VERSION "HINBNNNYYNNNYYNNNNNNNNNNNNYNNNYYYNNYNNNNNN/4//%%/4/'%**4NNN///"

NS_ :

BS_:

BU_: VirtualNMTMaster VCU

BO_ 1800 HBGuard_008: 1 VCU
 SG_ Toggle : 7|1@1+ (1,0) [0|0] "" Vector__XXX
 SG_ State : 0|7@1+ (1,0) [0|0] "" Vector__XXX

BO_ 1416 SSDO_008: 8 VCU
 SG_ Joe_6003_04 m4 : 32|16@1- (1,0) [-32768|32767] "" Vector__XXX
 SG_ Currly_6003_03 m3 : 32|16@1- (1,0) [-32768|32767] "" Vector__XXX
 SG_ Moe_6003_02 m2 : 32|16@1- (1,0) [-32768|32767] "" Vector__XXX
 SG_ Bob_6003_01 m1 : 32|16@1- (1,0) [-32768|32767] "" Vector__XXX
 SG_ UC_STATE_6003_00 m0 : 32|16@1- (1,0) [-32768|32767] "" Vector__XXX
 SG_ SubIndex_6003 m24579M : 24|8@1+ (1,0) [0|4] "" Vector__XXX
 SG_ Harp_Bit_3_6002_03 m3 : 32|1@1+ (1,0) [0|1] "" Vector__XXX
 SG_ Harp_Bit_2_6002_02 m2 : 32|1@1+ (1,0) [0|1] "" Vector__XXX
 SG_ Harp_Bit_1_6002_01 m1 : 32|1@1+ (1,0) [0|1] "" Vector__XXX
 SG_ Harp_Bit_0_6002_00 m0 : 32|1@1+ (1,0) [0|1] "" Vector__XXX
 SG_ SubIndex_6002 m24578M : 24|8@1+ (1,0) [0|3] "" Vector__XXX
 SG_ Throttle_6001_03 m3 : 32|16@1- (1,0) [-32768|32767] "" Vector__XXX
 SG_ Start_6001_02 m2 : 32|1@1+ (1,0) [0|1] "" Vector__XXX
 SG_ Brake_6001_01 m1 : 32|16@1- (1,0) [0|494967295] "" Vector__XXX
 SG_ Forward_Enable_6001_00 m0 : 32|1@1+ (1,0) [0|494967295] "" Vector__XXX
 SG_ SubIndex_6001 m24577M : 24|8@1+ (1,0) [0|3] "" Vector__XXX
 SG_ PDOMapEntry_1A03_01 m1 : 32|32@1+ (1,0) [0|4294967295] "" Vector__XXX
 SG_ NrOfEntries_1_1A03_00 m0 : 32|8@1+ (1,0) [0|2] "" Vector__XXX
 SG_ SubIndex_1A03 m6659M : 24|8@1+ (1,0) [0|1] "" Vector__XXX
 SG_ Transmit_PDO_Mapping_Parameter_0 m4 : 32|32@1+ (1,0) [0|4294967295] "" Vector__XXX
 SG_ PDOMapEntry_1A02_03 m3 : 32|32@1+ (1,0) [0|4294967295] "" Vector__XXX
 SG_ PDOMapEntry_1A02_02 m2 : 32|32@1+ (1,0) [0|4294967295] "" Vector__XXX
 SG_ PDOMapEntry_1A02_01 m1 : 32|32@1+ (1,0) [0|4294967295] "" Vector__XXX
 SG_ NrOfEntries_1_1A02_00 m0 : 32|8@1+ (1,0) [0|2] "" Vector__XXX
 SG_ SubIndex_1A02 m6658M : 24|8@1+ (1,0) [0|4] "" Vector__XXX
 SG_ Transmit_PDO_Mapping_Parame_0000 m4 : 32|32@1+ (1,0) [0|4294967295] "" Vector__XXX
 SG_ PDOMapEntry_1A01_03 m3 : 32|32@1+ (1,0) [0|4294967295] "" Vector__XXX
 SG_ PDOMapEntry_1A01_02 m2 : 32|32@1+ (1,0) [0|4294967295] "" Vector__XXX
 SG_ PDOMapEntry_1A01_01 m1 : 32|32@1+ (1,0) [0|4294967295] "" Vector__XXX
 SG_ NrOfEntries_1_1A01_00 m0 : 32|8@1+ (1,0) [0|2] "" Vector__XXX
 SG_ SubIndex_1A01 m6657M : 24|8@1+ (1,0) [0|4] "" Vector__XXX
 SG_ Transmit_PDO_Mapping_Parame_0001 m4 : 32|32@1+ (1,0) [0|4294967295] "" Vector__XXX
 SG_ Transmit_PDO_Mapping_Parame_0002 m3 : 32|32@1+ (1,0) [0|4294967295] "" Vector__XXX
 SG_ PDOMapEntry_2_1A00_02 m2 : 32|32@1+ (1,0) [0|4294967295] "" Vector__XXX
 SG_ PDOMapEntry_1_1A00_01 m1 : 32|32@1+ (1,0) [0|4294967295] "" Vector__XXX
 SG_ NrOfEntries_1_1A00_00 m0 : 32|8@1+ (1,0) [0|2] "" Vector__XXX
 SG_ SubIndex_1A00 m6656M : 24|8@1+ (1,0) [0|4] "" Vector__XXX
 SG_ SYNC_start_value_1803_06 m6 : 32|8@1+ (1,0) [0|255] "" Vector__XXX
 SG_ Event_Timer_1803_05 m5 : 32|16@1+ (1,0) [0|65535] "" Vector__XXX
 SG_ Compatibility_Entry_1803_04 m4 : 32|8@1+ (1,0) [0|255] "" Vector__XXX
 SG_ Inhibit_Time_1803_03 m3 : 32|16@1+ (1,0) [0|65535] "" Vector__XXX
 SG_ TransmissionType_1803_02 m2 : 32|8@1+ (1,0) [0|255] "" Vector__XXX
 SG_ COB_ID_1803_01 m1 : 32|32@1+ (1,0) [0|4294967295] "" Vector__XXX
 SG_ Highest_sub_index_supported_1803 m0 : 32|8@1+ (1,0) [2|6] "" Vector__XXX
 SG_ SubIndex_1803 m6147M : 24|8@1+ (1,0) [0|6] "" Vector__XXX
 SG_ SYNC_start_value_1802_06 m6 : 32|8@1+ (1,0) [0|255] "" Vector__XXX
 SG_ Event_Timer_1802_05 m5 : 32|16@1+ (1,0) [0|65535] "" Vector__XXX
 SG_ Compatibility_Entry_1802_04 m4 : 32|8@1+ (1,0) [0|255] "" Vector__XXX
 SG_ Inhibit_Time_1802_03 m3 : 32|16@1+ (1,0) [0|65535] "" Vector__XXX
 SG_ TransmissionType_1802_02 m2 : 32|8@1+ (1,0) [0|255] "" Vector__XXX
 SG_ COB_ID_1802_01 m1 : 32|32@1+ (1,0) [0|4294967295] "" Vector__XXX
 SG_ Highest_sub_index_supported_1802 m0 : 32|8@1+ (1,0) [2|6] "" Vector__XXX
 SG_ SubIndex_1802 m6146M : 24|8@1+ (1,0) [0|6] "" Vector__XXX
 SG_ SYNC_start_value_1801_06 m6 : 32|8@1+ (1,0) [0|255] "" Vector__XXX
 SG_ Event_Timer_1801_05 m5 : 32|16@1+ (1,0) [0|65535] "" Vector__XXX
 SG_ Compatibility_Entry_1801_04 m4 : 32|8@1+ (1,0) [0|255] "" Vector__XXX
 SG_ Inhibit_Time_1801_03 m3 : 32|16@1+ (1,0) [0|65535] "" Vector__XXX
 SG_ TransmissionType_1801_02 m2 : 32|8@1+ (1,0) [0|255] "" Vector__XXX
 SG_ COB_ID_1801_01 m1 : 32|32@1+ (1,0) [0|4294967295] "" Vector__XXX
 SG_ Highest_sub_index_supported_1801 m0 : 32|8@1+ (1,0) [2|6] "" Vector__XXX
 SG_ SubIndex_1801 m6145M : 24|8@1+ (1,0) [0|6] "" Vector__XXX
 SG_ SYNC_start_value_1800_06 m6 : 32|8@1+ (1,0) [0|255] "" Vector__XXX
 SG_ Event_Timer_1800_05 m5 : 32|16@1+ (1,0) [0|65535] "" Vector__XXX
 SG_ Compatibility_Entry_1800_04 m4 : 32|8@1+ (1,0) [0|255] "" Vector__XXX
 SG_ Inhibit_Time_1800_03 m3 : 32|16@1+ (1,0) [0|65535] "" Vector__XXX
 SG_ TransmissionType_1800_02 m2 : 32|8@1+ (1,0) [0|255] "" Vector__XXX
 SG_ COB_ID_1800_01 m1 : 32|32@1+ (1,0) [0|4294967295] "" Vector__XXX
 SG_ Highest_sub_index_supported_1800 m0 : 32|8@1+ (1,0) [2|6] "" Vector__XXX
 SG_ SubIndex_1800 m6144M : 24|8@1+ (1,0) [0|6] "" Vector__XXX
 SG_ Serial_number_1018_04 m4 : 32|32@1+ (1,0) [0|4294967295] "" Vector__XXX
 SG_ Revision_number_1018_03 m3 : 32|32@1+ (1,0) [0|4294967295] "" Vector__XXX
 SG_ Product_Code_1018_02 m2 : 32|32@1+ (1,0) [0|4294967295] "" Vector__XXX
 SG_ Vendor_Id_1018_01 m1 : 32|32@1+ (1,0) [0|4294967295] "" Vector__XXX
 SG_ Highest_sub_index_supported_1018 m0 : 32|8@1+ (1,0) [1|4] "" Vector__XXX
 SG_ SubIndex_1018 m4120M : 24|8@1+ (1,0) [0|4] "" Vector__XXX
 SG_ Error_Register_1001 m0 : 32|8@1+ (1,0) [0|255] "" Vector__XXX
 SG_ SubIndex_1001 m4097M : 24|8@1+ (1,0) [0|0] "" Vector__XXX
 SG_ Device_Type_1000 m0 : 32|32@1+ (1,0) [0|4294967295] "" Vector__XXX
 SG_ SubIndex_1000 m4096M : 24|8@1+ (1,0) [0|0] "" Vector__XXX
 SG_ Index m1M : 8|16@1+ (1,0) [4096|24579] "" Vector__XXX
 SG_ TransferType m1M : 1|1@1+ (1,0) [0|1] "" Vector__XXX
 SG_ NotUsedBytes m1 : 2|2@1+ (1,0) [0|3] "" Vector__XXX
 SG_ SizeIndicator m1 : 0|1@1+ (1,0) [0|1] "" Vector__XXX
 SG_ SCS M : 5|3@1+ (1,0) [0|6] "" Vector__XXX

BO_ 1544 CSDO_008: 8 Vector__XXX
 SG_ Joe_6003_04 m4 : 32|16@1- (1,0) [-32768|32767] ""  VCU
 SG_ Currly_6003_03 m3 : 32|16@1- (1,0) [-32768|32767] ""  VCU
 SG_ Moe_6003_02 m2 : 32|16@1- (1,0) [-32768|32767] ""  VCU
 SG_ Bob_6003_01 m1 : 32|16@1- (1,0) [-32768|32767] ""  VCU
 SG_ UC_STATE_6003_00 m0 : 32|16@1- (1,0) [-32768|32767] ""  VCU
 SG_ SubIndex_6003 m24579M : 24|8@1+ (1,0) [0|4] ""  VCU
 SG_ Harp_Bit_3_6002_03 m3 : 32|1@1+ (1,0) [0|1] ""  VCU
 SG_ Harp_Bit_2_6002_02 m2 : 32|1@1+ (1,0) [0|1] ""  VCU
 SG_ Harp_Bit_1_6002_01 m1 : 32|1@1+ (1,0) [0|1] ""  VCU
 SG_ Harp_Bit_0_6002_00 m0 : 32|1@1+ (1,0) [0|1] ""  VCU
 SG_ SubIndex_6002 m24578M : 24|8@1+ (1,0) [0|3] ""  VCU
 SG_ Throttle_6001_03 m3 : 32|16@1- (1,0) [-32768|32767] ""  VCU
 SG_ Start_6001_02 m2 : 32|1@1+ (1,0) [0|1] ""  VCU
 SG_ Brake_6001_01 m1 : 32|16@1- (1,0) [0|494967295] ""  VCU
 SG_ Forward_Enable_6001_00 m0 : 32|1@1+ (1,0) [0|494967295] ""  VCU
 SG_ SubIndex_6001 m24577M : 24|8@1+ (1,0) [0|3] ""  VCU
 SG_ PDOMapEntry_1A03_01 m1 : 32|32@1+ (1,0) [0|4294967295] ""  VCU
 SG_ NrOfEntries_1_1A03_00 m0 : 32|8@1+ (1,0) [0|2] ""  VCU
 SG_ SubIndex_1A03 m6659M : 24|8@1+ (1,0) [0|1] ""  VCU
 SG_ Transmit_PDO_Mapping_Parame_0003 m4 : 32|32@1+ (1,0) [0|4294967295] ""  VCU
 SG_ PDOMapEntry_1A02_03 m3 : 32|32@1+ (1,0) [0|4294967295] ""  VCU
 SG_ PDOMapEntry_1A02_02 m2 : 32|32@1+ (1,0) [0|4294967295] ""  VCU
 SG_ PDOMapEntry_1A02_01 m1 : 32|32@1+ (1,0) [0|4294967295] ""  VCU
 SG_ NrOfEntries_1_1A02_00 m0 : 32|8@1+ (1,0) [0|2] ""  VCU
 SG_ SubIndex_1A02 m6658M : 24|8@1+ (1,0) [0|4] ""  VCU
 SG_ Transmit_PDO_Mapping_Parame_0004 m4 : 32|32@1+ (1,0) [0|4294967295] ""  VCU
 SG_ PDOMapEntry_1A01_03 m3 : 32|32@1+ (1,0) [0|4294967295] ""  VCU
 SG_ PDOMapEntry_1A01_02 m2 : 32|32@1+ (1,0) [0|4294967295] ""  VCU
 SG_ PDOMapEntry_1A01_01 m1 : 32|32@1+ (1,0) [0|4294967295] ""  VCU
 SG_ NrOfEntries_1_1A01_00 m0 : 32|8@1+ (1,0) [0|2] ""  VCU
 SG_ SubIndex_1A01 m6657M : 24|8@1+ (1,0) [0|4] ""  VCU
 SG_ Transmit_PDO_Mapping_Parame_0005 m4 : 32|32@1+ (1,0) [0|4294967295] ""  VCU
 SG_ Transmit_PDO_Mapping_Parame_0006 m3 : 32|32@1+ (1,0) [0|4294967295] ""  VCU
 SG_ PDOMapEntry_2_1A00_02 m2 : 32|32@1+ (1,0) [0|4294967295] ""  VCU
 SG_ PDOMapEntry_1_1A00_01 m1 : 32|32@1+ (1,0) [0|4294967295] ""  VCU
 SG_ NrOfEntries_1_1A00_00 m0 : 32|8@1+ (1,0) [0|2] ""  VCU
 SG_ SubIndex_1A00 m6656M : 24|8@1+ (1,0) [0|4] ""  VCU
 SG_ SYNC_start_value_1803_06 m6 : 32|8@1+ (1,0) [0|255] ""  VCU
 SG_ Event_Timer_1803_05 m5 : 32|16@1+ (1,0) [0|65535] ""  VCU
 SG_ Compatibility_Entry_1803_04 m4 : 32|8@1+ (1,0) [0|255] ""  VCU
 SG_ Inhibit_Time_1803_03 m3 : 32|16@1+ (1,0) [0|65535] ""  VCU
 SG_ TransmissionType_1803_02 m2 : 32|8@1+ (1,0) [0|255] ""  VCU
 SG_ COB_ID_1803_01 m1 : 32|32@1+ (1,0) [0|4294967295] ""  VCU
 SG_ Highest_sub_index_supported_0000 m0 : 32|8@1+ (1,0) [2|6] ""  VCU
 SG_ SubIndex_1803 m6147M : 24|8@1+ (1,0) [0|6] ""  VCU
 SG_ SYNC_start_value_1802_06 m6 : 32|8@1+ (1,0) [0|255] ""  VCU
 SG_ Event_Timer_1802_05 m5 : 32|16@1+ (1,0) [0|65535] ""  VCU
 SG_ Compatibility_Entry_1802_04 m4 : 32|8@1+ (1,0) [0|255] ""  VCU
 SG_ Inhibit_Time_1802_03 m3 : 32|16@1+ (1,0) [0|65535] ""  VCU
 SG_ TransmissionType_1802_02 m2 : 32|8@1+ (1,0) [0|255] ""  VCU
 SG_ COB_ID_1802_01 m1 : 32|32@1+ (1,0) [0|4294967295] ""  VCU
 SG_ Highest_sub_index_supported_0001 m0 : 32|8@1+ (1,0) [2|6] ""  VCU
 SG_ SubIndex_1802 m6146M : 24|8@1+ (1,0) [0|6] ""  VCU
 SG_ SYNC_start_value_1801_06 m6 : 32|8@1+ (1,0) [0|255] ""  VCU
 SG_ Event_Timer_1801_05 m5 : 32|16@1+ (1,0) [0|65535] ""  VCU
 SG_ Compatibility_Entry_1801_04 m4 : 32|8@1+ (1,0) [0|255] ""  VCU
 SG_ Inhibit_Time_1801_03 m3 : 32|16@1+ (1,0) [0|65535] ""  VCU
 SG_ TransmissionType_1801_02 m2 : 32|8@1+ (1,0) [0|255] ""  VCU
 SG_ COB_ID_1801_01 m1 : 32|32@1+ (1,0) [0|4294967295] ""  VCU
 SG_ Highest_sub_index_supported_0002 m0 : 32|8@1+ (1,0) [2|6] ""  VCU
 SG_ SubIndex_1801 m6145M : 24|8@1+ (1,0) [0|6] ""  VCU
 SG_ SYNC_start_value_1800_06 m6 : 32|8@1+ (1,0) [0|255] ""  VCU
 SG_ Event_Timer_1800_05 m5 : 32|16@1+ (1,0) [0|65535] ""  VCU
 SG_ Compatibility_Entry_1800_04 m4 : 32|8@1+ (1,0) [0|255] ""  VCU
 SG_ Inhibit_Time_1800_03 m3 : 32|16@1+ (1,0) [0|65535] ""  VCU
 SG_ TransmissionType_1800_02 m2 : 32|8@1+ (1,0) [0|255] ""  VCU
 SG_ COB_ID_1800_01 m1 : 32|32@1+ (1,0) [0|4294967295] ""  VCU
 SG_ Highest_sub_index_supported_0003 m0 : 32|8@1+ (1,0) [2|6] ""  VCU
 SG_ SubIndex_1800 m6144M : 24|8@1+ (1,0) [0|6] ""  VCU
 SG_ Serial_number_1018_04 m4 : 32|32@1+ (1,0) [0|4294967295] ""  VCU
 SG_ Revision_number_1018_03 m3 : 32|32@1+ (1,0) [0|4294967295] ""  VCU
 SG_ Product_Code_1018_02 m2 : 32|32@1+ (1,0) [0|4294967295] ""  VCU
 SG_ Vendor_Id_1018_01 m1 : 32|32@1+ (1,0) [0|4294967295] ""  VCU
 SG_ Highest_sub_index_supported_0004 m0 : 32|8@1+ (1,0) [1|4] ""  VCU
 SG_ SubIndex_1018 m4120M : 24|8@1+ (1,0) [0|4] ""  VCU
 SG_ Error_Register_1001 m0 : 32|8@1+ (1,0) [0|255] ""  VCU
 SG_ SubIndex_1001 m4097M : 24|8@1+ (1,0) [0|0] ""  VCU
 SG_ Device_Type_1000 m0 : 32|32@1+ (1,0) [0|4294967295] ""  VCU
 SG_ SubIndex_1000 m4096M : 24|8@1+ (1,0) [0|0] ""  VCU
 SG_ Index m1M : 8|16@1+ (1,0) [4096|24579] ""  VCU
 SG_ TransferType m1M : 1|1@1+ (1,0) [0|1] ""  VCU
 SG_ NotUsedBytes m1 : 2|2@1+ (1,0) [0|3] ""  VCU
 SG_ SizeIndicator m1 : 0|1@1+ (1,0) [0|1] ""  VCU
 SG_ CCS M : 5|3@1+ (1,0) [0|6] ""  VCU

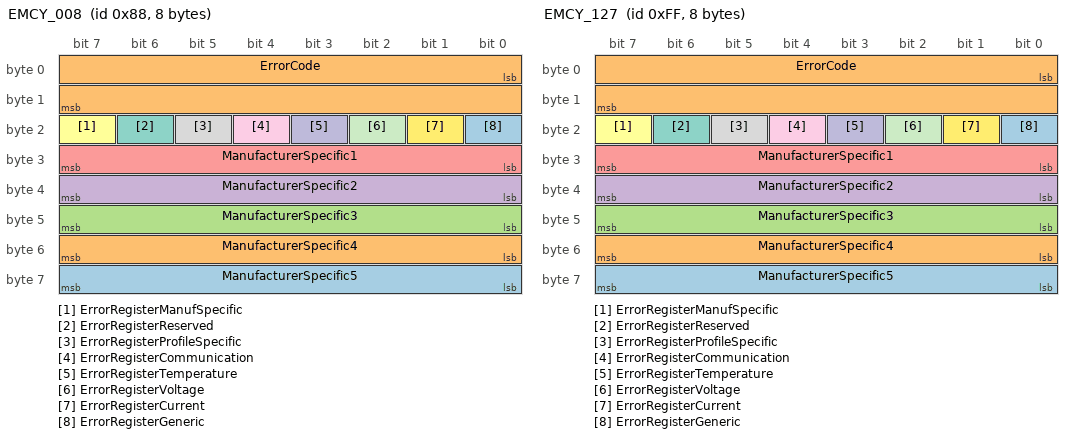
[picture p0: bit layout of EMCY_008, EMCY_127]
BO_ 136 EMCY_008: 8 VCU
 SG_ ManufacturerSpecific5 : 56|8@1+ (1,0) [0|0] "" Vector__XXX
 SG_ ManufacturerSpecific4 : 48|8@1+ (1,0) [0|0] "" Vector__XXX
 SG_ ManufacturerSpecific3 : 40|8@1+ (1,0) [0|0] "" Vector__XXX
 SG_ ManufacturerSpecific2 : 32|8@1+ (1,0) [0|0] "" Vector__XXX
 SG_ ManufacturerSpecific1 : 24|8@1+ (1,0) [0|0] "" Vector__XXX
 SG_ ErrorRegisterManufSpecific : 23|1@1+ (1,0) [0|0] "" Vector__XXX
 SG_ ErrorRegisterReserved : 22|1@1+ (1,0) [0|0] "" Vector__XXX
 SG_ ErrorRegisterProfileSpecific : 21|1@1+ (1,0) [0|0] "" Vector__XXX
 SG_ ErrorRegisterCommunication : 20|1@1+ (1,0) [0|0] "" Vector__XXX
 SG_ ErrorRegisterTemperature : 19|1@1+ (1,0) [0|0] "" Vector__XXX
 SG_ ErrorRegisterVoltage : 18|1@1+ (1,0) [0|0] "" Vector__XXX
 SG_ ErrorRegisterCurrent : 17|1@1+ (1,0) [0|0] "" Vector__XXX
 SG_ ErrorRegisterGeneric : 16|1@1+ (1,0) [0|0] "" Vector__XXX
 SG_ ErrorCode : 0|16@1+ (1,0) [0|0] "" Vector__XXX

BO_ 1919 HBGuard_127: 1 Vector__XXX
 SG_ Toggle : 7|1@1+ (1,0) [0|0] "" Vector__XXX
 SG_ State : 0|7@1+ (1,0) [0|0] "" Vector__XXX

BO_ 1535 SSDO_127: 8 Vector__XXX

BO_ 1663 CSDO_127: 8 Vector__XXX

BO_ 255 EMCY_127: 8 Vector__XXX
 SG_ ManufacturerSpecific5 : 56|8@1+ (1,0) [0|0] "" Vector__XXX
 SG_ ManufacturerSpecific4 : 48|8@1+ (1,0) [0|0] "" Vector__XXX
 SG_ ManufacturerSpecific3 : 40|8@1+ (1,0) [0|0] "" Vector__XXX
 SG_ ManufacturerSpecific2 : 32|8@1+ (1,0) [0|0] "" Vector__XXX
 SG_ ManufacturerSpecific1 : 24|8@1+ (1,0) [0|0] "" Vector__XXX
 SG_ ErrorRegisterManufSpecific : 23|1@1+ (1,0) [0|0] "" Vector__XXX
 SG_ ErrorRegisterReserved : 22|1@1+ (1,0) [0|0] "" Vector__XXX
 SG_ ErrorRegisterProfileSpecific : 21|1@1+ (1,0) [0|0] "" Vector__XXX
 SG_ ErrorRegisterCommunication : 20|1@1+ (1,0) [0|0] "" Vector__XXX
 SG_ ErrorRegisterTemperature : 19|1@1+ (1,0) [0|0] "" Vector__XXX
 SG_ ErrorRegisterVoltage : 18|1@1+ (1,0) [0|0] "" Vector__XXX
 SG_ ErrorRegisterCurrent : 17|1@1+ (1,0) [0|0] "" Vector__XXX
 SG_ ErrorRegisterGeneric : 16|1@1+ (1,0) [0|0] "" Vector__XXX
 SG_ ErrorCode : 0|16@1+ (1,0) [0|0] "" Vector__XXX

BO_ 1918 HBGuard_126: 1 Vector__XXX
 SG_ Toggle : 7|1@1+ (1,0) [0|0] "" Vector__XXX
 SG_ State : 0|7@1+ (1,0) [0|0] "" Vector__XXX

BO_ 1534 SSDO_126: 8 Vector__XXX

BO_ 1662 CSDO_126: 8 Vector__XXX

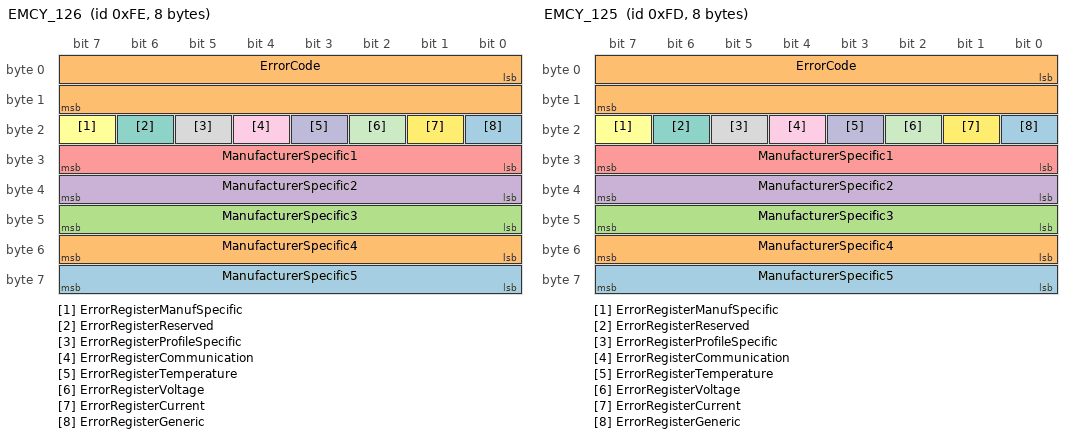
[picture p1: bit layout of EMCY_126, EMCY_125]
BO_ 254 EMCY_126: 8 Vector__XXX
 SG_ ManufacturerSpecific5 : 56|8@1+ (1,0) [0|0] "" Vector__XXX
 SG_ ManufacturerSpecific4 : 48|8@1+ (1,0) [0|0] "" Vector__XXX
 SG_ ManufacturerSpecific3 : 40|8@1+ (1,0) [0|0] "" Vector__XXX
 SG_ ManufacturerSpecific2 : 32|8@1+ (1,0) [0|0] "" Vector__XXX
 SG_ ManufacturerSpecific1 : 24|8@1+ (1,0) [0|0] "" Vector__XXX
 SG_ ErrorRegisterManufSpecific : 23|1@1+ (1,0) [0|0] "" Vector__XXX
 SG_ ErrorRegisterReserved : 22|1@1+ (1,0) [0|0] "" Vector__XXX
 SG_ ErrorRegisterProfileSpecific : 21|1@1+ (1,0) [0|0] "" Vector__XXX
 SG_ ErrorRegisterCommunication : 20|1@1+ (1,0) [0|0] "" Vector__XXX
 SG_ ErrorRegisterTemperature : 19|1@1+ (1,0) [0|0] "" Vector__XXX
 SG_ ErrorRegisterVoltage : 18|1@1+ (1,0) [0|0] "" Vector__XXX
 SG_ ErrorRegisterCurrent : 17|1@1+ (1,0) [0|0] "" Vector__XXX
 SG_ ErrorRegisterGeneric : 16|1@1+ (1,0) [0|0] "" Vector__XXX
 SG_ ErrorCode : 0|16@1+ (1,0) [0|0] "" Vector__XXX

BO_ 1917 HBGuard_125: 1 Vector__XXX
 SG_ Toggle : 7|1@1+ (1,0) [0|0] "" Vector__XXX
 SG_ State : 0|7@1+ (1,0) [0|0] "" Vector__XXX

BO_ 1533 SSDO_125: 8 Vector__XXX

BO_ 1661 CSDO_125: 8 Vector__XXX

BO_ 253 EMCY_125: 8 Vector__XXX
 SG_ ManufacturerSpecific5 : 56|8@1+ (1,0) [0|0] "" Vector__XXX
 SG_ ManufacturerSpecific4 : 48|8@1+ (1,0) [0|0] "" Vector__XXX
 SG_ ManufacturerSpecific3 : 40|8@1+ (1,0) [0|0] "" Vector__XXX
 SG_ ManufacturerSpecific2 : 32|8@1+ (1,0) [0|0] "" Vector__XXX
 SG_ ManufacturerSpecific1 : 24|8@1+ (1,0) [0|0] "" Vector__XXX
 SG_ ErrorRegisterManufSpecific : 23|1@1+ (1,0) [0|0] "" Vector__XXX
 SG_ ErrorRegisterReserved : 22|1@1+ (1,0) [0|0] "" Vector__XXX
 SG_ ErrorRegisterProfileSpecific : 21|1@1+ (1,0) [0|0] "" Vector__XXX
 SG_ ErrorRegisterCommunication : 20|1@1+ (1,0) [0|0] "" Vector__XXX
 SG_ ErrorRegisterTemperature : 19|1@1+ (1,0) [0|0] "" Vector__XXX
 SG_ ErrorRegisterVoltage : 18|1@1+ (1,0) [0|0] "" Vector__XXX
 SG_ ErrorRegisterCurrent : 17|1@1+ (1,0) [0|0] "" Vector__XXX
 SG_ ErrorRegisterGeneric : 16|1@1+ (1,0) [0|0] "" Vector__XXX
 SG_ ErrorCode : 0|16@1+ (1,0) [0|0] "" Vector__XXX

BO_ 1916 HBGuard_124: 1 Vector__XXX
 SG_ Toggle : 7|1@1+ (1,0) [0|0] "" Vector__XXX
 SG_ State : 0|7@1+ (1,0) [0|0] "" Vector__XXX

BO_ 1532 SSDO_124: 8 Vector__XXX

BO_ 1660 CSDO_124: 8 Vector__XXX

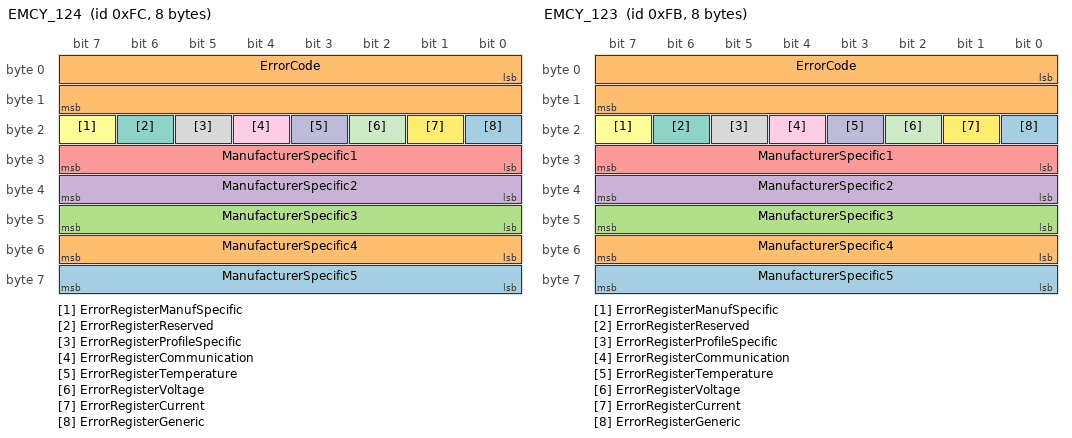
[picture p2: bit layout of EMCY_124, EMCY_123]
BO_ 252 EMCY_124: 8 Vector__XXX
 SG_ ManufacturerSpecific5 : 56|8@1+ (1,0) [0|0] "" Vector__XXX
 SG_ ManufacturerSpecific4 : 48|8@1+ (1,0) [0|0] "" Vector__XXX
 SG_ ManufacturerSpecific3 : 40|8@1+ (1,0) [0|0] "" Vector__XXX
 SG_ ManufacturerSpecific2 : 32|8@1+ (1,0) [0|0] "" Vector__XXX
 SG_ ManufacturerSpecific1 : 24|8@1+ (1,0) [0|0] "" Vector__XXX
 SG_ ErrorRegisterManufSpecific : 23|1@1+ (1,0) [0|0] "" Vector__XXX
 SG_ ErrorRegisterReserved : 22|1@1+ (1,0) [0|0] "" Vector__XXX
 SG_ ErrorRegisterProfileSpecific : 21|1@1+ (1,0) [0|0] "" Vector__XXX
 SG_ ErrorRegisterCommunication : 20|1@1+ (1,0) [0|0] "" Vector__XXX
 SG_ ErrorRegisterTemperature : 19|1@1+ (1,0) [0|0] "" Vector__XXX
 SG_ ErrorRegisterVoltage : 18|1@1+ (1,0) [0|0] "" Vector__XXX
 SG_ ErrorRegisterCurrent : 17|1@1+ (1,0) [0|0] "" Vector__XXX
 SG_ ErrorRegisterGeneric : 16|1@1+ (1,0) [0|0] "" Vector__XXX
 SG_ ErrorCode : 0|16@1+ (1,0) [0|0] "" Vector__XXX

BO_ 1915 HBGuard_123: 1 Vector__XXX
 SG_ Toggle : 7|1@1+ (1,0) [0|0] "" Vector__XXX
 SG_ State : 0|7@1+ (1,0) [0|0] "" Vector__XXX

BO_ 1531 SSDO_123: 8 Vector__XXX

BO_ 1659 CSDO_123: 8 Vector__XXX

BO_ 251 EMCY_123: 8 Vector__XXX
 SG_ ManufacturerSpecific5 : 56|8@1+ (1,0) [0|0] "" Vector__XXX
 SG_ ManufacturerSpecific4 : 48|8@1+ (1,0) [0|0] "" Vector__XXX
 SG_ ManufacturerSpecific3 : 40|8@1+ (1,0) [0|0] "" Vector__XXX
 SG_ ManufacturerSpecific2 : 32|8@1+ (1,0) [0|0] "" Vector__XXX
 SG_ ManufacturerSpecific1 : 24|8@1+ (1,0) [0|0] "" Vector__XXX
 SG_ ErrorRegisterManufSpecific : 23|1@1+ (1,0) [0|0] "" Vector__XXX
 SG_ ErrorRegisterReserved : 22|1@1+ (1,0) [0|0] "" Vector__XXX
 SG_ ErrorRegisterProfileSpecific : 21|1@1+ (1,0) [0|0] "" Vector__XXX
 SG_ ErrorRegisterCommunication : 20|1@1+ (1,0) [0|0] "" Vector__XXX
 SG_ ErrorRegisterTemperature : 19|1@1+ (1,0) [0|0] "" Vector__XXX
 SG_ ErrorRegisterVoltage : 18|1@1+ (1,0) [0|0] "" Vector__XXX
 SG_ ErrorRegisterCurrent : 17|1@1+ (1,0) [0|0] "" Vector__XXX
 SG_ ErrorRegisterGeneric : 16|1@1+ (1,0) [0|0] "" Vector__XXX
 SG_ ErrorCode : 0|16@1+ (1,0) [0|0] "" Vector__XXX

BO_ 1914 HBGuard_122: 1 Vector__XXX
 SG_ Toggle : 7|1@1+ (1,0) [0|0] "" Vector__XXX
 SG_ State : 0|7@1+ (1,0) [0|0] "" Vector__XXX

BO_ 1530 SSDO_122: 8 Vector__XXX

BO_ 1658 CSDO_122: 8 Vector__XXX

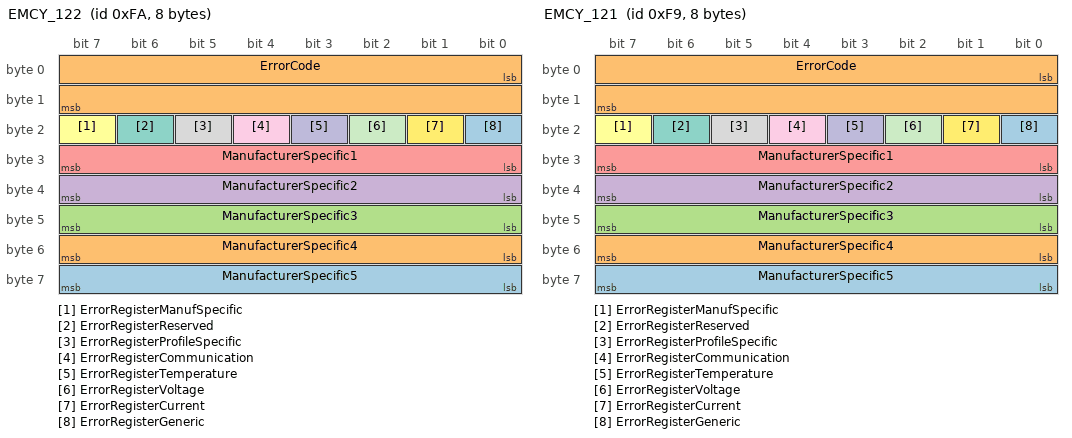
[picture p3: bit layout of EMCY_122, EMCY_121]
BO_ 250 EMCY_122: 8 Vector__XXX
 SG_ ManufacturerSpecific5 : 56|8@1+ (1,0) [0|0] "" Vector__XXX
 SG_ ManufacturerSpecific4 : 48|8@1+ (1,0) [0|0] "" Vector__XXX
 SG_ ManufacturerSpecific3 : 40|8@1+ (1,0) [0|0] "" Vector__XXX
 SG_ ManufacturerSpecific2 : 32|8@1+ (1,0) [0|0] "" Vector__XXX
 SG_ ManufacturerSpecific1 : 24|8@1+ (1,0) [0|0] "" Vector__XXX
 SG_ ErrorRegisterManufSpecific : 23|1@1+ (1,0) [0|0] "" Vector__XXX
 SG_ ErrorRegisterReserved : 22|1@1+ (1,0) [0|0] "" Vector__XXX
 SG_ ErrorRegisterProfileSpecific : 21|1@1+ (1,0) [0|0] "" Vector__XXX
 SG_ ErrorRegisterCommunication : 20|1@1+ (1,0) [0|0] "" Vector__XXX
 SG_ ErrorRegisterTemperature : 19|1@1+ (1,0) [0|0] "" Vector__XXX
 SG_ ErrorRegisterVoltage : 18|1@1+ (1,0) [0|0] "" Vector__XXX
 SG_ ErrorRegisterCurrent : 17|1@1+ (1,0) [0|0] "" Vector__XXX
 SG_ ErrorRegisterGeneric : 16|1@1+ (1,0) [0|0] "" Vector__XXX
 SG_ ErrorCode : 0|16@1+ (1,0) [0|0] "" Vector__XXX

BO_ 1913 HBGuard_121: 1 Vector__XXX
 SG_ Toggle : 7|1@1+ (1,0) [0|0] "" Vector__XXX
 SG_ State : 0|7@1+ (1,0) [0|0] "" Vector__XXX

BO_ 1529 SSDO_121: 8 Vector__XXX

BO_ 1657 CSDO_121: 8 Vector__XXX

BO_ 249 EMCY_121: 8 Vector__XXX
 SG_ ManufacturerSpecific5 : 56|8@1+ (1,0) [0|0] "" Vector__XXX
 SG_ ManufacturerSpecific4 : 48|8@1+ (1,0) [0|0] "" Vector__XXX
 SG_ ManufacturerSpecific3 : 40|8@1+ (1,0) [0|0] "" Vector__XXX
 SG_ ManufacturerSpecific2 : 32|8@1+ (1,0) [0|0] "" Vector__XXX
 SG_ ManufacturerSpecific1 : 24|8@1+ (1,0) [0|0] "" Vector__XXX
 SG_ ErrorRegisterManufSpecific : 23|1@1+ (1,0) [0|0] "" Vector__XXX
 SG_ ErrorRegisterReserved : 22|1@1+ (1,0) [0|0] "" Vector__XXX
 SG_ ErrorRegisterProfileSpecific : 21|1@1+ (1,0) [0|0] "" Vector__XXX
 SG_ ErrorRegisterCommunication : 20|1@1+ (1,0) [0|0] "" Vector__XXX
 SG_ ErrorRegisterTemperature : 19|1@1+ (1,0) [0|0] "" Vector__XXX
 SG_ ErrorRegisterVoltage : 18|1@1+ (1,0) [0|0] "" Vector__XXX
 SG_ ErrorRegisterCurrent : 17|1@1+ (1,0) [0|0] "" Vector__XXX
 SG_ ErrorRegisterGeneric : 16|1@1+ (1,0) [0|0] "" Vector__XXX
 SG_ ErrorCode : 0|16@1+ (1,0) [0|0] "" Vector__XXX

BO_ 1912 HBGuard_120: 1 Vector__XXX
 SG_ Toggle : 7|1@1+ (1,0) [0|0] "" Vector__XXX
 SG_ State : 0|7@1+ (1,0) [0|0] "" Vector__XXX

BO_ 1528 SSDO_120: 8 Vector__XXX

BO_ 1656 CSDO_120: 8 Vector__XXX

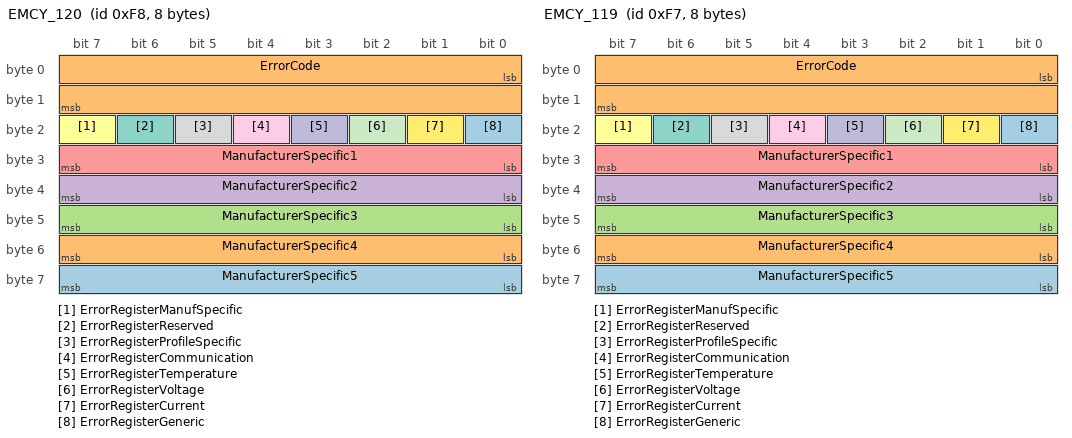
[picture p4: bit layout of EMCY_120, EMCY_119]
BO_ 248 EMCY_120: 8 Vector__XXX
 SG_ ManufacturerSpecific5 : 56|8@1+ (1,0) [0|0] "" Vector__XXX
 SG_ ManufacturerSpecific4 : 48|8@1+ (1,0) [0|0] "" Vector__XXX
 SG_ ManufacturerSpecific3 : 40|8@1+ (1,0) [0|0] "" Vector__XXX
 SG_ ManufacturerSpecific2 : 32|8@1+ (1,0) [0|0] "" Vector__XXX
 SG_ ManufacturerSpecific1 : 24|8@1+ (1,0) [0|0] "" Vector__XXX
 SG_ ErrorRegisterManufSpecific : 23|1@1+ (1,0) [0|0] "" Vector__XXX
 SG_ ErrorRegisterReserved : 22|1@1+ (1,0) [0|0] "" Vector__XXX
 SG_ ErrorRegisterProfileSpecific : 21|1@1+ (1,0) [0|0] "" Vector__XXX
 SG_ ErrorRegisterCommunication : 20|1@1+ (1,0) [0|0] "" Vector__XXX
 SG_ ErrorRegisterTemperature : 19|1@1+ (1,0) [0|0] "" Vector__XXX
 SG_ ErrorRegisterVoltage : 18|1@1+ (1,0) [0|0] "" Vector__XXX
 SG_ ErrorRegisterCurrent : 17|1@1+ (1,0) [0|0] "" Vector__XXX
 SG_ ErrorRegisterGeneric : 16|1@1+ (1,0) [0|0] "" Vector__XXX
 SG_ ErrorCode : 0|16@1+ (1,0) [0|0] "" Vector__XXX

BO_ 1911 HBGuard_119: 1 Vector__XXX
 SG_ Toggle : 7|1@1+ (1,0) [0|0] "" Vector__XXX
 SG_ State : 0|7@1+ (1,0) [0|0] "" Vector__XXX

BO_ 1527 SSDO_119: 8 Vector__XXX

BO_ 1655 CSDO_119: 8 Vector__XXX

BO_ 247 EMCY_119: 8 Vector__XXX
 SG_ ManufacturerSpecific5 : 56|8@1+ (1,0) [0|0] "" Vector__XXX
 SG_ ManufacturerSpecific4 : 48|8@1+ (1,0) [0|0] "" Vector__XXX
 SG_ ManufacturerSpecific3 : 40|8@1+ (1,0) [0|0] "" Vector__XXX
 SG_ ManufacturerSpecific2 : 32|8@1+ (1,0) [0|0] "" Vector__XXX
 SG_ ManufacturerSpecific1 : 24|8@1+ (1,0) [0|0] "" Vector__XXX
 SG_ ErrorRegisterManufSpecific : 23|1@1+ (1,0) [0|0] "" Vector__XXX
 SG_ ErrorRegisterReserved : 22|1@1+ (1,0) [0|0] "" Vector__XXX
 SG_ ErrorRegisterProfileSpecific : 21|1@1+ (1,0) [0|0] "" Vector__XXX
 SG_ ErrorRegisterCommunication : 20|1@1+ (1,0) [0|0] "" Vector__XXX
 SG_ ErrorRegisterTemperature : 19|1@1+ (1,0) [0|0] "" Vector__XXX
 SG_ ErrorRegisterVoltage : 18|1@1+ (1,0) [0|0] "" Vector__XXX
 SG_ ErrorRegisterCurrent : 17|1@1+ (1,0) [0|0] "" Vector__XXX
 SG_ ErrorRegisterGeneric : 16|1@1+ (1,0) [0|0] "" Vector__XXX
 SG_ ErrorCode : 0|16@1+ (1,0) [0|0] "" Vector__XXX

BO_ 1910 HBGuard_118: 1 Vector__XXX
 SG_ Toggle : 7|1@1+ (1,0) [0|0] "" Vector__XXX
 SG_ State : 0|7@1+ (1,0) [0|0] "" Vector__XXX

BO_ 1526 SSDO_118: 8 Vector__XXX

BO_ 1654 CSDO_118: 8 Vector__XXX

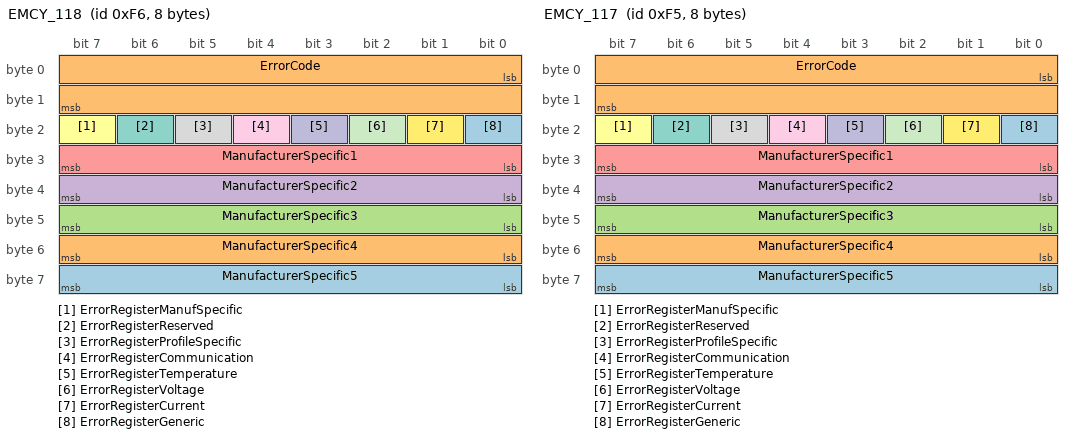
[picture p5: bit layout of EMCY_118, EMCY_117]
BO_ 246 EMCY_118: 8 Vector__XXX
 SG_ ManufacturerSpecific5 : 56|8@1+ (1,0) [0|0] "" Vector__XXX
 SG_ ManufacturerSpecific4 : 48|8@1+ (1,0) [0|0] "" Vector__XXX
 SG_ ManufacturerSpecific3 : 40|8@1+ (1,0) [0|0] "" Vector__XXX
 SG_ ManufacturerSpecific2 : 32|8@1+ (1,0) [0|0] "" Vector__XXX
 SG_ ManufacturerSpecific1 : 24|8@1+ (1,0) [0|0] "" Vector__XXX
 SG_ ErrorRegisterManufSpecific : 23|1@1+ (1,0) [0|0] "" Vector__XXX
 SG_ ErrorRegisterReserved : 22|1@1+ (1,0) [0|0] "" Vector__XXX
 SG_ ErrorRegisterProfileSpecific : 21|1@1+ (1,0) [0|0] "" Vector__XXX
 SG_ ErrorRegisterCommunication : 20|1@1+ (1,0) [0|0] "" Vector__XXX
 SG_ ErrorRegisterTemperature : 19|1@1+ (1,0) [0|0] "" Vector__XXX
 SG_ ErrorRegisterVoltage : 18|1@1+ (1,0) [0|0] "" Vector__XXX
 SG_ ErrorRegisterCurrent : 17|1@1+ (1,0) [0|0] "" Vector__XXX
 SG_ ErrorRegisterGeneric : 16|1@1+ (1,0) [0|0] "" Vector__XXX
 SG_ ErrorCode : 0|16@1+ (1,0) [0|0] "" Vector__XXX

BO_ 1909 HBGuard_117: 1 Vector__XXX
 SG_ Toggle : 7|1@1+ (1,0) [0|0] "" Vector__XXX
 SG_ State : 0|7@1+ (1,0) [0|0] "" Vector__XXX

BO_ 1525 SSDO_117: 8 Vector__XXX

BO_ 1653 CSDO_117: 8 Vector__XXX

BO_ 245 EMCY_117: 8 Vector__XXX
 SG_ ManufacturerSpecific5 : 56|8@1+ (1,0) [0|0] "" Vector__XXX
 SG_ ManufacturerSpecific4 : 48|8@1+ (1,0) [0|0] "" Vector__XXX
 SG_ ManufacturerSpecific3 : 40|8@1+ (1,0) [0|0] "" Vector__XXX
 SG_ ManufacturerSpecific2 : 32|8@1+ (1,0) [0|0] "" Vector__XXX
 SG_ ManufacturerSpecific1 : 24|8@1+ (1,0) [0|0] "" Vector__XXX
 SG_ ErrorRegisterManufSpecific : 23|1@1+ (1,0) [0|0] "" Vector__XXX
 SG_ ErrorRegisterReserved : 22|1@1+ (1,0) [0|0] "" Vector__XXX
 SG_ ErrorRegisterProfileSpecific : 21|1@1+ (1,0) [0|0] "" Vector__XXX
 SG_ ErrorRegisterCommunication : 20|1@1+ (1,0) [0|0] "" Vector__XXX
 SG_ ErrorRegisterTemperature : 19|1@1+ (1,0) [0|0] "" Vector__XXX
 SG_ ErrorRegisterVoltage : 18|1@1+ (1,0) [0|0] "" Vector__XXX
 SG_ ErrorRegisterCurrent : 17|1@1+ (1,0) [0|0] "" Vector__XXX
 SG_ ErrorRegisterGeneric : 16|1@1+ (1,0) [0|0] "" Vector__XXX
 SG_ ErrorCode : 0|16@1+ (1,0) [0|0] "" Vector__XXX

BO_ 1908 HBGuard_116: 1 Vector__XXX
 SG_ Toggle : 7|1@1+ (1,0) [0|0] "" Vector__XXX
 SG_ State : 0|7@1+ (1,0) [0|0] "" Vector__XXX

BO_ 1524 SSDO_116: 8 Vector__XXX

BO_ 1652 CSDO_116: 8 Vector__XXX

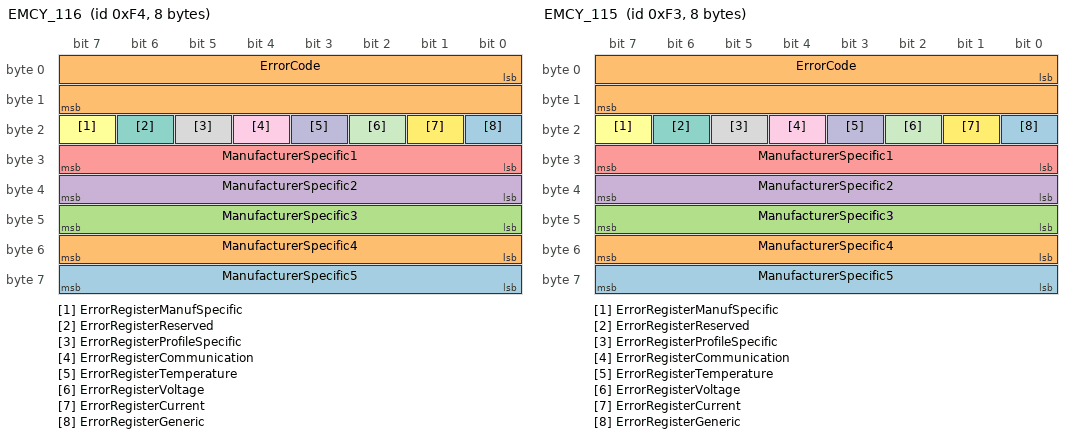
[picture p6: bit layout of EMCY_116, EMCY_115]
BO_ 244 EMCY_116: 8 Vector__XXX
 SG_ ManufacturerSpecific5 : 56|8@1+ (1,0) [0|0] "" Vector__XXX
 SG_ ManufacturerSpecific4 : 48|8@1+ (1,0) [0|0] "" Vector__XXX
 SG_ ManufacturerSpecific3 : 40|8@1+ (1,0) [0|0] "" Vector__XXX
 SG_ ManufacturerSpecific2 : 32|8@1+ (1,0) [0|0] "" Vector__XXX
 SG_ ManufacturerSpecific1 : 24|8@1+ (1,0) [0|0] "" Vector__XXX
 SG_ ErrorRegisterManufSpecific : 23|1@1+ (1,0) [0|0] "" Vector__XXX
 SG_ ErrorRegisterReserved : 22|1@1+ (1,0) [0|0] "" Vector__XXX
 SG_ ErrorRegisterProfileSpecific : 21|1@1+ (1,0) [0|0] "" Vector__XXX
 SG_ ErrorRegisterCommunication : 20|1@1+ (1,0) [0|0] "" Vector__XXX
 SG_ ErrorRegisterTemperature : 19|1@1+ (1,0) [0|0] "" Vector__XXX
 SG_ ErrorRegisterVoltage : 18|1@1+ (1,0) [0|0] "" Vector__XXX
 SG_ ErrorRegisterCurrent : 17|1@1+ (1,0) [0|0] "" Vector__XXX
 SG_ ErrorRegisterGeneric : 16|1@1+ (1,0) [0|0] "" Vector__XXX
 SG_ ErrorCode : 0|16@1+ (1,0) [0|0] "" Vector__XXX

BO_ 1907 HBGuard_115: 1 Vector__XXX
 SG_ Toggle : 7|1@1+ (1,0) [0|0] "" Vector__XXX
 SG_ State : 0|7@1+ (1,0) [0|0] "" Vector__XXX

BO_ 1523 SSDO_115: 8 Vector__XXX

BO_ 1651 CSDO_115: 8 Vector__XXX

BO_ 243 EMCY_115: 8 Vector__XXX
 SG_ ManufacturerSpecific5 : 56|8@1+ (1,0) [0|0] "" Vector__XXX
 SG_ ManufacturerSpecific4 : 48|8@1+ (1,0) [0|0] "" Vector__XXX
 SG_ ManufacturerSpecific3 : 40|8@1+ (1,0) [0|0] "" Vector__XXX
 SG_ ManufacturerSpecific2 : 32|8@1+ (1,0) [0|0] "" Vector__XXX
 SG_ ManufacturerSpecific1 : 24|8@1+ (1,0) [0|0] "" Vector__XXX
 SG_ ErrorRegisterManufSpecific : 23|1@1+ (1,0) [0|0] "" Vector__XXX
 SG_ ErrorRegisterReserved : 22|1@1+ (1,0) [0|0] "" Vector__XXX
 SG_ ErrorRegisterProfileSpecific : 21|1@1+ (1,0) [0|0] "" Vector__XXX
 SG_ ErrorRegisterCommunication : 20|1@1+ (1,0) [0|0] "" Vector__XXX
 SG_ ErrorRegisterTemperature : 19|1@1+ (1,0) [0|0] "" Vector__XXX
 SG_ ErrorRegisterVoltage : 18|1@1+ (1,0) [0|0] "" Vector__XXX
 SG_ ErrorRegisterCurrent : 17|1@1+ (1,0) [0|0] "" Vector__XXX
 SG_ ErrorRegisterGeneric : 16|1@1+ (1,0) [0|0] "" Vector__XXX
 SG_ ErrorCode : 0|16@1+ (1,0) [0|0] "" Vector__XXX

BO_ 1906 HBGuard_114: 1 Vector__XXX
 SG_ Toggle : 7|1@1+ (1,0) [0|0] "" Vector__XXX
 SG_ State : 0|7@1+ (1,0) [0|0] "" Vector__XXX

BO_ 1522 SSDO_114: 8 Vector__XXX

BO_ 1650 CSDO_114: 8 Vector__XXX

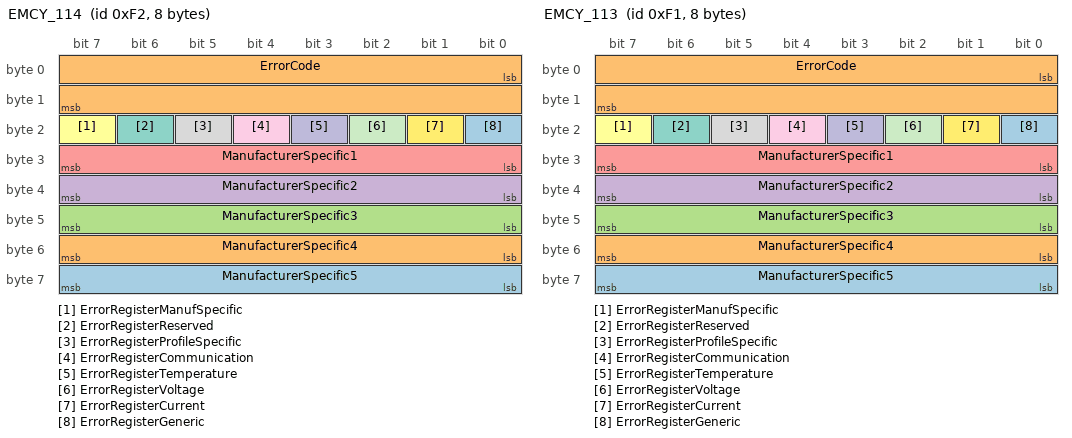
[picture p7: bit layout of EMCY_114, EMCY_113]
BO_ 242 EMCY_114: 8 Vector__XXX
 SG_ ManufacturerSpecific5 : 56|8@1+ (1,0) [0|0] "" Vector__XXX
 SG_ ManufacturerSpecific4 : 48|8@1+ (1,0) [0|0] "" Vector__XXX
 SG_ ManufacturerSpecific3 : 40|8@1+ (1,0) [0|0] "" Vector__XXX
 SG_ ManufacturerSpecific2 : 32|8@1+ (1,0) [0|0] "" Vector__XXX
 SG_ ManufacturerSpecific1 : 24|8@1+ (1,0) [0|0] "" Vector__XXX
 SG_ ErrorRegisterManufSpecific : 23|1@1+ (1,0) [0|0] "" Vector__XXX
 SG_ ErrorRegisterReserved : 22|1@1+ (1,0) [0|0] "" Vector__XXX
 SG_ ErrorRegisterProfileSpecific : 21|1@1+ (1,0) [0|0] "" Vector__XXX
 SG_ ErrorRegisterCommunication : 20|1@1+ (1,0) [0|0] "" Vector__XXX
 SG_ ErrorRegisterTemperature : 19|1@1+ (1,0) [0|0] "" Vector__XXX
 SG_ ErrorRegisterVoltage : 18|1@1+ (1,0) [0|0] "" Vector__XXX
 SG_ ErrorRegisterCurrent : 17|1@1+ (1,0) [0|0] "" Vector__XXX
 SG_ ErrorRegisterGeneric : 16|1@1+ (1,0) [0|0] "" Vector__XXX
 SG_ ErrorCode : 0|16@1+ (1,0) [0|0] "" Vector__XXX

BO_ 1905 HBGuard_113: 1 Vector__XXX
 SG_ Toggle : 7|1@1+ (1,0) [0|0] "" Vector__XXX
 SG_ State : 0|7@1+ (1,0) [0|0] "" Vector__XXX

BO_ 1521 SSDO_113: 8 Vector__XXX

BO_ 1649 CSDO_113: 8 Vector__XXX

BO_ 241 EMCY_113: 8 Vector__XXX
 SG_ ManufacturerSpecific5 : 56|8@1+ (1,0) [0|0] "" Vector__XXX
 SG_ ManufacturerSpecific4 : 48|8@1+ (1,0) [0|0] "" Vector__XXX
 SG_ ManufacturerSpecific3 : 40|8@1+ (1,0) [0|0] "" Vector__XXX
 SG_ ManufacturerSpecific2 : 32|8@1+ (1,0) [0|0] "" Vector__XXX
 SG_ ManufacturerSpecific1 : 24|8@1+ (1,0) [0|0] "" Vector__XXX
 SG_ ErrorRegisterManufSpecific : 23|1@1+ (1,0) [0|0] "" Vector__XXX
 SG_ ErrorRegisterReserved : 22|1@1+ (1,0) [0|0] "" Vector__XXX
 SG_ ErrorRegisterProfileSpecific : 21|1@1+ (1,0) [0|0] "" Vector__XXX
 SG_ ErrorRegisterCommunication : 20|1@1+ (1,0) [0|0] "" Vector__XXX
 SG_ ErrorRegisterTemperature : 19|1@1+ (1,0) [0|0] "" Vector__XXX
 SG_ ErrorRegisterVoltage : 18|1@1+ (1,0) [0|0] "" Vector__XXX
 SG_ ErrorRegisterCurrent : 17|1@1+ (1,0) [0|0] "" Vector__XXX
 SG_ ErrorRegisterGeneric : 16|1@1+ (1,0) [0|0] "" Vector__XXX
 SG_ ErrorCode : 0|16@1+ (1,0) [0|0] "" Vector__XXX

BO_ 1904 HBGuard_112: 1 Vector__XXX
 SG_ Toggle : 7|1@1+ (1,0) [0|0] "" Vector__XXX
 SG_ State : 0|7@1+ (1,0) [0|0] "" Vector__XXX

BO_ 1520 SSDO_112: 8 Vector__XXX

BO_ 1648 CSDO_112: 8 Vector__XXX

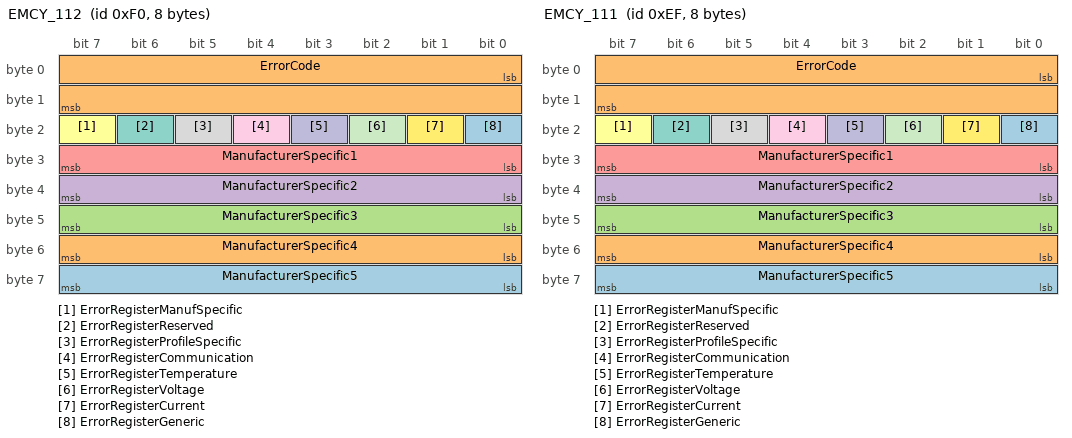
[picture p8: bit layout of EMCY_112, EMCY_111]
BO_ 240 EMCY_112: 8 Vector__XXX
 SG_ ManufacturerSpecific5 : 56|8@1+ (1,0) [0|0] "" Vector__XXX
 SG_ ManufacturerSpecific4 : 48|8@1+ (1,0) [0|0] "" Vector__XXX
 SG_ ManufacturerSpecific3 : 40|8@1+ (1,0) [0|0] "" Vector__XXX
 SG_ ManufacturerSpecific2 : 32|8@1+ (1,0) [0|0] "" Vector__XXX
 SG_ ManufacturerSpecific1 : 24|8@1+ (1,0) [0|0] "" Vector__XXX
 SG_ ErrorRegisterManufSpecific : 23|1@1+ (1,0) [0|0] "" Vector__XXX
 SG_ ErrorRegisterReserved : 22|1@1+ (1,0) [0|0] "" Vector__XXX
 SG_ ErrorRegisterProfileSpecific : 21|1@1+ (1,0) [0|0] "" Vector__XXX
 SG_ ErrorRegisterCommunication : 20|1@1+ (1,0) [0|0] "" Vector__XXX
 SG_ ErrorRegisterTemperature : 19|1@1+ (1,0) [0|0] "" Vector__XXX
 SG_ ErrorRegisterVoltage : 18|1@1+ (1,0) [0|0] "" Vector__XXX
 SG_ ErrorRegisterCurrent : 17|1@1+ (1,0) [0|0] "" Vector__XXX
 SG_ ErrorRegisterGeneric : 16|1@1+ (1,0) [0|0] "" Vector__XXX
 SG_ ErrorCode : 0|16@1+ (1,0) [0|0] "" Vector__XXX

BO_ 1903 HBGuard_111: 1 Vector__XXX
 SG_ Toggle : 7|1@1+ (1,0) [0|0] "" Vector__XXX
 SG_ State : 0|7@1+ (1,0) [0|0] "" Vector__XXX

BO_ 1519 SSDO_111: 8 Vector__XXX

BO_ 1647 CSDO_111: 8 Vector__XXX

BO_ 239 EMCY_111: 8 Vector__XXX
 SG_ ManufacturerSpecific5 : 56|8@1+ (1,0) [0|0] "" Vector__XXX
 SG_ ManufacturerSpecific4 : 48|8@1+ (1,0) [0|0] "" Vector__XXX
 SG_ ManufacturerSpecific3 : 40|8@1+ (1,0) [0|0] "" Vector__XXX
 SG_ ManufacturerSpecific2 : 32|8@1+ (1,0) [0|0] "" Vector__XXX
 SG_ ManufacturerSpecific1 : 24|8@1+ (1,0) [0|0] "" Vector__XXX
 SG_ ErrorRegisterManufSpecific : 23|1@1+ (1,0) [0|0] "" Vector__XXX
 SG_ ErrorRegisterReserved : 22|1@1+ (1,0) [0|0] "" Vector__XXX
 SG_ ErrorRegisterProfileSpecific : 21|1@1+ (1,0) [0|0] "" Vector__XXX
 SG_ ErrorRegisterCommunication : 20|1@1+ (1,0) [0|0] "" Vector__XXX
 SG_ ErrorRegisterTemperature : 19|1@1+ (1,0) [0|0] "" Vector__XXX
 SG_ ErrorRegisterVoltage : 18|1@1+ (1,0) [0|0] "" Vector__XXX
 SG_ ErrorRegisterCurrent : 17|1@1+ (1,0) [0|0] "" Vector__XXX
 SG_ ErrorRegisterGeneric : 16|1@1+ (1,0) [0|0] "" Vector__XXX
 SG_ ErrorCode : 0|16@1+ (1,0) [0|0] "" Vector__XXX

BO_ 1902 HBGuard_110: 1 Vector__XXX
 SG_ Toggle : 7|1@1+ (1,0) [0|0] "" Vector__XXX
 SG_ State : 0|7@1+ (1,0) [0|0] "" Vector__XXX

BO_ 1518 SSDO_110: 8 Vector__XXX

BO_ 1646 CSDO_110: 8 Vector__XXX

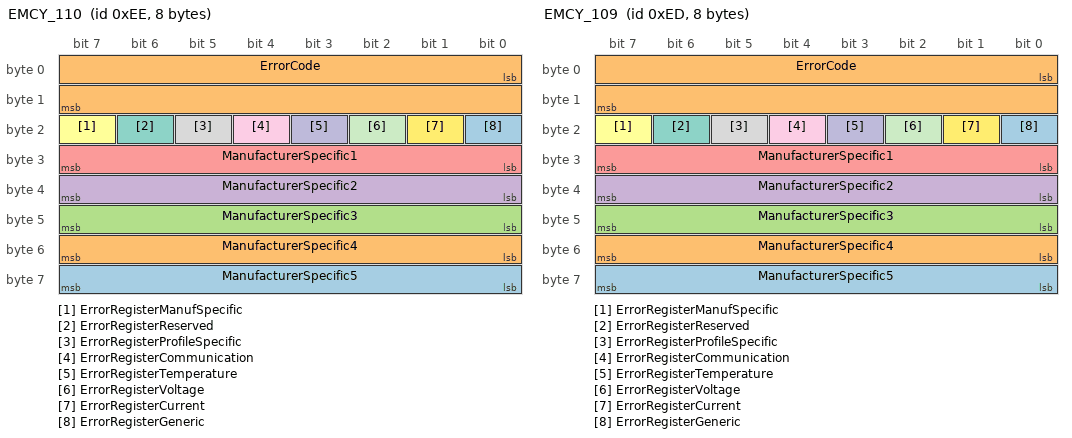
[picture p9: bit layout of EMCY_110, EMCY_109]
BO_ 238 EMCY_110: 8 Vector__XXX
 SG_ ManufacturerSpecific5 : 56|8@1+ (1,0) [0|0] "" Vector__XXX
 SG_ ManufacturerSpecific4 : 48|8@1+ (1,0) [0|0] "" Vector__XXX
 SG_ ManufacturerSpecific3 : 40|8@1+ (1,0) [0|0] "" Vector__XXX
 SG_ ManufacturerSpecific2 : 32|8@1+ (1,0) [0|0] "" Vector__XXX
 SG_ ManufacturerSpecific1 : 24|8@1+ (1,0) [0|0] "" Vector__XXX
 SG_ ErrorRegisterManufSpecific : 23|1@1+ (1,0) [0|0] "" Vector__XXX
 SG_ ErrorRegisterReserved : 22|1@1+ (1,0) [0|0] "" Vector__XXX
 SG_ ErrorRegisterProfileSpecific : 21|1@1+ (1,0) [0|0] "" Vector__XXX
 SG_ ErrorRegisterCommunication : 20|1@1+ (1,0) [0|0] "" Vector__XXX
 SG_ ErrorRegisterTemperature : 19|1@1+ (1,0) [0|0] "" Vector__XXX
 SG_ ErrorRegisterVoltage : 18|1@1+ (1,0) [0|0] "" Vector__XXX
 SG_ ErrorRegisterCurrent : 17|1@1+ (1,0) [0|0] "" Vector__XXX
 SG_ ErrorRegisterGeneric : 16|1@1+ (1,0) [0|0] "" Vector__XXX
 SG_ ErrorCode : 0|16@1+ (1,0) [0|0] "" Vector__XXX

BO_ 1901 HBGuard_109: 1 Vector__XXX
 SG_ Toggle : 7|1@1+ (1,0) [0|0] "" Vector__XXX
 SG_ State : 0|7@1+ (1,0) [0|0] "" Vector__XXX

BO_ 1517 SSDO_109: 8 Vector__XXX

BO_ 1645 CSDO_109: 8 Vector__XXX

BO_ 237 EMCY_109: 8 Vector__XXX
 SG_ ManufacturerSpecific5 : 56|8@1+ (1,0) [0|0] "" Vector__XXX
 SG_ ManufacturerSpecific4 : 48|8@1+ (1,0) [0|0] "" Vector__XXX
 SG_ ManufacturerSpecific3 : 40|8@1+ (1,0) [0|0] "" Vector__XXX
 SG_ ManufacturerSpecific2 : 32|8@1+ (1,0) [0|0] "" Vector__XXX
 SG_ ManufacturerSpecific1 : 24|8@1+ (1,0) [0|0] "" Vector__XXX
 SG_ ErrorRegisterManufSpecific : 23|1@1+ (1,0) [0|0] "" Vector__XXX
 SG_ ErrorRegisterReserved : 22|1@1+ (1,0) [0|0] "" Vector__XXX
 SG_ ErrorRegisterProfileSpecific : 21|1@1+ (1,0) [0|0] "" Vector__XXX
 SG_ ErrorRegisterCommunication : 20|1@1+ (1,0) [0|0] "" Vector__XXX
 SG_ ErrorRegisterTemperature : 19|1@1+ (1,0) [0|0] "" Vector__XXX
 SG_ ErrorRegisterVoltage : 18|1@1+ (1,0) [0|0] "" Vector__XXX
 SG_ ErrorRegisterCurrent : 17|1@1+ (1,0) [0|0] "" Vector__XXX
 SG_ ErrorRegisterGeneric : 16|1@1+ (1,0) [0|0] "" Vector__XXX
 SG_ ErrorCode : 0|16@1+ (1,0) [0|0] "" Vector__XXX

BO_ 1900 HBGuard_108: 1 Vector__XXX
 SG_ Toggle : 7|1@1+ (1,0) [0|0] "" Vector__XXX
 SG_ State : 0|7@1+ (1,0) [0|0] "" Vector__XXX

BO_ 1516 SSDO_108: 8 Vector__XXX

BO_ 1644 CSDO_108: 8 Vector__XXX

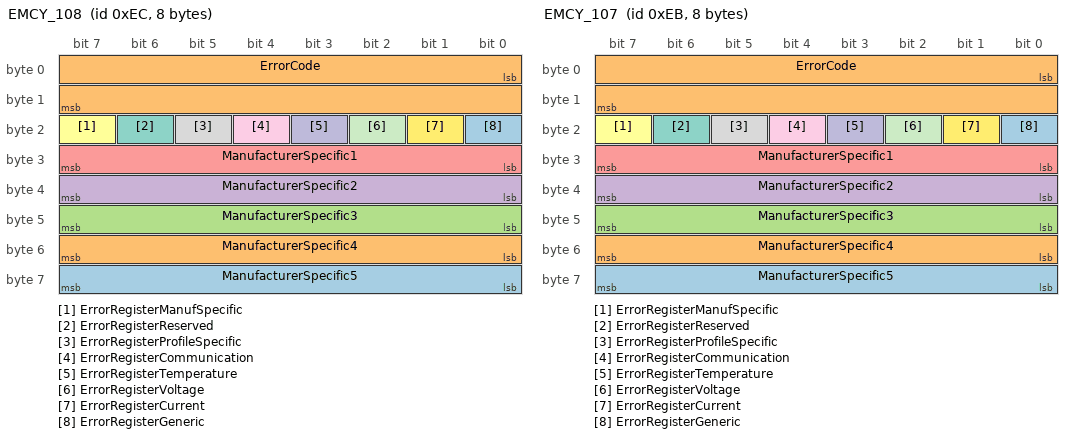
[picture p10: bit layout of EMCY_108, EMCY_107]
BO_ 236 EMCY_108: 8 Vector__XXX
 SG_ ManufacturerSpecific5 : 56|8@1+ (1,0) [0|0] "" Vector__XXX
 SG_ ManufacturerSpecific4 : 48|8@1+ (1,0) [0|0] "" Vector__XXX
 SG_ ManufacturerSpecific3 : 40|8@1+ (1,0) [0|0] "" Vector__XXX
 SG_ ManufacturerSpecific2 : 32|8@1+ (1,0) [0|0] "" Vector__XXX
 SG_ ManufacturerSpecific1 : 24|8@1+ (1,0) [0|0] "" Vector__XXX
 SG_ ErrorRegisterManufSpecific : 23|1@1+ (1,0) [0|0] "" Vector__XXX
 SG_ ErrorRegisterReserved : 22|1@1+ (1,0) [0|0] "" Vector__XXX
 SG_ ErrorRegisterProfileSpecific : 21|1@1+ (1,0) [0|0] "" Vector__XXX
 SG_ ErrorRegisterCommunication : 20|1@1+ (1,0) [0|0] "" Vector__XXX
 SG_ ErrorRegisterTemperature : 19|1@1+ (1,0) [0|0] "" Vector__XXX
 SG_ ErrorRegisterVoltage : 18|1@1+ (1,0) [0|0] "" Vector__XXX
 SG_ ErrorRegisterCurrent : 17|1@1+ (1,0) [0|0] "" Vector__XXX
 SG_ ErrorRegisterGeneric : 16|1@1+ (1,0) [0|0] "" Vector__XXX
 SG_ ErrorCode : 0|16@1+ (1,0) [0|0] "" Vector__XXX

BO_ 1899 HBGuard_107: 1 Vector__XXX
 SG_ Toggle : 7|1@1+ (1,0) [0|0] "" Vector__XXX
 SG_ State : 0|7@1+ (1,0) [0|0] "" Vector__XXX

BO_ 1515 SSDO_107: 8 Vector__XXX

BO_ 1643 CSDO_107: 8 Vector__XXX

BO_ 235 EMCY_107: 8 Vector__XXX
 SG_ ManufacturerSpecific5 : 56|8@1+ (1,0) [0|0] "" Vector__XXX
 SG_ ManufacturerSpecific4 : 48|8@1+ (1,0) [0|0] "" Vector__XXX
 SG_ ManufacturerSpecific3 : 40|8@1+ (1,0) [0|0] "" Vector__XXX
 SG_ ManufacturerSpecific2 : 32|8@1+ (1,0) [0|0] "" Vector__XXX
 SG_ ManufacturerSpecific1 : 24|8@1+ (1,0) [0|0] "" Vector__XXX
 SG_ ErrorRegisterManufSpecific : 23|1@1+ (1,0) [0|0] "" Vector__XXX
 SG_ ErrorRegisterReserved : 22|1@1+ (1,0) [0|0] "" Vector__XXX
 SG_ ErrorRegisterProfileSpecific : 21|1@1+ (1,0) [0|0] "" Vector__XXX
 SG_ ErrorRegisterCommunication : 20|1@1+ (1,0) [0|0] "" Vector__XXX
 SG_ ErrorRegisterTemperature : 19|1@1+ (1,0) [0|0] "" Vector__XXX
 SG_ ErrorRegisterVoltage : 18|1@1+ (1,0) [0|0] "" Vector__XXX
 SG_ ErrorRegisterCurrent : 17|1@1+ (1,0) [0|0] "" Vector__XXX
 SG_ ErrorRegisterGeneric : 16|1@1+ (1,0) [0|0] "" Vector__XXX
 SG_ ErrorCode : 0|16@1+ (1,0) [0|0] "" Vector__XXX

BO_ 1898 HBGuard_106: 1 Vector__XXX
 SG_ Toggle : 7|1@1+ (1,0) [0|0] "" Vector__XXX
 SG_ State : 0|7@1+ (1,0) [0|0] "" Vector__XXX

BO_ 1514 SSDO_106: 8 Vector__XXX

BO_ 1642 CSDO_106: 8 Vector__XXX

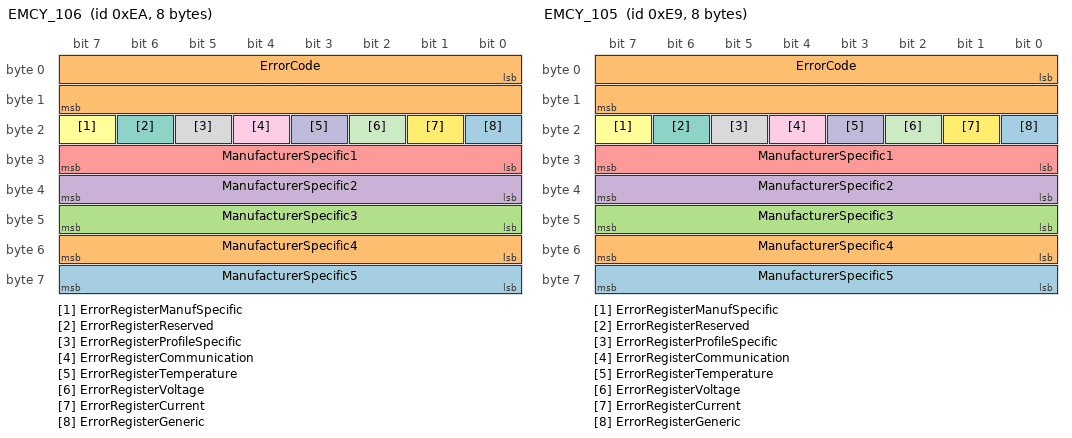
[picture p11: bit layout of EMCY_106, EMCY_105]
BO_ 234 EMCY_106: 8 Vector__XXX
 SG_ ManufacturerSpecific5 : 56|8@1+ (1,0) [0|0] "" Vector__XXX
 SG_ ManufacturerSpecific4 : 48|8@1+ (1,0) [0|0] "" Vector__XXX
 SG_ ManufacturerSpecific3 : 40|8@1+ (1,0) [0|0] "" Vector__XXX
 SG_ ManufacturerSpecific2 : 32|8@1+ (1,0) [0|0] "" Vector__XXX
 SG_ ManufacturerSpecific1 : 24|8@1+ (1,0) [0|0] "" Vector__XXX
 SG_ ErrorRegisterManufSpecific : 23|1@1+ (1,0) [0|0] "" Vector__XXX
 SG_ ErrorRegisterReserved : 22|1@1+ (1,0) [0|0] "" Vector__XXX
 SG_ ErrorRegisterProfileSpecific : 21|1@1+ (1,0) [0|0] "" Vector__XXX
 SG_ ErrorRegisterCommunication : 20|1@1+ (1,0) [0|0] "" Vector__XXX
 SG_ ErrorRegisterTemperature : 19|1@1+ (1,0) [0|0] "" Vector__XXX
 SG_ ErrorRegisterVoltage : 18|1@1+ (1,0) [0|0] "" Vector__XXX
 SG_ ErrorRegisterCurrent : 17|1@1+ (1,0) [0|0] "" Vector__XXX
 SG_ ErrorRegisterGeneric : 16|1@1+ (1,0) [0|0] "" Vector__XXX
 SG_ ErrorCode : 0|16@1+ (1,0) [0|0] "" Vector__XXX

BO_ 1897 HBGuard_105: 1 Vector__XXX
 SG_ Toggle : 7|1@1+ (1,0) [0|0] "" Vector__XXX
 SG_ State : 0|7@1+ (1,0) [0|0] "" Vector__XXX

BO_ 1513 SSDO_105: 8 Vector__XXX

BO_ 1641 CSDO_105: 8 Vector__XXX

BO_ 233 EMCY_105: 8 Vector__XXX
 SG_ ManufacturerSpecific5 : 56|8@1+ (1,0) [0|0] "" Vector__XXX
 SG_ ManufacturerSpecific4 : 48|8@1+ (1,0) [0|0] "" Vector__XXX
 SG_ ManufacturerSpecific3 : 40|8@1+ (1,0) [0|0] "" Vector__XXX
 SG_ ManufacturerSpecific2 : 32|8@1+ (1,0) [0|0] "" Vector__XXX
 SG_ ManufacturerSpecific1 : 24|8@1+ (1,0) [0|0] "" Vector__XXX
 SG_ ErrorRegisterManufSpecific : 23|1@1+ (1,0) [0|0] "" Vector__XXX
 SG_ ErrorRegisterReserved : 22|1@1+ (1,0) [0|0] "" Vector__XXX
 SG_ ErrorRegisterProfileSpecific : 21|1@1+ (1,0) [0|0] "" Vector__XXX
 SG_ ErrorRegisterCommunication : 20|1@1+ (1,0) [0|0] "" Vector__XXX
 SG_ ErrorRegisterTemperature : 19|1@1+ (1,0) [0|0] "" Vector__XXX
 SG_ ErrorRegisterVoltage : 18|1@1+ (1,0) [0|0] "" Vector__XXX
 SG_ ErrorRegisterCurrent : 17|1@1+ (1,0) [0|0] "" Vector__XXX
 SG_ ErrorRegisterGeneric : 16|1@1+ (1,0) [0|0] "" Vector__XXX
 SG_ ErrorCode : 0|16@1+ (1,0) [0|0] "" Vector__XXX

BO_ 1896 HBGuard_104: 1 Vector__XXX
 SG_ Toggle : 7|1@1+ (1,0) [0|0] "" Vector__XXX
 SG_ State : 0|7@1+ (1,0) [0|0] "" Vector__XXX

BO_ 1512 SSDO_104: 8 Vector__XXX

BO_ 1640 CSDO_104: 8 Vector__XXX

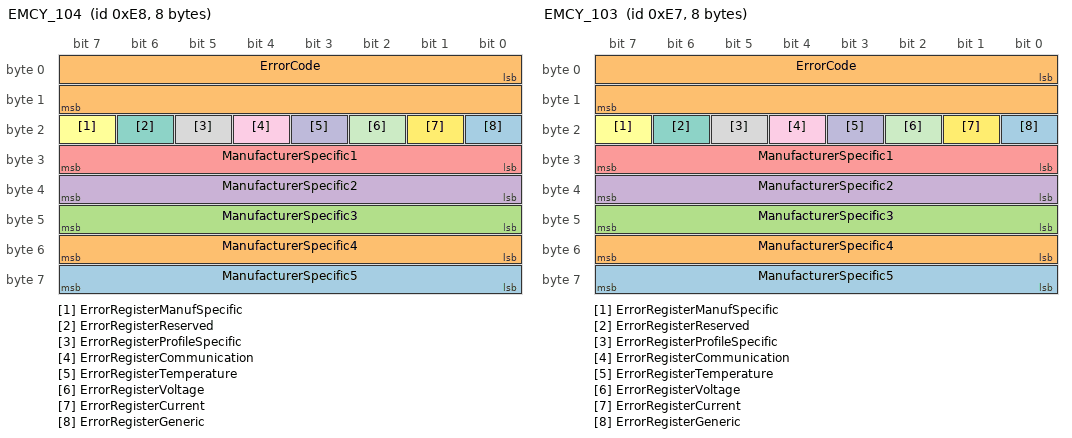
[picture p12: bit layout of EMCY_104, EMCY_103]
BO_ 232 EMCY_104: 8 Vector__XXX
 SG_ ManufacturerSpecific5 : 56|8@1+ (1,0) [0|0] "" Vector__XXX
 SG_ ManufacturerSpecific4 : 48|8@1+ (1,0) [0|0] "" Vector__XXX
 SG_ ManufacturerSpecific3 : 40|8@1+ (1,0) [0|0] "" Vector__XXX
 SG_ ManufacturerSpecific2 : 32|8@1+ (1,0) [0|0] "" Vector__XXX
 SG_ ManufacturerSpecific1 : 24|8@1+ (1,0) [0|0] "" Vector__XXX
 SG_ ErrorRegisterManufSpecific : 23|1@1+ (1,0) [0|0] "" Vector__XXX
 SG_ ErrorRegisterReserved : 22|1@1+ (1,0) [0|0] "" Vector__XXX
 SG_ ErrorRegisterProfileSpecific : 21|1@1+ (1,0) [0|0] "" Vector__XXX
 SG_ ErrorRegisterCommunication : 20|1@1+ (1,0) [0|0] "" Vector__XXX
 SG_ ErrorRegisterTemperature : 19|1@1+ (1,0) [0|0] "" Vector__XXX
 SG_ ErrorRegisterVoltage : 18|1@1+ (1,0) [0|0] "" Vector__XXX
 SG_ ErrorRegisterCurrent : 17|1@1+ (1,0) [0|0] "" Vector__XXX
 SG_ ErrorRegisterGeneric : 16|1@1+ (1,0) [0|0] "" Vector__XXX
 SG_ ErrorCode : 0|16@1+ (1,0) [0|0] "" Vector__XXX

BO_ 1895 HBGuard_103: 1 Vector__XXX
 SG_ Toggle : 7|1@1+ (1,0) [0|0] "" Vector__XXX
 SG_ State : 0|7@1+ (1,0) [0|0] "" Vector__XXX

BO_ 1511 SSDO_103: 8 Vector__XXX

BO_ 1639 CSDO_103: 8 Vector__XXX

BO_ 231 EMCY_103: 8 Vector__XXX
 SG_ ManufacturerSpecific5 : 56|8@1+ (1,0) [0|0] "" Vector__XXX
 SG_ ManufacturerSpecific4 : 48|8@1+ (1,0) [0|0] "" Vector__XXX
 SG_ ManufacturerSpecific3 : 40|8@1+ (1,0) [0|0] "" Vector__XXX
 SG_ ManufacturerSpecific2 : 32|8@1+ (1,0) [0|0] "" Vector__XXX
 SG_ ManufacturerSpecific1 : 24|8@1+ (1,0) [0|0] "" Vector__XXX
 SG_ ErrorRegisterManufSpecific : 23|1@1+ (1,0) [0|0] "" Vector__XXX
 SG_ ErrorRegisterReserved : 22|1@1+ (1,0) [0|0] "" Vector__XXX
 SG_ ErrorRegisterProfileSpecific : 21|1@1+ (1,0) [0|0] "" Vector__XXX
 SG_ ErrorRegisterCommunication : 20|1@1+ (1,0) [0|0] "" Vector__XXX
 SG_ ErrorRegisterTemperature : 19|1@1+ (1,0) [0|0] "" Vector__XXX
 SG_ ErrorRegisterVoltage : 18|1@1+ (1,0) [0|0] "" Vector__XXX
 SG_ ErrorRegisterCurrent : 17|1@1+ (1,0) [0|0] "" Vector__XXX
 SG_ ErrorRegisterGeneric : 16|1@1+ (1,0) [0|0] "" Vector__XXX
 SG_ ErrorCode : 0|16@1+ (1,0) [0|0] "" Vector__XXX

BO_ 1894 HBGuard_102: 1 Vector__XXX
 SG_ Toggle : 7|1@1+ (1,0) [0|0] "" Vector__XXX
 SG_ State : 0|7@1+ (1,0) [0|0] "" Vector__XXX

BO_ 1510 SSDO_102: 8 Vector__XXX

BO_ 1638 CSDO_102: 8 Vector__XXX

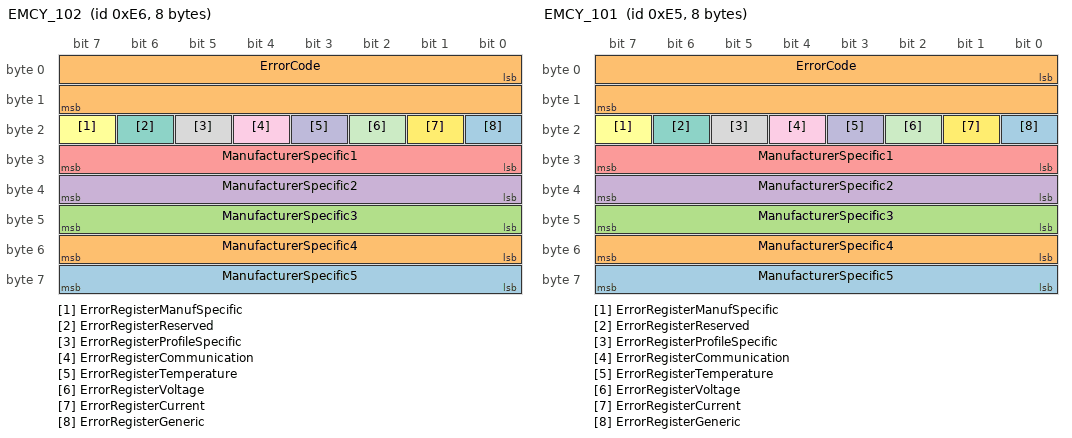
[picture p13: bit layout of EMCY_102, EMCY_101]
BO_ 230 EMCY_102: 8 Vector__XXX
 SG_ ManufacturerSpecific5 : 56|8@1+ (1,0) [0|0] "" Vector__XXX
 SG_ ManufacturerSpecific4 : 48|8@1+ (1,0) [0|0] "" Vector__XXX
 SG_ ManufacturerSpecific3 : 40|8@1+ (1,0) [0|0] "" Vector__XXX
 SG_ ManufacturerSpecific2 : 32|8@1+ (1,0) [0|0] "" Vector__XXX
 SG_ ManufacturerSpecific1 : 24|8@1+ (1,0) [0|0] "" Vector__XXX
 SG_ ErrorRegisterManufSpecific : 23|1@1+ (1,0) [0|0] "" Vector__XXX
 SG_ ErrorRegisterReserved : 22|1@1+ (1,0) [0|0] "" Vector__XXX
 SG_ ErrorRegisterProfileSpecific : 21|1@1+ (1,0) [0|0] "" Vector__XXX
 SG_ ErrorRegisterCommunication : 20|1@1+ (1,0) [0|0] "" Vector__XXX
 SG_ ErrorRegisterTemperature : 19|1@1+ (1,0) [0|0] "" Vector__XXX
 SG_ ErrorRegisterVoltage : 18|1@1+ (1,0) [0|0] "" Vector__XXX
 SG_ ErrorRegisterCurrent : 17|1@1+ (1,0) [0|0] "" Vector__XXX
 SG_ ErrorRegisterGeneric : 16|1@1+ (1,0) [0|0] "" Vector__XXX
 SG_ ErrorCode : 0|16@1+ (1,0) [0|0] "" Vector__XXX

BO_ 1893 HBGuard_101: 1 Vector__XXX
 SG_ Toggle : 7|1@1+ (1,0) [0|0] "" Vector__XXX
 SG_ State : 0|7@1+ (1,0) [0|0] "" Vector__XXX

BO_ 1509 SSDO_101: 8 Vector__XXX

BO_ 1637 CSDO_101: 8 Vector__XXX

BO_ 229 EMCY_101: 8 Vector__XXX
 SG_ ManufacturerSpecific5 : 56|8@1+ (1,0) [0|0] "" Vector__XXX
 SG_ ManufacturerSpecific4 : 48|8@1+ (1,0) [0|0] "" Vector__XXX
 SG_ ManufacturerSpecific3 : 40|8@1+ (1,0) [0|0] "" Vector__XXX
 SG_ ManufacturerSpecific2 : 32|8@1+ (1,0) [0|0] "" Vector__XXX
 SG_ ManufacturerSpecific1 : 24|8@1+ (1,0) [0|0] "" Vector__XXX
 SG_ ErrorRegisterManufSpecific : 23|1@1+ (1,0) [0|0] "" Vector__XXX
 SG_ ErrorRegisterReserved : 22|1@1+ (1,0) [0|0] "" Vector__XXX
 SG_ ErrorRegisterProfileSpecific : 21|1@1+ (1,0) [0|0] "" Vector__XXX
 SG_ ErrorRegisterCommunication : 20|1@1+ (1,0) [0|0] "" Vector__XXX
 SG_ ErrorRegisterTemperature : 19|1@1+ (1,0) [0|0] "" Vector__XXX
 SG_ ErrorRegisterVoltage : 18|1@1+ (1,0) [0|0] "" Vector__XXX
 SG_ ErrorRegisterCurrent : 17|1@1+ (1,0) [0|0] "" Vector__XXX
 SG_ ErrorRegisterGeneric : 16|1@1+ (1,0) [0|0] "" Vector__XXX
 SG_ ErrorCode : 0|16@1+ (1,0) [0|0] "" Vector__XXX

BO_ 1892 HBGuard_100: 1 Vector__XXX
 SG_ Toggle : 7|1@1+ (1,0) [0|0] "" Vector__XXX
 SG_ State : 0|7@1+ (1,0) [0|0] "" Vector__XXX

BO_ 1508 SSDO_100: 8 Vector__XXX

BO_ 1636 CSDO_100: 8 Vector__XXX

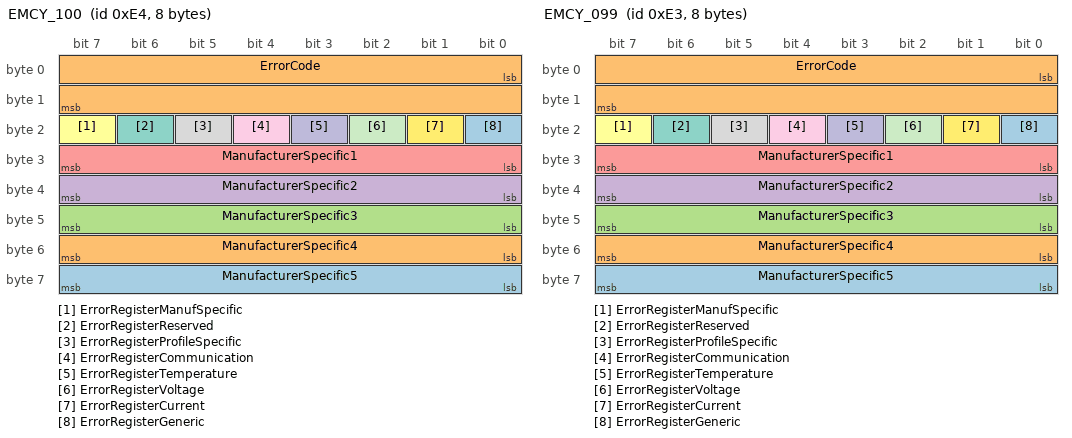
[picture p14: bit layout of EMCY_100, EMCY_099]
BO_ 228 EMCY_100: 8 Vector__XXX
 SG_ ManufacturerSpecific5 : 56|8@1+ (1,0) [0|0] "" Vector__XXX
 SG_ ManufacturerSpecific4 : 48|8@1+ (1,0) [0|0] "" Vector__XXX
 SG_ ManufacturerSpecific3 : 40|8@1+ (1,0) [0|0] "" Vector__XXX
 SG_ ManufacturerSpecific2 : 32|8@1+ (1,0) [0|0] "" Vector__XXX
 SG_ ManufacturerSpecific1 : 24|8@1+ (1,0) [0|0] "" Vector__XXX
 SG_ ErrorRegisterManufSpecific : 23|1@1+ (1,0) [0|0] "" Vector__XXX
 SG_ ErrorRegisterReserved : 22|1@1+ (1,0) [0|0] "" Vector__XXX
 SG_ ErrorRegisterProfileSpecific : 21|1@1+ (1,0) [0|0] "" Vector__XXX
 SG_ ErrorRegisterCommunication : 20|1@1+ (1,0) [0|0] "" Vector__XXX
 SG_ ErrorRegisterTemperature : 19|1@1+ (1,0) [0|0] "" Vector__XXX
 SG_ ErrorRegisterVoltage : 18|1@1+ (1,0) [0|0] "" Vector__XXX
 SG_ ErrorRegisterCurrent : 17|1@1+ (1,0) [0|0] "" Vector__XXX
 SG_ ErrorRegisterGeneric : 16|1@1+ (1,0) [0|0] "" Vector__XXX
 SG_ ErrorCode : 0|16@1+ (1,0) [0|0] "" Vector__XXX

BO_ 1891 HBGuard_099: 1 Vector__XXX
 SG_ Toggle : 7|1@1+ (1,0) [0|0] "" Vector__XXX
 SG_ State : 0|7@1+ (1,0) [0|0] "" Vector__XXX

BO_ 1507 SSDO_099: 8 Vector__XXX

BO_ 1635 CSDO_099: 8 Vector__XXX

BO_ 227 EMCY_099: 8 Vector__XXX
 SG_ ManufacturerSpecific5 : 56|8@1+ (1,0) [0|0] "" Vector__XXX
 SG_ ManufacturerSpecific4 : 48|8@1+ (1,0) [0|0] "" Vector__XXX
 SG_ ManufacturerSpecific3 : 40|8@1+ (1,0) [0|0] "" Vector__XXX
 SG_ ManufacturerSpecific2 : 32|8@1+ (1,0) [0|0] "" Vector__XXX
 SG_ ManufacturerSpecific1 : 24|8@1+ (1,0) [0|0] "" Vector__XXX
 SG_ ErrorRegisterManufSpecific : 23|1@1+ (1,0) [0|0] "" Vector__XXX
 SG_ ErrorRegisterReserved : 22|1@1+ (1,0) [0|0] "" Vector__XXX
 SG_ ErrorRegisterProfileSpecific : 21|1@1+ (1,0) [0|0] "" Vector__XXX
 SG_ ErrorRegisterCommunication : 20|1@1+ (1,0) [0|0] "" Vector__XXX
 SG_ ErrorRegisterTemperature : 19|1@1+ (1,0) [0|0] "" Vector__XXX
 SG_ ErrorRegisterVoltage : 18|1@1+ (1,0) [0|0] "" Vector__XXX
 SG_ ErrorRegisterCurrent : 17|1@1+ (1,0) [0|0] "" Vector__XXX
 SG_ ErrorRegisterGeneric : 16|1@1+ (1,0) [0|0] "" Vector__XXX
 SG_ ErrorCode : 0|16@1+ (1,0) [0|0] "" Vector__XXX

BO_ 1890 HBGuard_098: 1 Vector__XXX
 SG_ Toggle : 7|1@1+ (1,0) [0|0] "" Vector__XXX
 SG_ State : 0|7@1+ (1,0) [0|0] "" Vector__XXX

BO_ 1506 SSDO_098: 8 Vector__XXX

BO_ 1634 CSDO_098: 8 Vector__XXX

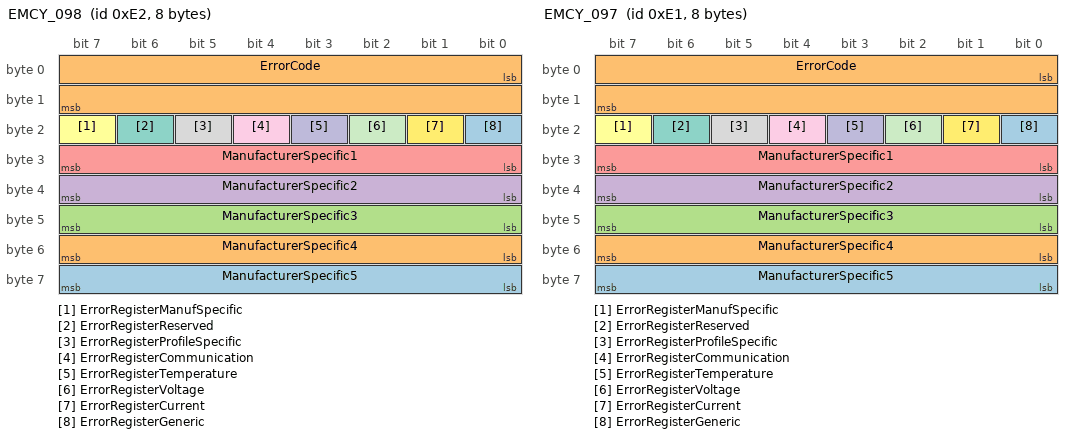
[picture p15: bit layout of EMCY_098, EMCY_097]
BO_ 226 EMCY_098: 8 Vector__XXX
 SG_ ManufacturerSpecific5 : 56|8@1+ (1,0) [0|0] "" Vector__XXX
 SG_ ManufacturerSpecific4 : 48|8@1+ (1,0) [0|0] "" Vector__XXX
 SG_ ManufacturerSpecific3 : 40|8@1+ (1,0) [0|0] "" Vector__XXX
 SG_ ManufacturerSpecific2 : 32|8@1+ (1,0) [0|0] "" Vector__XXX
 SG_ ManufacturerSpecific1 : 24|8@1+ (1,0) [0|0] "" Vector__XXX
 SG_ ErrorRegisterManufSpecific : 23|1@1+ (1,0) [0|0] "" Vector__XXX
 SG_ ErrorRegisterReserved : 22|1@1+ (1,0) [0|0] "" Vector__XXX
 SG_ ErrorRegisterProfileSpecific : 21|1@1+ (1,0) [0|0] "" Vector__XXX
 SG_ ErrorRegisterCommunication : 20|1@1+ (1,0) [0|0] "" Vector__XXX
 SG_ ErrorRegisterTemperature : 19|1@1+ (1,0) [0|0] "" Vector__XXX
 SG_ ErrorRegisterVoltage : 18|1@1+ (1,0) [0|0] "" Vector__XXX
 SG_ ErrorRegisterCurrent : 17|1@1+ (1,0) [0|0] "" Vector__XXX
 SG_ ErrorRegisterGeneric : 16|1@1+ (1,0) [0|0] "" Vector__XXX
 SG_ ErrorCode : 0|16@1+ (1,0) [0|0] "" Vector__XXX

BO_ 1889 HBGuard_097: 1 Vector__XXX
 SG_ Toggle : 7|1@1+ (1,0) [0|0] "" Vector__XXX
 SG_ State : 0|7@1+ (1,0) [0|0] "" Vector__XXX

BO_ 1505 SSDO_097: 8 Vector__XXX

BO_ 1633 CSDO_097: 8 Vector__XXX

BO_ 225 EMCY_097: 8 Vector__XXX
 SG_ ManufacturerSpecific5 : 56|8@1+ (1,0) [0|0] "" Vector__XXX
 SG_ ManufacturerSpecific4 : 48|8@1+ (1,0) [0|0] "" Vector__XXX
 SG_ ManufacturerSpecific3 : 40|8@1+ (1,0) [0|0] "" Vector__XXX
 SG_ ManufacturerSpecific2 : 32|8@1+ (1,0) [0|0] "" Vector__XXX
 SG_ ManufacturerSpecific1 : 24|8@1+ (1,0) [0|0] "" Vector__XXX
 SG_ ErrorRegisterManufSpecific : 23|1@1+ (1,0) [0|0] "" Vector__XXX
 SG_ ErrorRegisterReserved : 22|1@1+ (1,0) [0|0] "" Vector__XXX
 SG_ ErrorRegisterProfileSpecific : 21|1@1+ (1,0) [0|0] "" Vector__XXX
 SG_ ErrorRegisterCommunication : 20|1@1+ (1,0) [0|0] "" Vector__XXX
 SG_ ErrorRegisterTemperature : 19|1@1+ (1,0) [0|0] "" Vector__XXX
 SG_ ErrorRegisterVoltage : 18|1@1+ (1,0) [0|0] "" Vector__XXX
 SG_ ErrorRegisterCurrent : 17|1@1+ (1,0) [0|0] "" Vector__XXX
 SG_ ErrorRegisterGeneric : 16|1@1+ (1,0) [0|0] "" Vector__XXX
 SG_ ErrorCode : 0|16@1+ (1,0) [0|0] "" Vector__XXX

BO_ 1888 HBGuard_096: 1 Vector__XXX
 SG_ Toggle : 7|1@1+ (1,0) [0|0] "" Vector__XXX
 SG_ State : 0|7@1+ (1,0) [0|0] "" Vector__XXX

BO_ 1504 SSDO_096: 8 Vector__XXX

BO_ 1632 CSDO_096: 8 Vector__XXX

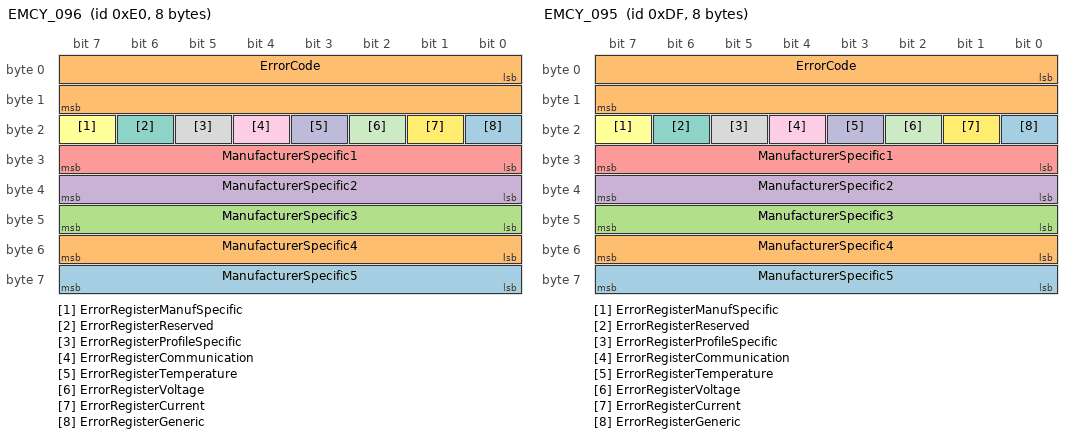
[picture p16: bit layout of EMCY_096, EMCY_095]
BO_ 224 EMCY_096: 8 Vector__XXX
 SG_ ManufacturerSpecific5 : 56|8@1+ (1,0) [0|0] "" Vector__XXX
 SG_ ManufacturerSpecific4 : 48|8@1+ (1,0) [0|0] "" Vector__XXX
 SG_ ManufacturerSpecific3 : 40|8@1+ (1,0) [0|0] "" Vector__XXX
 SG_ ManufacturerSpecific2 : 32|8@1+ (1,0) [0|0] "" Vector__XXX
 SG_ ManufacturerSpecific1 : 24|8@1+ (1,0) [0|0] "" Vector__XXX
 SG_ ErrorRegisterManufSpecific : 23|1@1+ (1,0) [0|0] "" Vector__XXX
 SG_ ErrorRegisterReserved : 22|1@1+ (1,0) [0|0] "" Vector__XXX
 SG_ ErrorRegisterProfileSpecific : 21|1@1+ (1,0) [0|0] "" Vector__XXX
 SG_ ErrorRegisterCommunication : 20|1@1+ (1,0) [0|0] "" Vector__XXX
 SG_ ErrorRegisterTemperature : 19|1@1+ (1,0) [0|0] "" Vector__XXX
 SG_ ErrorRegisterVoltage : 18|1@1+ (1,0) [0|0] "" Vector__XXX
 SG_ ErrorRegisterCurrent : 17|1@1+ (1,0) [0|0] "" Vector__XXX
 SG_ ErrorRegisterGeneric : 16|1@1+ (1,0) [0|0] "" Vector__XXX
 SG_ ErrorCode : 0|16@1+ (1,0) [0|0] "" Vector__XXX

BO_ 1887 HBGuard_095: 1 Vector__XXX
 SG_ Toggle : 7|1@1+ (1,0) [0|0] "" Vector__XXX
 SG_ State : 0|7@1+ (1,0) [0|0] "" Vector__XXX

BO_ 1503 SSDO_095: 8 Vector__XXX

BO_ 1631 CSDO_095: 8 Vector__XXX

BO_ 223 EMCY_095: 8 Vector__XXX
 SG_ ManufacturerSpecific5 : 56|8@1+ (1,0) [0|0] "" Vector__XXX
 SG_ ManufacturerSpecific4 : 48|8@1+ (1,0) [0|0] "" Vector__XXX
 SG_ ManufacturerSpecific3 : 40|8@1+ (1,0) [0|0] "" Vector__XXX
 SG_ ManufacturerSpecific2 : 32|8@1+ (1,0) [0|0] "" Vector__XXX
 SG_ ManufacturerSpecific1 : 24|8@1+ (1,0) [0|0] "" Vector__XXX
 SG_ ErrorRegisterManufSpecific : 23|1@1+ (1,0) [0|0] "" Vector__XXX
 SG_ ErrorRegisterReserved : 22|1@1+ (1,0) [0|0] "" Vector__XXX
 SG_ ErrorRegisterProfileSpecific : 21|1@1+ (1,0) [0|0] "" Vector__XXX
 SG_ ErrorRegisterCommunication : 20|1@1+ (1,0) [0|0] "" Vector__XXX
 SG_ ErrorRegisterTemperature : 19|1@1+ (1,0) [0|0] "" Vector__XXX
 SG_ ErrorRegisterVoltage : 18|1@1+ (1,0) [0|0] "" Vector__XXX
 SG_ ErrorRegisterCurrent : 17|1@1+ (1,0) [0|0] "" Vector__XXX
 SG_ ErrorRegisterGeneric : 16|1@1+ (1,0) [0|0] "" Vector__XXX
 SG_ ErrorCode : 0|16@1+ (1,0) [0|0] "" Vector__XXX

BO_ 1886 HBGuard_094: 1 Vector__XXX
 SG_ Toggle : 7|1@1+ (1,0) [0|0] "" Vector__XXX
 SG_ State : 0|7@1+ (1,0) [0|0] "" Vector__XXX

BO_ 1502 SSDO_094: 8 Vector__XXX

BO_ 1630 CSDO_094: 8 Vector__XXX

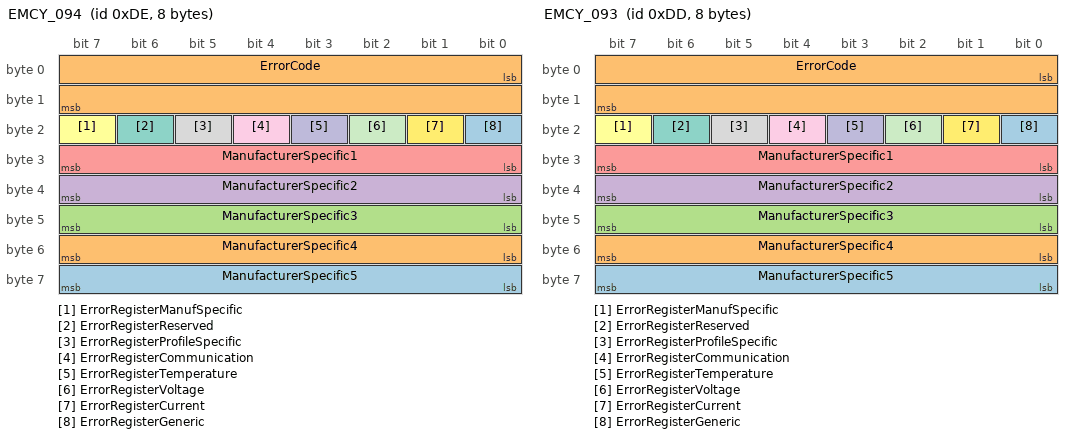
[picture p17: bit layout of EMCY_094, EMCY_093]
BO_ 222 EMCY_094: 8 Vector__XXX
 SG_ ManufacturerSpecific5 : 56|8@1+ (1,0) [0|0] "" Vector__XXX
 SG_ ManufacturerSpecific4 : 48|8@1+ (1,0) [0|0] "" Vector__XXX
 SG_ ManufacturerSpecific3 : 40|8@1+ (1,0) [0|0] "" Vector__XXX
 SG_ ManufacturerSpecific2 : 32|8@1+ (1,0) [0|0] "" Vector__XXX
 SG_ ManufacturerSpecific1 : 24|8@1+ (1,0) [0|0] "" Vector__XXX
 SG_ ErrorRegisterManufSpecific : 23|1@1+ (1,0) [0|0] "" Vector__XXX
 SG_ ErrorRegisterReserved : 22|1@1+ (1,0) [0|0] "" Vector__XXX
 SG_ ErrorRegisterProfileSpecific : 21|1@1+ (1,0) [0|0] "" Vector__XXX
 SG_ ErrorRegisterCommunication : 20|1@1+ (1,0) [0|0] "" Vector__XXX
 SG_ ErrorRegisterTemperature : 19|1@1+ (1,0) [0|0] "" Vector__XXX
 SG_ ErrorRegisterVoltage : 18|1@1+ (1,0) [0|0] "" Vector__XXX
 SG_ ErrorRegisterCurrent : 17|1@1+ (1,0) [0|0] "" Vector__XXX
 SG_ ErrorRegisterGeneric : 16|1@1+ (1,0) [0|0] "" Vector__XXX
 SG_ ErrorCode : 0|16@1+ (1,0) [0|0] "" Vector__XXX

BO_ 1885 HBGuard_093: 1 Vector__XXX
 SG_ Toggle : 7|1@1+ (1,0) [0|0] "" Vector__XXX
 SG_ State : 0|7@1+ (1,0) [0|0] "" Vector__XXX

BO_ 1501 SSDO_093: 8 Vector__XXX

BO_ 1629 CSDO_093: 8 Vector__XXX

BO_ 221 EMCY_093: 8 Vector__XXX
 SG_ ManufacturerSpecific5 : 56|8@1+ (1,0) [0|0] "" Vector__XXX
 SG_ ManufacturerSpecific4 : 48|8@1+ (1,0) [0|0] "" Vector__XXX
 SG_ ManufacturerSpecific3 : 40|8@1+ (1,0) [0|0] "" Vector__XXX
 SG_ ManufacturerSpecific2 : 32|8@1+ (1,0) [0|0] "" Vector__XXX
 SG_ ManufacturerSpecific1 : 24|8@1+ (1,0) [0|0] "" Vector__XXX
 SG_ ErrorRegisterManufSpecific : 23|1@1+ (1,0) [0|0] "" Vector__XXX
 SG_ ErrorRegisterReserved : 22|1@1+ (1,0) [0|0] "" Vector__XXX
 SG_ ErrorRegisterProfileSpecific : 21|1@1+ (1,0) [0|0] "" Vector__XXX
 SG_ ErrorRegisterCommunication : 20|1@1+ (1,0) [0|0] "" Vector__XXX
 SG_ ErrorRegisterTemperature : 19|1@1+ (1,0) [0|0] "" Vector__XXX
 SG_ ErrorRegisterVoltage : 18|1@1+ (1,0) [0|0] "" Vector__XXX
 SG_ ErrorRegisterCurrent : 17|1@1+ (1,0) [0|0] "" Vector__XXX
 SG_ ErrorRegisterGeneric : 16|1@1+ (1,0) [0|0] "" Vector__XXX
 SG_ ErrorCode : 0|16@1+ (1,0) [0|0] "" Vector__XXX

BO_ 1884 HBGuard_092: 1 Vector__XXX
 SG_ Toggle : 7|1@1+ (1,0) [0|0] "" Vector__XXX
 SG_ State : 0|7@1+ (1,0) [0|0] "" Vector__XXX

BO_ 1500 SSDO_092: 8 Vector__XXX

BO_ 1628 CSDO_092: 8 Vector__XXX

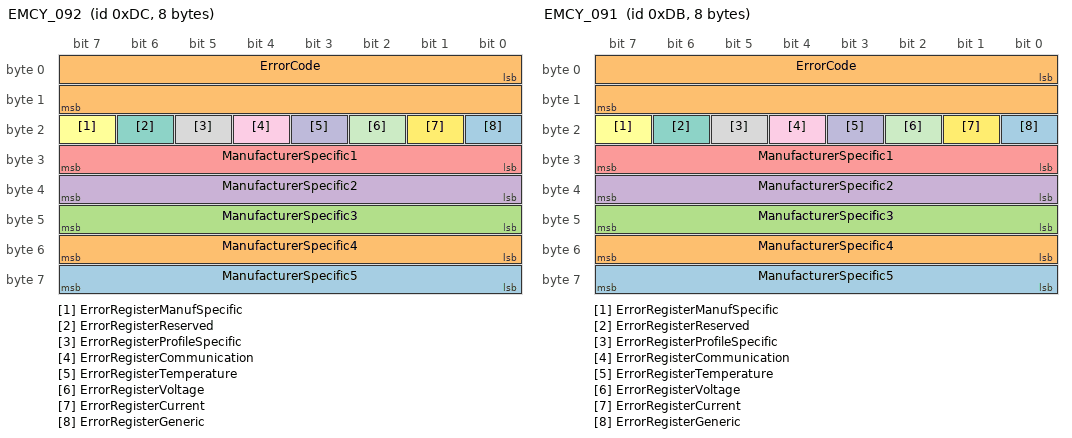
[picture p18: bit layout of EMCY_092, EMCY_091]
BO_ 220 EMCY_092: 8 Vector__XXX
 SG_ ManufacturerSpecific5 : 56|8@1+ (1,0) [0|0] "" Vector__XXX
 SG_ ManufacturerSpecific4 : 48|8@1+ (1,0) [0|0] "" Vector__XXX
 SG_ ManufacturerSpecific3 : 40|8@1+ (1,0) [0|0] "" Vector__XXX
 SG_ ManufacturerSpecific2 : 32|8@1+ (1,0) [0|0] "" Vector__XXX
 SG_ ManufacturerSpecific1 : 24|8@1+ (1,0) [0|0] "" Vector__XXX
 SG_ ErrorRegisterManufSpecific : 23|1@1+ (1,0) [0|0] "" Vector__XXX
 SG_ ErrorRegisterReserved : 22|1@1+ (1,0) [0|0] "" Vector__XXX
 SG_ ErrorRegisterProfileSpecific : 21|1@1+ (1,0) [0|0] "" Vector__XXX
 SG_ ErrorRegisterCommunication : 20|1@1+ (1,0) [0|0] "" Vector__XXX
 SG_ ErrorRegisterTemperature : 19|1@1+ (1,0) [0|0] "" Vector__XXX
 SG_ ErrorRegisterVoltage : 18|1@1+ (1,0) [0|0] "" Vector__XXX
 SG_ ErrorRegisterCurrent : 17|1@1+ (1,0) [0|0] "" Vector__XXX
 SG_ ErrorRegisterGeneric : 16|1@1+ (1,0) [0|0] "" Vector__XXX
 SG_ ErrorCode : 0|16@1+ (1,0) [0|0] "" Vector__XXX

BO_ 1883 HBGuard_091: 1 Vector__XXX
 SG_ Toggle : 7|1@1+ (1,0) [0|0] "" Vector__XXX
 SG_ State : 0|7@1+ (1,0) [0|0] "" Vector__XXX

BO_ 1499 SSDO_091: 8 Vector__XXX

BO_ 1627 CSDO_091: 8 Vector__XXX

BO_ 219 EMCY_091: 8 Vector__XXX
 SG_ ManufacturerSpecific5 : 56|8@1+ (1,0) [0|0] "" Vector__XXX
 SG_ ManufacturerSpecific4 : 48|8@1+ (1,0) [0|0] "" Vector__XXX
 SG_ ManufacturerSpecific3 : 40|8@1+ (1,0) [0|0] "" Vector__XXX
 SG_ ManufacturerSpecific2 : 32|8@1+ (1,0) [0|0] "" Vector__XXX
 SG_ ManufacturerSpecific1 : 24|8@1+ (1,0) [0|0] "" Vector__XXX
 SG_ ErrorRegisterManufSpecific : 23|1@1+ (1,0) [0|0] "" Vector__XXX
 SG_ ErrorRegisterReserved : 22|1@1+ (1,0) [0|0] "" Vector__XXX
 SG_ ErrorRegisterProfileSpecific : 21|1@1+ (1,0) [0|0] "" Vector__XXX
 SG_ ErrorRegisterCommunication : 20|1@1+ (1,0) [0|0] "" Vector__XXX
 SG_ ErrorRegisterTemperature : 19|1@1+ (1,0) [0|0] "" Vector__XXX
 SG_ ErrorRegisterVoltage : 18|1@1+ (1,0) [0|0] "" Vector__XXX
 SG_ ErrorRegisterCurrent : 17|1@1+ (1,0) [0|0] "" Vector__XXX
 SG_ ErrorRegisterGeneric : 16|1@1+ (1,0) [0|0] "" Vector__XXX
 SG_ ErrorCode : 0|16@1+ (1,0) [0|0] "" Vector__XXX

BO_ 1882 HBGuard_090: 1 Vector__XXX
 SG_ Toggle : 7|1@1+ (1,0) [0|0] "" Vector__XXX
 SG_ State : 0|7@1+ (1,0) [0|0] "" Vector__XXX

BO_ 1498 SSDO_090: 8 Vector__XXX

BO_ 1626 CSDO_090: 8 Vector__XXX

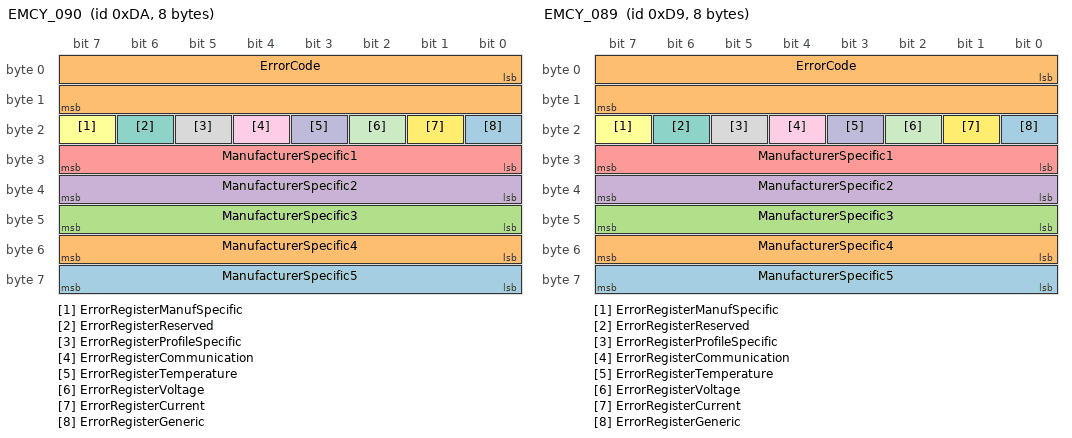
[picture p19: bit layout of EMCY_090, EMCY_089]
BO_ 218 EMCY_090: 8 Vector__XXX
 SG_ ManufacturerSpecific5 : 56|8@1+ (1,0) [0|0] "" Vector__XXX
 SG_ ManufacturerSpecific4 : 48|8@1+ (1,0) [0|0] "" Vector__XXX
 SG_ ManufacturerSpecific3 : 40|8@1+ (1,0) [0|0] "" Vector__XXX
 SG_ ManufacturerSpecific2 : 32|8@1+ (1,0) [0|0] "" Vector__XXX
 SG_ ManufacturerSpecific1 : 24|8@1+ (1,0) [0|0] "" Vector__XXX
 SG_ ErrorRegisterManufSpecific : 23|1@1+ (1,0) [0|0] "" Vector__XXX
 SG_ ErrorRegisterReserved : 22|1@1+ (1,0) [0|0] "" Vector__XXX
 SG_ ErrorRegisterProfileSpecific : 21|1@1+ (1,0) [0|0] "" Vector__XXX
 SG_ ErrorRegisterCommunication : 20|1@1+ (1,0) [0|0] "" Vector__XXX
 SG_ ErrorRegisterTemperature : 19|1@1+ (1,0) [0|0] "" Vector__XXX
 SG_ ErrorRegisterVoltage : 18|1@1+ (1,0) [0|0] "" Vector__XXX
 SG_ ErrorRegisterCurrent : 17|1@1+ (1,0) [0|0] "" Vector__XXX
 SG_ ErrorRegisterGeneric : 16|1@1+ (1,0) [0|0] "" Vector__XXX
 SG_ ErrorCode : 0|16@1+ (1,0) [0|0] "" Vector__XXX

BO_ 1881 HBGuard_089: 1 Vector__XXX
 SG_ Toggle : 7|1@1+ (1,0) [0|0] "" Vector__XXX
 SG_ State : 0|7@1+ (1,0) [0|0] "" Vector__XXX

BO_ 1497 SSDO_089: 8 Vector__XXX

BO_ 1625 CSDO_089: 8 Vector__XXX

BO_ 217 EMCY_089: 8 Vector__XXX
 SG_ ManufacturerSpecific5 : 56|8@1+ (1,0) [0|0] "" Vector__XXX
 SG_ ManufacturerSpecific4 : 48|8@1+ (1,0) [0|0] "" Vector__XXX
 SG_ ManufacturerSpecific3 : 40|8@1+ (1,0) [0|0] "" Vector__XXX
 SG_ ManufacturerSpecific2 : 32|8@1+ (1,0) [0|0] "" Vector__XXX
 SG_ ManufacturerSpecific1 : 24|8@1+ (1,0) [0|0] "" Vector__XXX
 SG_ ErrorRegisterManufSpecific : 23|1@1+ (1,0) [0|0] "" Vector__XXX
 SG_ ErrorRegisterReserved : 22|1@1+ (1,0) [0|0] "" Vector__XXX
 SG_ ErrorRegisterProfileSpecific : 21|1@1+ (1,0) [0|0] "" Vector__XXX
 SG_ ErrorRegisterCommunication : 20|1@1+ (1,0) [0|0] "" Vector__XXX
 SG_ ErrorRegisterTemperature : 19|1@1+ (1,0) [0|0] "" Vector__XXX
 SG_ ErrorRegisterVoltage : 18|1@1+ (1,0) [0|0] "" Vector__XXX
 SG_ ErrorRegisterCurrent : 17|1@1+ (1,0) [0|0] "" Vector__XXX
 SG_ ErrorRegisterGeneric : 16|1@1+ (1,0) [0|0] "" Vector__XXX
 SG_ ErrorCode : 0|16@1+ (1,0) [0|0] "" Vector__XXX

BO_ 1880 HBGuard_088: 1 Vector__XXX
 SG_ Toggle : 7|1@1+ (1,0) [0|0] "" Vector__XXX
 SG_ State : 0|7@1+ (1,0) [0|0] "" Vector__XXX

BO_ 1496 SSDO_088: 8 Vector__XXX

BO_ 1624 CSDO_088: 8 Vector__XXX

BO_ 216 EMCY_088: 8 Vector__XXX
 SG_ ManufacturerSpecific5 : 56|8@1+ (1,0) [0|0] "" Vector__XXX
 SG_ ManufacturerSpecific4 : 48|8@1+ (1,0) [0|0] "" Vector__XXX
 SG_ ManufacturerSpecific3 : 40|8@1+ (1,0) [0|0] "" Vector__XXX
 SG_ ManufacturerSpecific2 : 32|8@1+ (1,0) [0|0] "" Vector__XXX
 SG_ ManufacturerSpecific1 : 24|8@1+ (1,0) [0|0] "" Vector__XXX
 SG_ ErrorRegisterManufSpecific : 23|1@1+ (1,0) [0|0] "" Vector__XXX
 SG_ ErrorRegisterReserved : 22|1@1+ (1,0) [0|0] "" Vector__XXX
 SG_ ErrorRegisterProfileSpecific : 21|1@1+ (1,0) [0|0] "" Vector__XXX
 SG_ ErrorRegisterCommunication : 20|1@1+ (1,0) [0|0] "" Vector__XXX
 SG_ ErrorRegisterTemperature : 19|1@1+ (1,0) [0|0] "" Vector__XXX
 SG_ ErrorRegisterVoltage : 18|1@1+ (1,0) [0|0] "" Vector__XXX
 SG_ ErrorRegisterCurrent : 17|1@1+ (1,0) [0|0] "" Vector__XXX
 SG_ ErrorRegisterGeneric : 16|1@1+ (1,0) [0|0] "" Vector__XXX
 SG_ ErrorCode : 0|16@1+ (1,0) [0|0] "" Vector__XXX

BO_ 1879 HBGuard_087: 1 Vector__XXX
 SG_ Toggle : 7|1@1+ (1,0) [0|0] "" Vector__XXX
 SG_ State : 0|7@1+ (1,0) [0|0] "" Vector__XXX

BO_ 1495 SSDO_087: 8 Vector__XXX

BO_ 1623 CSDO_087: 8 Vector__XXX

BO_ 215 EMCY_087: 8 Vector__XXX
 SG_ ManufacturerSpecific5 : 56|8@1+ (1,0) [0|0] "" Vector__XXX
 SG_ ManufacturerSpecific4 : 48|8@1+ (1,0) [0|0] "" Vector__XXX
 SG_ ManufacturerSpecific3 : 40|8@1+ (1,0) [0|0] "" Vector__XXX
 SG_ ManufacturerSpecific2 : 32|8@1+ (1,0) [0|0] "" Vector__XXX
 SG_ ManufacturerSpecific1 : 24|8@1+ (1,0) [0|0] "" Vector__XXX
 SG_ ErrorRegisterManufSpecific : 23|1@1+ (1,0) [0|0] "" Vector__XXX
 SG_ ErrorRegisterReserved : 22|1@1+ (1,0) [0|0] "" Vector__XXX
 SG_ ErrorRegisterProfileSpecific : 21|1@1+ (1,0) [0|0] "" Vector__XXX
 SG_ ErrorRegisterCommunication : 20|1@1+ (1,0) [0|0] "" Vector__XXX
 SG_ ErrorRegisterTemperature : 19|1@1+ (1,0) [0|0] "" Vector__XXX
 SG_ ErrorRegisterVoltage : 18|1@1+ (1,0) [0|0] "" Vector__XXX
 SG_ ErrorRegisterCurrent : 17|1@1+ (1,0) [0|0] "" Vector__XXX
 SG_ ErrorRegisterGeneric : 16|1@1+ (1,0) [0|0] "" Vector__XXX
 SG_ ErrorCode : 0|16@1+ (1,0) [0|0] "" Vector__XXX

BO_ 1878 HBGuard_086: 1 Vector__XXX
 SG_ Toggle : 7|1@1+ (1,0) [0|0] "" Vector__XXX
 SG_ State : 0|7@1+ (1,0) [0|0] "" Vector__XXX

BO_ 1494 SSDO_086: 8 Vector__XXX

BO_ 1622 CSDO_086: 8 Vector__XXX

BO_ 214 EMCY_086: 8 Vector__XXX
 SG_ ManufacturerSpecific5 : 56|8@1+ (1,0) [0|0] "" Vector__XXX
 SG_ ManufacturerSpecific4 : 48|8@1+ (1,0) [0|0] "" Vector__XXX
 SG_ ManufacturerSpecific3 : 40|8@1+ (1,0) [0|0] "" Vector__XXX
 SG_ ManufacturerSpecific2 : 32|8@1+ (1,0) [0|0] "" Vector__XXX
 SG_ ManufacturerSpecific1 : 24|8@1+ (1,0) [0|0] "" Vector__XXX
 SG_ ErrorRegisterManufSpecific : 23|1@1+ (1,0) [0|0] "" Vector__XXX
 SG_ ErrorRegisterReserved : 22|1@1+ (1,0) [0|0] "" Vector__XXX
 SG_ ErrorRegisterProfileSpecific : 21|1@1+ (1,0) [0|0] "" Vector__XXX
 SG_ ErrorRegisterCommunication : 20|1@1+ (1,0) [0|0] "" Vector__XXX
 SG_ ErrorRegisterTemperature : 19|1@1+ (1,0) [0|0] "" Vector__XXX
 SG_ ErrorRegisterVoltage : 18|1@1+ (1,0) [0|0] "" Vector__XXX
 SG_ ErrorRegisterCurrent : 17|1@1+ (1,0) [0|0] "" Vector__XXX
 SG_ ErrorRegisterGeneric : 16|1@1+ (1,0) [0|0] "" Vector__XXX
 SG_ ErrorCode : 0|16@1+ (1,0) [0|0] "" Vector__XXX

BO_ 1877 HBGuard_085: 1 Vector__XXX
 SG_ Toggle : 7|1@1+ (1,0) [0|0] "" Vector__XXX
 SG_ State : 0|7@1+ (1,0) [0|0] "" Vector__XXX

BO_ 1493 SSDO_085: 8 Vector__XXX

BO_ 1621 CSDO_085: 8 Vector__XXX

BO_ 213 EMCY_085: 8 Vector__XXX
 SG_ ManufacturerSpecific5 : 56|8@1+ (1,0) [0|0] "" Vector__XXX
 SG_ ManufacturerSpecific4 : 48|8@1+ (1,0) [0|0] "" Vector__XXX
 SG_ ManufacturerSpecific3 : 40|8@1+ (1,0) [0|0] "" Vector__XXX
 SG_ ManufacturerSpecific2 : 32|8@1+ (1,0) [0|0] "" Vector__XXX
 SG_ ManufacturerSpecific1 : 24|8@1+ (1,0) [0|0] "" Vector__XXX
 SG_ ErrorRegisterManufSpecific : 23|1@1+ (1,0) [0|0] "" Vector__XXX
 SG_ ErrorRegisterReserved : 22|1@1+ (1,0) [0|0] "" Vector__XXX
 SG_ ErrorRegisterProfileSpecific : 21|1@1+ (1,0) [0|0] "" Vector__XXX
 SG_ ErrorRegisterCommunication : 20|1@1+ (1,0) [0|0] "" Vector__XXX
 SG_ ErrorRegisterTemperature : 19|1@1+ (1,0) [0|0] "" Vector__XXX
 SG_ ErrorRegisterVoltage : 18|1@1+ (1,0) [0|0] "" Vector__XXX
 SG_ ErrorRegisterCurrent : 17|1@1+ (1,0) [0|0] "" Vector__XXX
 SG_ ErrorRegisterGeneric : 16|1@1+ (1,0) [0|0] "" Vector__XXX
 SG_ ErrorCode : 0|16@1+ (1,0) [0|0] "" Vector__XXX

BO_ 1876 HBGuard_084: 1 Vector__XXX
 SG_ Toggle : 7|1@1+ (1,0) [0|0] "" Vector__XXX
 SG_ State : 0|7@1+ (1,0) [0|0] "" Vector__XXX

BO_ 1492 SSDO_084: 8 Vector__XXX

BO_ 1620 CSDO_084: 8 Vector__XXX

BO_ 212 EMCY_084: 8 Vector__XXX
 SG_ ManufacturerSpecific5 : 56|8@1+ (1,0) [0|0] "" Vector__XXX
 SG_ ManufacturerSpecific4 : 48|8@1+ (1,0) [0|0] "" Vector__XXX
 SG_ ManufacturerSpecific3 : 40|8@1+ (1,0) [0|0] "" Vector__XXX
 SG_ ManufacturerSpecific2 : 32|8@1+ (1,0) [0|0] "" Vector__XXX
 SG_ ManufacturerSpecific1 : 24|8@1+ (1,0) [0|0] "" Vector__XXX
 SG_ ErrorRegisterManufSpecific : 23|1@1+ (1,0) [0|0] "" Vector__XXX
 SG_ ErrorRegisterReserved : 22|1@1+ (1,0) [0|0] "" Vector__XXX
 SG_ ErrorRegisterProfileSpecific : 21|1@1+ (1,0) [0|0] "" Vector__XXX
 SG_ ErrorRegisterCommunication : 20|1@1+ (1,0) [0|0] "" Vector__XXX
 SG_ ErrorRegisterTemperature : 19|1@1+ (1,0) [0|0] "" Vector__XXX
 SG_ ErrorRegisterVoltage : 18|1@1+ (1,0) [0|0] "" Vector__XXX
 SG_ ErrorRegisterCurrent : 17|1@1+ (1,0) [0|0] "" Vector__XXX
 SG_ ErrorRegisterGeneric : 16|1@1+ (1,0) [0|0] "" Vector__XXX
 SG_ ErrorCode : 0|16@1+ (1,0) [0|0] "" Vector__XXX

BO_ 1875 HBGuard_083: 1 Vector__XXX
 SG_ Toggle : 7|1@1+ (1,0) [0|0] "" Vector__XXX
 SG_ State : 0|7@1+ (1,0) [0|0] "" Vector__XXX

BO_ 1491 SSDO_083: 8 Vector__XXX

BO_ 1619 CSDO_083: 8 Vector__XXX

BO_ 211 EMCY_083: 8 Vector__XXX
 SG_ ManufacturerSpecific5 : 56|8@1+ (1,0) [0|0] "" Vector__XXX
 SG_ ManufacturerSpecific4 : 48|8@1+ (1,0) [0|0] "" Vector__XXX
 SG_ ManufacturerSpecific3 : 40|8@1+ (1,0) [0|0] "" Vector__XXX
 SG_ ManufacturerSpecific2 : 32|8@1+ (1,0) [0|0] "" Vector__XXX
 SG_ ManufacturerSpecific1 : 24|8@1+ (1,0) [0|0] "" Vector__XXX
 SG_ ErrorRegisterManufSpecific : 23|1@1+ (1,0) [0|0] "" Vector__XXX
 SG_ ErrorRegisterReserved : 22|1@1+ (1,0) [0|0] "" Vector__XXX
 SG_ ErrorRegisterProfileSpecific : 21|1@1+ (1,0) [0|0] "" Vector__XXX
 SG_ ErrorRegisterCommunication : 20|1@1+ (1,0) [0|0] "" Vector__XXX
 SG_ ErrorRegisterTemperature : 19|1@1+ (1,0) [0|0] "" Vector__XXX
 SG_ ErrorRegisterVoltage : 18|1@1+ (1,0) [0|0] "" Vector__XXX
 SG_ ErrorRegisterCurrent : 17|1@1+ (1,0) [0|0] "" Vector__XXX
 SG_ ErrorRegisterGeneric : 16|1@1+ (1,0) [0|0] "" Vector__XXX
 SG_ ErrorCode : 0|16@1+ (1,0) [0|0] "" Vector__XXX

BO_ 1874 HBGuard_082: 1 Vector__XXX
 SG_ Toggle : 7|1@1+ (1,0) [0|0] "" Vector__XXX
 SG_ State : 0|7@1+ (1,0) [0|0] "" Vector__XXX

BO_ 1490 SSDO_082: 8 Vector__XXX

BO_ 1618 CSDO_082: 8 Vector__XXX

BO_ 210 EMCY_082: 8 Vector__XXX
 SG_ ManufacturerSpecific5 : 56|8@1+ (1,0) [0|0] "" Vector__XXX
 SG_ ManufacturerSpecific4 : 48|8@1+ (1,0) [0|0] "" Vector__XXX
 SG_ ManufacturerSpecific3 : 40|8@1+ (1,0) [0|0] "" Vector__XXX
 SG_ ManufacturerSpecific2 : 32|8@1+ (1,0) [0|0] "" Vector__XXX
 SG_ ManufacturerSpecific1 : 24|8@1+ (1,0) [0|0] "" Vector__XXX
 SG_ ErrorRegisterManufSpecific : 23|1@1+ (1,0) [0|0] "" Vector__XXX
 SG_ ErrorRegisterReserved : 22|1@1+ (1,0) [0|0] "" Vector__XXX
 SG_ ErrorRegisterProfileSpecific : 21|1@1+ (1,0) [0|0] "" Vector__XXX
 SG_ ErrorRegisterCommunication : 20|1@1+ (1,0) [0|0] "" Vector__XXX
 SG_ ErrorRegisterTemperature : 19|1@1+ (1,0) [0|0] "" Vector__XXX
 SG_ ErrorRegisterVoltage : 18|1@1+ (1,0) [0|0] "" Vector__XXX
 SG_ ErrorRegisterCurrent : 17|1@1+ (1,0) [0|0] "" Vector__XXX
 SG_ ErrorRegisterGeneric : 16|1@1+ (1,0) [0|0] "" Vector__XXX
 SG_ ErrorCode : 0|16@1+ (1,0) [0|0] "" Vector__XXX

BO_ 1873 HBGuard_081: 1 Vector__XXX
 SG_ Toggle : 7|1@1+ (1,0) [0|0] "" Vector__XXX
 SG_ State : 0|7@1+ (1,0) [0|0] "" Vector__XXX

BO_ 1489 SSDO_081: 8 Vector__XXX

BO_ 1617 CSDO_081: 8 Vector__XXX

BO_ 209 EMCY_081: 8 Vector__XXX
 SG_ ManufacturerSpecific5 : 56|8@1+ (1,0) [0|0] "" Vector__XXX
 SG_ ManufacturerSpecific4 : 48|8@1+ (1,0) [0|0] "" Vector__XXX
 SG_ ManufacturerSpecific3 : 40|8@1+ (1,0) [0|0] "" Vector__XXX
 SG_ ManufacturerSpecific2 : 32|8@1+ (1,0) [0|0] "" Vector__XXX
 SG_ ManufacturerSpecific1 : 24|8@1+ (1,0) [0|0] "" Vector__XXX
 SG_ ErrorRegisterManufSpecific : 23|1@1+ (1,0) [0|0] "" Vector__XXX
 SG_ ErrorRegisterReserved : 22|1@1+ (1,0) [0|0] "" Vector__XXX
 SG_ ErrorRegisterProfileSpecific : 21|1@1+ (1,0) [0|0] "" Vector__XXX
 SG_ ErrorRegisterCommunication : 20|1@1+ (1,0) [0|0] "" Vector__XXX
 SG_ ErrorRegisterTemperature : 19|1@1+ (1,0) [0|0] "" Vector__XXX
 SG_ ErrorRegisterVoltage : 18|1@1+ (1,0) [0|0] "" Vector__XXX
 SG_ ErrorRegisterCurrent : 17|1@1+ (1,0) [0|0] "" Vector__XXX
 SG_ ErrorRegisterGeneric : 16|1@1+ (1,0) [0|0] "" Vector__XXX
 SG_ ErrorCode : 0|16@1+ (1,0) [0|0] "" Vector__XXX

BO_ 1872 HBGuard_080: 1 Vector__XXX
 SG_ Toggle : 7|1@1+ (1,0) [0|0] "" Vector__XXX
 SG_ State : 0|7@1+ (1,0) [0|0] "" Vector__XXX

BO_ 1488 SSDO_080: 8 Vector__XXX

BO_ 1616 CSDO_080: 8 Vector__XXX

BO_ 208 EMCY_080: 8 Vector__XXX
 SG_ ManufacturerSpecific5 : 56|8@1+ (1,0) [0|0] "" Vector__XXX
 SG_ ManufacturerSpecific4 : 48|8@1+ (1,0) [0|0] "" Vector__XXX
 SG_ ManufacturerSpecific3 : 40|8@1+ (1,0) [0|0] "" Vector__XXX
 SG_ ManufacturerSpecific2 : 32|8@1+ (1,0) [0|0] "" Vector__XXX
 SG_ ManufacturerSpecific1 : 24|8@1+ (1,0) [0|0] "" Vector__XXX
 SG_ ErrorRegisterManufSpecific : 23|1@1+ (1,0) [0|0] "" Vector__XXX
 SG_ ErrorRegisterReserved : 22|1@1+ (1,0) [0|0] "" Vector__XXX
 SG_ ErrorRegisterProfileSpecific : 21|1@1+ (1,0) [0|0] "" Vector__XXX
 SG_ ErrorRegisterCommunication : 20|1@1+ (1,0) [0|0] "" Vector__XXX
 SG_ ErrorRegisterTemperature : 19|1@1+ (1,0) [0|0] "" Vector__XXX
 SG_ ErrorRegisterVoltage : 18|1@1+ (1,0) [0|0] "" Vector__XXX
 SG_ ErrorRegisterCurrent : 17|1@1+ (1,0) [0|0] "" Vector__XXX
 SG_ ErrorRegisterGeneric : 16|1@1+ (1,0) [0|0] "" Vector__XXX
 SG_ ErrorCode : 0|16@1+ (1,0) [0|0] "" Vector__XXX

BO_ 1871 HBGuard_079: 1 Vector__XXX
 SG_ Toggle : 7|1@1+ (1,0) [0|0] "" Vector__XXX
 SG_ State : 0|7@1+ (1,0) [0|0] "" Vector__XXX

BO_ 1487 SSDO_079: 8 Vector__XXX

BO_ 1615 CSDO_079: 8 Vector__XXX

BO_ 207 EMCY_079: 8 Vector__XXX
 SG_ ManufacturerSpecific5 : 56|8@1+ (1,0) [0|0] "" Vector__XXX
 SG_ ManufacturerSpecific4 : 48|8@1+ (1,0) [0|0] "" Vector__XXX
 SG_ ManufacturerSpecific3 : 40|8@1+ (1,0) [0|0] "" Vector__XXX
 SG_ ManufacturerSpecific2 : 32|8@1+ (1,0) [0|0] "" Vector__XXX
 SG_ ManufacturerSpecific1 : 24|8@1+ (1,0) [0|0] "" Vector__XXX
 SG_ ErrorRegisterManufSpecific : 23|1@1+ (1,0) [0|0] "" Vector__XXX
 SG_ ErrorRegisterReserved : 22|1@1+ (1,0) [0|0] "" Vector__XXX
 SG_ ErrorRegisterProfileSpecific : 21|1@1+ (1,0) [0|0] "" Vector__XXX
 SG_ ErrorRegisterCommunication : 20|1@1+ (1,0) [0|0] "" Vector__XXX
 SG_ ErrorRegisterTemperature : 19|1@1+ (1,0) [0|0] "" Vector__XXX
 SG_ ErrorRegisterVoltage : 18|1@1+ (1,0) [0|0] "" Vector__XXX
 SG_ ErrorRegisterCurrent : 17|1@1+ (1,0) [0|0] "" Vector__XXX
 SG_ ErrorRegisterGeneric : 16|1@1+ (1,0) [0|0] "" Vector__XXX
 SG_ ErrorCode : 0|16@1+ (1,0) [0|0] "" Vector__XXX

BO_ 1870 HBGuard_078: 1 Vector__XXX
 SG_ Toggle : 7|1@1+ (1,0) [0|0] "" Vector__XXX
 SG_ State : 0|7@1+ (1,0) [0|0] "" Vector__XXX

BO_ 1486 SSDO_078: 8 Vector__XXX

BO_ 1614 CSDO_078: 8 Vector__XXX

BO_ 206 EMCY_078: 8 Vector__XXX
 SG_ ManufacturerSpecific5 : 56|8@1+ (1,0) [0|0] "" Vector__XXX
 SG_ ManufacturerSpecific4 : 48|8@1+ (1,0) [0|0] "" Vector__XXX
 SG_ ManufacturerSpecific3 : 40|8@1+ (1,0) [0|0] "" Vector__XXX
 SG_ ManufacturerSpecific2 : 32|8@1+ (1,0) [0|0] "" Vector__XXX
 SG_ ManufacturerSpecific1 : 24|8@1+ (1,0) [0|0] "" Vector__XXX
 SG_ ErrorRegisterManufSpecific : 23|1@1+ (1,0) [0|0] "" Vector__XXX
 SG_ ErrorRegisterReserved : 22|1@1+ (1,0) [0|0] "" Vector__XXX
 SG_ ErrorRegisterProfileSpecific : 21|1@1+ (1,0) [0|0] "" Vector__XXX
 SG_ ErrorRegisterCommunication : 20|1@1+ (1,0) [0|0] "" Vector__XXX
 SG_ ErrorRegisterTemperature : 19|1@1+ (1,0) [0|0] "" Vector__XXX
 SG_ ErrorRegisterVoltage : 18|1@1+ (1,0) [0|0] "" Vector__XXX
 SG_ ErrorRegisterCurrent : 17|1@1+ (1,0) [0|0] "" Vector__XXX
 SG_ ErrorRegisterGeneric : 16|1@1+ (1,0) [0|0] "" Vector__XXX
 SG_ ErrorCode : 0|16@1+ (1,0) [0|0] "" Vector__XXX

BO_ 1869 HBGuard_077: 1 Vector__XXX
 SG_ Toggle : 7|1@1+ (1,0) [0|0] "" Vector__XXX
 SG_ State : 0|7@1+ (1,0) [0|0] "" Vector__XXX

BO_ 1485 SSDO_077: 8 Vector__XXX

BO_ 1613 CSDO_077: 8 Vector__XXX

BO_ 205 EMCY_077: 8 Vector__XXX
 SG_ ManufacturerSpecific5 : 56|8@1+ (1,0) [0|0] "" Vector__XXX
 SG_ ManufacturerSpecific4 : 48|8@1+ (1,0) [0|0] "" Vector__XXX
 SG_ ManufacturerSpecific3 : 40|8@1+ (1,0) [0|0] "" Vector__XXX
 SG_ ManufacturerSpecific2 : 32|8@1+ (1,0) [0|0] "" Vector__XXX
 SG_ ManufacturerSpecific1 : 24|8@1+ (1,0) [0|0] "" Vector__XXX
 SG_ ErrorRegisterManufSpecific : 23|1@1+ (1,0) [0|0] "" Vector__XXX
 SG_ ErrorRegisterReserved : 22|1@1+ (1,0) [0|0] "" Vector__XXX
 SG_ ErrorRegisterProfileSpecific : 21|1@1+ (1,0) [0|0] "" Vector__XXX
 SG_ ErrorRegisterCommunication : 20|1@1+ (1,0) [0|0] "" Vector__XXX
 SG_ ErrorRegisterTemperature : 19|1@1+ (1,0) [0|0] "" Vector__XXX
 SG_ ErrorRegisterVoltage : 18|1@1+ (1,0) [0|0] "" Vector__XXX
 SG_ ErrorRegisterCurrent : 17|1@1+ (1,0) [0|0] "" Vector__XXX
 SG_ ErrorRegisterGeneric : 16|1@1+ (1,0) [0|0] "" Vector__XXX
 SG_ ErrorCode : 0|16@1+ (1,0) [0|0] "" Vector__XXX

BO_ 1868 HBGuard_076: 1 Vector__XXX
 SG_ Toggle : 7|1@1+ (1,0) [0|0] "" Vector__XXX
 SG_ State : 0|7@1+ (1,0) [0|0] "" Vector__XXX

BO_ 1484 SSDO_076: 8 Vector__XXX

BO_ 1612 CSDO_076: 8 Vector__XXX

BO_ 204 EMCY_076: 8 Vector__XXX
 SG_ ManufacturerSpecific5 : 56|8@1+ (1,0) [0|0] "" Vector__XXX
 SG_ ManufacturerSpecific4 : 48|8@1+ (1,0) [0|0] "" Vector__XXX
 SG_ ManufacturerSpecific3 : 40|8@1+ (1,0) [0|0] "" Vector__XXX
 SG_ ManufacturerSpecific2 : 32|8@1+ (1,0) [0|0] "" Vector__XXX
 SG_ ManufacturerSpecific1 : 24|8@1+ (1,0) [0|0] "" Vector__XXX
 SG_ ErrorRegisterManufSpecific : 23|1@1+ (1,0) [0|0] "" Vector__XXX
 SG_ ErrorRegisterReserved : 22|1@1+ (1,0) [0|0] "" Vector__XXX
 SG_ ErrorRegisterProfileSpecific : 21|1@1+ (1,0) [0|0] "" Vector__XXX
 SG_ ErrorRegisterCommunication : 20|1@1+ (1,0) [0|0] "" Vector__XXX
 SG_ ErrorRegisterTemperature : 19|1@1+ (1,0) [0|0] "" Vector__XXX
 SG_ ErrorRegisterVoltage : 18|1@1+ (1,0) [0|0] "" Vector__XXX
 SG_ ErrorRegisterCurrent : 17|1@1+ (1,0) [0|0] "" Vector__XXX
 SG_ ErrorRegisterGeneric : 16|1@1+ (1,0) [0|0] "" Vector__XXX
 SG_ ErrorCode : 0|16@1+ (1,0) [0|0] "" Vector__XXX

BO_ 1867 HBGuard_075: 1 Vector__XXX
 SG_ Toggle : 7|1@1+ (1,0) [0|0] "" Vector__XXX
 SG_ State : 0|7@1+ (1,0) [0|0] "" Vector__XXX

BO_ 1483 SSDO_075: 8 Vector__XXX

BO_ 1611 CSDO_075: 8 Vector__XXX

BO_ 203 EMCY_075: 8 Vector__XXX
 SG_ ManufacturerSpecific5 : 56|8@1+ (1,0) [0|0] "" Vector__XXX
 SG_ ManufacturerSpecific4 : 48|8@1+ (1,0) [0|0] "" Vector__XXX
 SG_ ManufacturerSpecific3 : 40|8@1+ (1,0) [0|0] "" Vector__XXX
 SG_ ManufacturerSpecific2 : 32|8@1+ (1,0) [0|0] "" Vector__XXX
 SG_ ManufacturerSpecific1 : 24|8@1+ (1,0) [0|0] "" Vector__XXX
 SG_ ErrorRegisterManufSpecific : 23|1@1+ (1,0) [0|0] "" Vector__XXX
 SG_ ErrorRegisterReserved : 22|1@1+ (1,0) [0|0] "" Vector__XXX
 SG_ ErrorRegisterProfileSpecific : 21|1@1+ (1,0) [0|0] "" Vector__XXX
 SG_ ErrorRegisterCommunication : 20|1@1+ (1,0) [0|0] "" Vector__XXX
 SG_ ErrorRegisterTemperature : 19|1@1+ (1,0) [0|0] "" Vector__XXX
 SG_ ErrorRegisterVoltage : 18|1@1+ (1,0) [0|0] "" Vector__XXX
 SG_ ErrorRegisterCurrent : 17|1@1+ (1,0) [0|0] "" Vector__XXX
 SG_ ErrorRegisterGeneric : 16|1@1+ (1,0) [0|0] "" Vector__XXX
 SG_ ErrorCode : 0|16@1+ (1,0) [0|0] "" Vector__XXX

BA_DEF_ BU_  "CO_DCF" STRING ;
BA_DEF_ BU_  "CO_ID" INT 0 127;
BA_DEF_ BU_  "CO_NVSEGMENT0" STRING ;
BA_DEF_ BU_  "CO_NVSEGMENT1" STRING ;
BA_DEF_ BU_  "CO_NVSEGMENT2" STRING ;
BA_DEF_ BU_  "CO_NVSEGMENT3" STRING ;
BA_DEF_ BU_  "CO_NVSEGMENT4" STRING ;
BA_DEF_ BU_  "CO_NVSEGMENT5" STRING ;
BA_DEF_ BU_  "CO_NVSEGMENT6" STRING ;
BA_DEF_ BU_  "CO_NVSEGMENT7" STRING ;
BA_DEF_ BU_  "CO_NVSEGMENT8" STRING ;
BA_DEF_ BU_  "CO_NVSEGMENT9" STRING ;
BA_DEF_ BU_  "CO_NVSEGMENT10" STRING ;
BA_DEF_ BU_  "CO_NVSEGMENT11" STRING ;
BA_DEF_ BU_  "CO_NVSEGMENT12" STRING ;
BA_DEF_ BU_  "CO_NVSEGMENT13" STRING ;
BA_DEF_ BU_  "CO_NVSEGMENT14" STRING ;
BA_DEF_ BU_  "CO_NVSEGMENT15" STRING ;
BA_DEF_ BU_  "CO_NVSEGMENT16" STRING ;
BA_DEF_ BU_  "CO_NVSEGMENT17" STRING ;
BA_DEF_ BU_  "CO_NVSEGMENT18" STRING ;
BA_DEF_ BU_  "CO_NVSEGMENT19" STRING ;
BA_DEF_ BU_  "CO_NVSEGMENT20" STRING ;
BA_DEF_ BU_  "CO_NVSEGMENT21" STRING ;
BA_DEF_ BU_  "CO_NVSEGMENT22" STRING ;
BA_DEF_ BU_  "CO_NVSEGMENT23" STRING ;
BA_DEF_ BU_  "CO_NVSEGMENT24" STRING ;
BA_DEF_ BU_  "CO_NVSEGMENT25" STRING ;
BA_DEF_ BU_  "CO_NVSEGMENT26" STRING ;
BA_DEF_ BU_  "CO_NVSEGMENT27" STRING ;
BA_DEF_ BU_  "CO_NVSEGMENT28" STRING ;
BA_DEF_ BU_  "CO_NVSEGMENT29" STRING ;
BA_DEF_ BU_  "CO_NVSEGMENT30" STRING ;
BA_DEF_ BU_  "CO_NVSEGMENT31" STRING ;
BA_DEF_ BU_  "CO_NVSEGMENT32" STRING ;
BA_DEF_ BU_  "CO_NVSEGMENT33" STRING ;
BA_DEF_ BU_  "CO_NVSEGMENT34" STRING ;
BA_DEF_ BU_  "CO_NVSEGMENT35" STRING ;
BA_DEF_ BU_  "CO_NVSEGMENT36" STRING ;
BA_DEF_ BU_  "CO_NVSEGMENT37" STRING ;
BA_DEF_ BU_  "CO_NVSEGMENT38" STRING ;
BA_DEF_ BU_  "CO_NVSEGMENT39" STRING ;
BA_DEF_ BU_  "CO_NVSEGMENT40" STRING ;
BA_DEF_ BU_  "CO_NVSEGMENT41" STRING ;
BA_DEF_ BU_  "CO_NVSEGMENT42" STRING ;
BA_DEF_ BU_  "CO_NVSEGMENT43" STRING ;
BA_DEF_ BU_  "CO_NVSEGMENT44" STRING ;
BA_DEF_ BU_  "CO_NVSEGMENT45" STRING ;
BA_DEF_  "OptionLoadDCF" INT 0 1;
BA_DEF_ BO_  "GenMsgSendType" ENUM  "Cyclic","SendType1","SendType2","SendType3","SendType4","SendType5","SendType6","SendType7","SendType8","SendType9";
BA_DEF_ SG_  "GenSigStartValue" INT 0 0;
BA_DEF_ BO_  "CO_MsgCategory" INT 0 0;
BA_DEF_  "CO_MsgColourSupported" INT 0 1;
BA_DEF_  "GeneratedBy" STRING ;
BA_DEF_  "CANopenApplProfile" INT 0 0;
BA_DEF_  "ProtocolType" STRING ;
BA_DEF_  "AUTOGENERATION" INT 0 1;
BA_DEF_ SG_  "SystemSignalLongSymbol" STRING ;
BA_DEF_DEF_  "CO_DCF" "";
BA_DEF_DEF_  "CO_ID" 0;
BA_DEF_DEF_  "CO_NVSEGMENT0" "";
BA_DEF_DEF_  "CO_NVSEGMENT1" "";
BA_DEF_DEF_  "CO_NVSEGMENT2" "";
BA_DEF_DEF_  "CO_NVSEGMENT3" "";
BA_DEF_DEF_  "CO_NVSEGMENT4" "";
BA_DEF_DEF_  "CO_NVSEGMENT5" "";
BA_DEF_DEF_  "CO_NVSEGMENT6" "";
BA_DEF_DEF_  "CO_NVSEGMENT7" "";
BA_DEF_DEF_  "CO_NVSEGMENT8" "";
BA_DEF_DEF_  "CO_NVSEGMENT9" "";
BA_DEF_DEF_  "CO_NVSEGMENT10" "";
BA_DEF_DEF_  "CO_NVSEGMENT11" "";
BA_DEF_DEF_  "CO_NVSEGMENT12" "";
BA_DEF_DEF_  "CO_NVSEGMENT13" "";
BA_DEF_DEF_  "CO_NVSEGMENT14" "";
BA_DEF_DEF_  "CO_NVSEGMENT15" "";
BA_DEF_DEF_  "CO_NVSEGMENT16" "";
BA_DEF_DEF_  "CO_NVSEGMENT17" "";
BA_DEF_DEF_  "CO_NVSEGMENT18" "";
BA_DEF_DEF_  "CO_NVSEGMENT19" "";
BA_DEF_DEF_  "CO_NVSEGMENT20" "";
BA_DEF_DEF_  "CO_NVSEGMENT21" "";
BA_DEF_DEF_  "CO_NVSEGMENT22" "";
BA_DEF_DEF_  "CO_NVSEGMENT23" "";
BA_DEF_DEF_  "CO_NVSEGMENT24" "";
BA_DEF_DEF_  "CO_NVSEGMENT25" "";
BA_DEF_DEF_  "CO_NVSEGMENT26" "";
BA_DEF_DEF_  "CO_NVSEGMENT27" "";
BA_DEF_DEF_  "CO_NVSEGMENT28" "";
BA_DEF_DEF_  "CO_NVSEGMENT29" "";
BA_DEF_DEF_  "CO_NVSEGMENT30" "";
BA_DEF_DEF_  "CO_NVSEGMENT31" "";
BA_DEF_DEF_  "CO_NVSEGMENT32" "";
BA_DEF_DEF_  "CO_NVSEGMENT33" "";
BA_DEF_DEF_  "CO_NVSEGMENT34" "";
BA_DEF_DEF_  "CO_NVSEGMENT35" "";
BA_DEF_DEF_  "CO_NVSEGMENT36" "";
BA_DEF_DEF_  "CO_NVSEGMENT37" "";
BA_DEF_DEF_  "CO_NVSEGMENT38" "";
BA_DEF_DEF_  "CO_NVSEGMENT39" "";
BA_DEF_DEF_  "CO_NVSEGMENT40" "";
BA_DEF_DEF_  "CO_NVSEGMENT41" "";
BA_DEF_DEF_  "CO_NVSEGMENT42" "";
BA_DEF_DEF_  "CO_NVSEGMENT43" "";
BA_DEF_DEF_  "CO_NVSEGMENT44" "";
BA_DEF_DEF_  "CO_NVSEGMENT45" "";
BA_DEF_DEF_  "OptionLoadDCF" 0;
BA_DEF_DEF_  "GenMsgSendType" "(null)";
BA_DEF_DEF_  "GenSigStartValue" 0;
BA_DEF_DEF_  "CO_MsgCategory" 0;
BA_DEF_DEF_  "CO_MsgColourSupported" 1;
BA_DEF_DEF_  "GeneratedBy" "";
BA_DEF_DEF_  "CANopenApplProfile" 301;
BA_DEF_DEF_  "ProtocolType" "CANopen";
BA_DEF_DEF_  "AUTOGENERATION" 0;
BA_DEF_DEF_  "SystemSignalLongSymbol" "";
BA_ "OptionLoadDCF" 1;
BA_ "GeneratedBy" "Vector ProCANopen";
BA_ "AUTOGENERATION" 1;
BA_ "CO_DCF" BU_ VCU "..\D008.DCF";
BA_ "CO_ID" BU_ VCU 8;
BA_ "CO_MsgCategory" BO_ 1800 505;
BA_ "CO_MsgCategory" BO_ 1416 410;
BA_ "CO_MsgCategory" BO_ 1544 405;
BA_ "CO_MsgCategory" BO_ 136 205;
BA_ "CO_MsgCategory" BO_ 1919 505;
BA_ "CO_MsgCategory" BO_ 1535 410;
BA_ "CO_MsgCategory" BO_ 1663 405;
BA_ "CO_MsgCategory" BO_ 255 205;
BA_ "CO_MsgCategory" BO_ 1918 505;
BA_ "CO_MsgCategory" BO_ 1534 410;
BA_ "CO_MsgCategory" BO_ 1662 405;
BA_ "CO_MsgCategory" BO_ 254 205;
BA_ "CO_MsgCategory" BO_ 1917 505;
BA_ "CO_MsgCategory" BO_ 1533 410;
BA_ "CO_MsgCategory" BO_ 1661 405;
BA_ "CO_MsgCategory" BO_ 253 205;
BA_ "CO_MsgCategory" BO_ 1916 505;
BA_ "CO_MsgCategory" BO_ 1532 410;
BA_ "CO_MsgCategory" BO_ 1660 405;
BA_ "CO_MsgCategory" BO_ 252 205;
BA_ "CO_MsgCategory" BO_ 1915 505;
BA_ "CO_MsgCategory" BO_ 1531 410;
BA_ "CO_MsgCategory" BO_ 1659 405;
BA_ "CO_MsgCategory" BO_ 251 205;
BA_ "CO_MsgCategory" BO_ 1914 505;
BA_ "CO_MsgCategory" BO_ 1530 410;
BA_ "CO_MsgCategory" BO_ 1658 405;
BA_ "CO_MsgCategory" BO_ 250 205;
BA_ "CO_MsgCategory" BO_ 1913 505;
BA_ "CO_MsgCategory" BO_ 1529 410;
BA_ "CO_MsgCategory" BO_ 1657 405;
BA_ "CO_MsgCategory" BO_ 249 205;
BA_ "CO_MsgCategory" BO_ 1912 505;
BA_ "CO_MsgCategory" BO_ 1528 410;
BA_ "CO_MsgCategory" BO_ 1656 405;
BA_ "CO_MsgCategory" BO_ 248 205;
BA_ "CO_MsgCategory" BO_ 1911 505;
BA_ "CO_MsgCategory" BO_ 1527 410;
BA_ "CO_MsgCategory" BO_ 1655 405;
BA_ "CO_MsgCategory" BO_ 247 205;
BA_ "CO_MsgCategory" BO_ 1910 505;
BA_ "CO_MsgCategory" BO_ 1526 410;
BA_ "CO_MsgCategory" BO_ 1654 405;
BA_ "CO_MsgCategory" BO_ 246 205;
BA_ "CO_MsgCategory" BO_ 1909 505;
BA_ "CO_MsgCategory" BO_ 1525 410;
BA_ "CO_MsgCategory" BO_ 1653 405;
BA_ "CO_MsgCategory" BO_ 245 205;
BA_ "CO_MsgCategory" BO_ 1908 505;
BA_ "CO_MsgCategory" BO_ 1524 410;
BA_ "CO_MsgCategory" BO_ 1652 405;
BA_ "CO_MsgCategory" BO_ 244 205;
BA_ "CO_MsgCategory" BO_ 1907 505;
BA_ "CO_MsgCategory" BO_ 1523 410;
BA_ "CO_MsgCategory" BO_ 1651 405;
BA_ "CO_MsgCategory" BO_ 243 205;
BA_ "CO_MsgCategory" BO_ 1906 505;
BA_ "CO_MsgCategory" BO_ 1522 410;
BA_ "CO_MsgCategory" BO_ 1650 405;
BA_ "CO_MsgCategory" BO_ 242 205;
BA_ "CO_MsgCategory" BO_ 1905 505;
BA_ "CO_MsgCategory" BO_ 1521 410;
BA_ "CO_MsgCategory" BO_ 1649 405;
BA_ "CO_MsgCategory" BO_ 241 205;
BA_ "CO_MsgCategory" BO_ 1904 505;
BA_ "CO_MsgCategory" BO_ 1520 410;
BA_ "CO_MsgCategory" BO_ 1648 405;
BA_ "CO_MsgCategory" BO_ 240 205;
BA_ "CO_MsgCategory" BO_ 1903 505;
BA_ "CO_MsgCategory" BO_ 1519 410;
BA_ "CO_MsgCategory" BO_ 1647 405;
BA_ "CO_MsgCategory" BO_ 239 205;
BA_ "CO_MsgCategory" BO_ 1902 505;
BA_ "CO_MsgCategory" BO_ 1518 410;
BA_ "CO_MsgCategory" BO_ 1646 405;
BA_ "CO_MsgCategory" BO_ 238 205;
BA_ "CO_MsgCategory" BO_ 1901 505;
BA_ "CO_MsgCategory" BO_ 1517 410;
BA_ "CO_MsgCategory" BO_ 1645 405;
BA_ "CO_MsgCategory" BO_ 237 205;
BA_ "CO_MsgCategory" BO_ 1900 505;
BA_ "CO_MsgCategory" BO_ 1516 410;
BA_ "CO_MsgCategory" BO_ 1644 405;
BA_ "CO_MsgCategory" BO_ 236 205;
BA_ "CO_MsgCategory" BO_ 1899 505;
BA_ "CO_MsgCategory" BO_ 1515 410;
BA_ "CO_MsgCategory" BO_ 1643 405;
BA_ "CO_MsgCategory" BO_ 235 205;
BA_ "CO_MsgCategory" BO_ 1898 505;
BA_ "CO_MsgCategory" BO_ 1514 410;
BA_ "CO_MsgCategory" BO_ 1642 405;
BA_ "CO_MsgCategory" BO_ 234 205;
BA_ "CO_MsgCategory" BO_ 1897 505;
BA_ "CO_MsgCategory" BO_ 1513 410;
BA_ "CO_MsgCategory" BO_ 1641 405;
BA_ "CO_MsgCategory" BO_ 233 205;
BA_ "CO_MsgCategory" BO_ 1896 505;
BA_ "CO_MsgCategory" BO_ 1512 410;
BA_ "CO_MsgCategory" BO_ 1640 405;
BA_ "CO_MsgCategory" BO_ 232 205;
BA_ "CO_MsgCategory" BO_ 1895 505;
BA_ "CO_MsgCategory" BO_ 1511 410;
BA_ "CO_MsgCategory" BO_ 1639 405;
BA_ "CO_MsgCategory" BO_ 231 205;
BA_ "CO_MsgCategory" BO_ 1894 505;
BA_ "CO_MsgCategory" BO_ 1510 410;
BA_ "CO_MsgCategory" BO_ 1638 405;
BA_ "CO_MsgCategory" BO_ 230 205;
BA_ "CO_MsgCategory" BO_ 1893 505;
BA_ "CO_MsgCategory" BO_ 1509 410;
BA_ "CO_MsgCategory" BO_ 1637 405;
BA_ "CO_MsgCategory" BO_ 229 205;
BA_ "CO_MsgCategory" BO_ 1892 505;
BA_ "CO_MsgCategory" BO_ 1508 410;
BA_ "CO_MsgCategory" BO_ 1636 405;
BA_ "CO_MsgCategory" BO_ 228 205;
BA_ "CO_MsgCategory" BO_ 1891 505;
BA_ "CO_MsgCategory" BO_ 1507 410;
BA_ "CO_MsgCategory" BO_ 1635 405;
BA_ "CO_MsgCategory" BO_ 227 205;
BA_ "CO_MsgCategory" BO_ 1890 505;
BA_ "CO_MsgCategory" BO_ 1506 410;
BA_ "CO_MsgCategory" BO_ 1634 405;
BA_ "CO_MsgCategory" BO_ 226 205;
BA_ "CO_MsgCategory" BO_ 1889 505;
BA_ "CO_MsgCategory" BO_ 1505 410;
BA_ "CO_MsgCategory" BO_ 1633 405;
BA_ "CO_MsgCategory" BO_ 225 205;
BA_ "CO_MsgCategory" BO_ 1888 505;
BA_ "CO_MsgCategory" BO_ 1504 410;
BA_ "CO_MsgCategory" BO_ 1632 405;
BA_ "CO_MsgCategory" BO_ 224 205;
BA_ "CO_MsgCategory" BO_ 1887 505;
BA_ "CO_MsgCategory" BO_ 1503 410;
BA_ "CO_MsgCategory" BO_ 1631 405;
BA_ "CO_MsgCategory" BO_ 223 205;
BA_ "CO_MsgCategory" BO_ 1886 505;
BA_ "CO_MsgCategory" BO_ 1502 410;
BA_ "CO_MsgCategory" BO_ 1630 405;
BA_ "CO_MsgCategory" BO_ 222 205;
BA_ "CO_MsgCategory" BO_ 1885 505;
BA_ "CO_MsgCategory" BO_ 1501 410;
BA_ "CO_MsgCategory" BO_ 1629 405;
BA_ "CO_MsgCategory" BO_ 221 205;
BA_ "CO_MsgCategory" BO_ 1884 505;
BA_ "CO_MsgCategory" BO_ 1500 410;
BA_ "CO_MsgCategory" BO_ 1628 405;
BA_ "CO_MsgCategory" BO_ 220 205;
BA_ "CO_MsgCategory" BO_ 1883 505;
BA_ "CO_MsgCategory" BO_ 1499 410;
BA_ "CO_MsgCategory" BO_ 1627 405;
BA_ "CO_MsgCategory" BO_ 219 205;
BA_ "CO_MsgCategory" BO_ 1882 505;
BA_ "CO_MsgCategory" BO_ 1498 410;
BA_ "CO_MsgCategory" BO_ 1626 405;
BA_ "CO_MsgCategory" BO_ 218 205;
BA_ "CO_MsgCategory" BO_ 1881 505;
BA_ "CO_MsgCategory" BO_ 1497 410;
BA_ "CO_MsgCategory" BO_ 1625 405;
BA_ "CO_MsgCategory" BO_ 217 205;
BA_ "CO_MsgCategory" BO_ 1880 505;
BA_ "CO_MsgCategory" BO_ 1496 410;
BA_ "CO_MsgCategory" BO_ 1624 405;
BA_ "CO_MsgCategory" BO_ 216 205;
BA_ "CO_MsgCategory" BO_ 1879 505;
BA_ "CO_MsgCategory" BO_ 1495 410;
BA_ "CO_MsgCategory" BO_ 1623 405;
BA_ "CO_MsgCategory" BO_ 215 205;
BA_ "CO_MsgCategory" BO_ 1878 505;
BA_ "CO_MsgCategory" BO_ 1494 410;
BA_ "CO_MsgCategory" BO_ 1622 405;
BA_ "CO_MsgCategory" BO_ 214 205;
BA_ "CO_MsgCategory" BO_ 1877 505;
BA_ "CO_MsgCategory" BO_ 1493 410;
BA_ "CO_MsgCategory" BO_ 1621 405;
BA_ "CO_MsgCategory" BO_ 213 205;
BA_ "CO_MsgCategory" BO_ 1876 505;
BA_ "CO_MsgCategory" BO_ 1492 410;
BA_ "CO_MsgCategory" BO_ 1620 405;
BA_ "CO_MsgCategory" BO_ 212 205;
BA_ "CO_MsgCategory" BO_ 1875 505;
BA_ "CO_MsgCategory" BO_ 1491 410;
BA_ "CO_MsgCategory" BO_ 1619 405;
BA_ "CO_MsgCategory" BO_ 211 205;
BA_ "CO_MsgCategory" BO_ 1874 505;
BA_ "CO_MsgCategory" BO_ 1490 410;
BA_ "CO_MsgCategory" BO_ 1618 405;
BA_ "CO_MsgCategory" BO_ 210 205;
BA_ "CO_MsgCategory" BO_ 1873 505;
BA_ "CO_MsgCategory" BO_ 1489 410;
BA_ "CO_MsgCategory" BO_ 1617 405;
BA_ "CO_MsgCategory" BO_ 209 205;
BA_ "CO_MsgCategory" BO_ 1872 505;
BA_ "CO_MsgCategory" BO_ 1488 410;
BA_ "CO_MsgCategory" BO_ 1616 405;
BA_ "CO_MsgCategory" BO_ 208 205;
BA_ "CO_MsgCategory" BO_ 1871 505;
BA_ "CO_MsgCategory" BO_ 1487 410;
BA_ "CO_MsgCategory" BO_ 1615 405;
BA_ "CO_MsgCategory" BO_ 207 205;
BA_ "CO_MsgCategory" BO_ 1870 505;
BA_ "CO_MsgCategory" BO_ 1486 410;
BA_ "CO_MsgCategory" BO_ 1614 405;
BA_ "CO_MsgCategory" BO_ 206 205;
BA_ "CO_MsgCategory" BO_ 1869 505;
BA_ "CO_MsgCategory" BO_ 1485 410;
BA_ "CO_MsgCategory" BO_ 1613 405;
BA_ "CO_MsgCategory" BO_ 205 205;
BA_ "CO_MsgCategory" BO_ 1868 505;
BA_ "CO_MsgCategory" BO_ 1484 410;
BA_ "CO_MsgCategory" BO_ 1612 405;
BA_ "CO_MsgCategory" BO_ 204 205;
BA_ "CO_MsgCategory" BO_ 1867 505;
BA_ "CO_MsgCategory" BO_ 1483 410;
BA_ "CO_MsgCategory" BO_ 1611 405;
BA_ "CO_MsgCategory" BO_ 203 205;
BA_ "GenSigStartValue" SG_ 1416 Forward_Enable_6001_00 3;
BA_ "GenSigStartValue" SG_ 1416 PDOMapEntry_1A03_01 1610810384;
BA_ "GenSigStartValue" SG_ 1416 NrOfEntries_1_1A03_00 1;
BA_ "GenSigStartValue" SG_ 1416 Transmit_PDO_Mapping_Parameter_0 1610810128;
BA_ "SystemSignalLongSymbol" SG_ 1416 Transmit_PDO_Mapping_Parameter_0 "Transmit_PDO_Mapping_Parameter_0_sub4_1A02_04";
BA_ "GenSigStartValue" SG_ 1416 PDOMapEntry_1A02_03 1610809872;
BA_ "GenSigStartValue" SG_ 1416 PDOMapEntry_1A02_02 1610809616;
BA_ "GenSigStartValue" SG_ 1416 PDOMapEntry_1A02_01 1610809360;
BA_ "GenSigStartValue" SG_ 1416 NrOfEntries_1_1A02_00 4;
BA_ "GenSigStartValue" SG_ 1416 Transmit_PDO_Mapping_Parame_0000 1610744577;
BA_ "SystemSignalLongSymbol" SG_ 1416 Transmit_PDO_Mapping_Parame_0000 "Transmit_PDO_Mapping_Parameter_0_sub4_1A01_04";
BA_ "GenSigStartValue" SG_ 1416 PDOMapEntry_1A01_03 1610744321;
BA_ "GenSigStartValue" SG_ 1416 PDOMapEntry_1A01_02 1610744065;
BA_ "GenSigStartValue" SG_ 1416 PDOMapEntry_1A01_01 1610743809;
BA_ "GenSigStartValue" SG_ 1416 NrOfEntries_1_1A01_00 4;
BA_ "GenSigStartValue" SG_ 1416 Transmit_PDO_Mapping_Parame_0001 1610679056;
BA_ "SystemSignalLongSymbol" SG_ 1416 Transmit_PDO_Mapping_Parame_0001 "Transmit_PDO_Mapping_Parameter_0_sub4_1A00_04";
BA_ "GenSigStartValue" SG_ 1416 Transmit_PDO_Mapping_Parame_0002 1610678785;
BA_ "SystemSignalLongSymbol" SG_ 1416 Transmit_PDO_Mapping_Parame_0002 "Transmit_PDO_Mapping_Parameter_0_sub3_1A00_03";
BA_ "GenSigStartValue" SG_ 1416 PDOMapEntry_2_1A00_02 1610678529;
BA_ "GenSigStartValue" SG_ 1416 PDOMapEntry_1_1A00_01 1610678273;
BA_ "GenSigStartValue" SG_ 1416 NrOfEntries_1_1A00_00 8;
BA_ "GenSigStartValue" SG_ 1416 COB_ID_1803_01 1160;
BA_ "GenSigStartValue" SG_ 1416 Highest_sub_index_supported_1803 6;
BA_ "SystemSignalLongSymbol" SG_ 1416 Highest_sub_index_supported_1803 "Highest_sub_index_supported_1803_00";
BA_ "GenSigStartValue" SG_ 1416 COB_ID_1802_01 904;
BA_ "GenSigStartValue" SG_ 1416 Highest_sub_index_supported_1802 6;
BA_ "SystemSignalLongSymbol" SG_ 1416 Highest_sub_index_supported_1802 "Highest_sub_index_supported_1802_00";
BA_ "GenSigStartValue" SG_ 1416 COB_ID_1801_01 648;
BA_ "GenSigStartValue" SG_ 1416 Highest_sub_index_supported_1801 6;
BA_ "SystemSignalLongSymbol" SG_ 1416 Highest_sub_index_supported_1801 "Highest_sub_index_supported_1801_00";
BA_ "GenSigStartValue" SG_ 1416 COB_ID_1800_01 392;
BA_ "GenSigStartValue" SG_ 1416 Highest_sub_index_supported_1800 6;
BA_ "SystemSignalLongSymbol" SG_ 1416 Highest_sub_index_supported_1800 "Highest_sub_index_supported_1800_00";
BA_ "GenSigStartValue" SG_ 1416 Highest_sub_index_supported_1018 4;
BA_ "SystemSignalLongSymbol" SG_ 1416 Highest_sub_index_supported_1018 "Highest_sub_index_supported_1018_00";
BA_ "GenSigStartValue" SG_ 1416 Device_Type_1000 419;
BA_ "GenSigStartValue" SG_ 1416 Index 4096;
BA_ "GenSigStartValue" SG_ 1544 Forward_Enable_6001_00 3;
BA_ "GenSigStartValue" SG_ 1544 PDOMapEntry_1A03_01 1610810384;
BA_ "GenSigStartValue" SG_ 1544 NrOfEntries_1_1A03_00 1;
BA_ "GenSigStartValue" SG_ 1544 Transmit_PDO_Mapping_Parame_0003 1610810128;
BA_ "SystemSignalLongSymbol" SG_ 1544 Transmit_PDO_Mapping_Parame_0003 "Transmit_PDO_Mapping_Parameter_0_sub4_1A02_04";
BA_ "GenSigStartValue" SG_ 1544 PDOMapEntry_1A02_03 1610809872;
BA_ "GenSigStartValue" SG_ 1544 PDOMapEntry_1A02_02 1610809616;
BA_ "GenSigStartValue" SG_ 1544 PDOMapEntry_1A02_01 1610809360;
BA_ "GenSigStartValue" SG_ 1544 NrOfEntries_1_1A02_00 4;
BA_ "GenSigStartValue" SG_ 1544 Transmit_PDO_Mapping_Parame_0004 1610744577;
BA_ "SystemSignalLongSymbol" SG_ 1544 Transmit_PDO_Mapping_Parame_0004 "Transmit_PDO_Mapping_Parameter_0_sub4_1A01_04";
BA_ "GenSigStartValue" SG_ 1544 PDOMapEntry_1A01_03 1610744321;
BA_ "GenSigStartValue" SG_ 1544 PDOMapEntry_1A01_02 1610744065;
BA_ "GenSigStartValue" SG_ 1544 PDOMapEntry_1A01_01 1610743809;
BA_ "GenSigStartValue" SG_ 1544 NrOfEntries_1_1A01_00 4;
BA_ "GenSigStartValue" SG_ 1544 Transmit_PDO_Mapping_Parame_0005 1610679056;
BA_ "SystemSignalLongSymbol" SG_ 1544 Transmit_PDO_Mapping_Parame_0005 "Transmit_PDO_Mapping_Parameter_0_sub4_1A00_04";
BA_ "GenSigStartValue" SG_ 1544 Transmit_PDO_Mapping_Parame_0006 1610678785;
BA_ "SystemSignalLongSymbol" SG_ 1544 Transmit_PDO_Mapping_Parame_0006 "Transmit_PDO_Mapping_Parameter_0_sub3_1A00_03";
BA_ "GenSigStartValue" SG_ 1544 PDOMapEntry_2_1A00_02 1610678529;
BA_ "GenSigStartValue" SG_ 1544 PDOMapEntry_1_1A00_01 1610678273;
BA_ "GenSigStartValue" SG_ 1544 NrOfEntries_1_1A00_00 8;
BA_ "GenSigStartValue" SG_ 1544 COB_ID_1803_01 1160;
BA_ "GenSigStartValue" SG_ 1544 Highest_sub_index_supported_0000 6;
BA_ "SystemSignalLongSymbol" SG_ 1544 Highest_sub_index_supported_0000 "Highest_sub_index_supported_1803_00";
BA_ "GenSigStartValue" SG_ 1544 COB_ID_1802_01 904;
BA_ "GenSigStartValue" SG_ 1544 Highest_sub_index_supported_0001 6;
BA_ "SystemSignalLongSymbol" SG_ 1544 Highest_sub_index_supported_0001 "Highest_sub_index_supported_1802_00";
BA_ "GenSigStartValue" SG_ 1544 COB_ID_1801_01 648;
BA_ "GenSigStartValue" SG_ 1544 Highest_sub_index_supported_0002 6;
BA_ "SystemSignalLongSymbol" SG_ 1544 Highest_sub_index_supported_0002 "Highest_sub_index_supported_1801_00";
BA_ "GenSigStartValue" SG_ 1544 COB_ID_1800_01 392;
BA_ "GenSigStartValue" SG_ 1544 Highest_sub_index_supported_0003 6;
BA_ "SystemSignalLongSymbol" SG_ 1544 Highest_sub_index_supported_0003 "Highest_sub_index_supported_1800_00";
BA_ "GenSigStartValue" SG_ 1544 Highest_sub_index_supported_0004 4;
BA_ "SystemSignalLongSymbol" SG_ 1544 Highest_sub_index_supported_0004 "Highest_sub_index_supported_1018_00";
BA_ "GenSigStartValue" SG_ 1544 Device_Type_1000 419;
BA_ "GenSigStartValue" SG_ 1544 Index 4096;
VAL_ 1800 State 127 "PreOperational" 5 "Operational" 4 "Stopped" 0 "Bootup" ;
VAL_ 1416 SubIndex_6003 4 "Joe" 3 "Currly" 2 "Moe" 1 "Bob" 0 "UC STATE" ;
VAL_ 1416 SubIndex_6002 3 "Harp Bit 3" 2 "Harp Bit 2" 1 "Harp Bit 1" 0 "Harp Bit 0" ;
VAL_ 1416 SubIndex_6001 3 "Throttle" 2 "Start" 1 "Brake" 0 "Forward_Enable" ;
VAL_ 1416 SubIndex_1A03 1 "PDOMapEntry" 0 "NrOfEntries_1" ;
VAL_ 1416 SubIndex_1A02 4 "Transmit PDO Mapping Parameter 0_sub4" 3 "PDOMapEntry" 0 "NrOfEntries_1" ;
VAL_ 1416 SubIndex_1A01 4 "Transmit PDO Mapping Parameter 0_sub4" 3 "PDOMapEntry" 0 "NrOfEntries_1" ;
VAL_ 1416 SubIndex_1A00 4 "Transmit PDO Mapping Parameter 0_sub4" 3 "Transmit PDO Mapping Parameter 0_sub3" 2 "PDOMapEntry_2" 1 "PDOMapEntry_1" 0 "NrOfEntries_1" ;
VAL_ 1416 SubIndex_1803 6 "SYNC start value" 5 "Event Timer" 4 "Compatibility Entry" 3 "Inhibit Time" 2 "TransmissionType" 1 "COB-ID" 0 "Highest sub-index supported" ;
VAL_ 1416 SubIndex_1802 6 "SYNC start value" 5 "Event Timer" 4 "Compatibility Entry" 3 "Inhibit Time" 2 "TransmissionType" 1 "COB-ID" 0 "Highest sub-index supported" ;
VAL_ 1416 SubIndex_1801 6 "SYNC start value" 5 "Event Timer" 4 "Compatibility Entry" 3 "Inhibit Time" 2 "TransmissionType" 1 "COB-ID" 0 "Highest sub-index supported" ;
VAL_ 1416 SubIndex_1800 6 "SYNC start value" 5 "Event Timer" 4 "Compatibility Entry" 3 "Inhibit Time" 2 "TransmissionType" 1 "COB-ID" 0 "Highest sub-index supported" ;
VAL_ 1416 SubIndex_1018 4 "Serial number" 3 "Revision number" 2 "Product Code" 1 "Vendor Id" 0 "Highest sub-index supported" ;
VAL_ 1416 SubIndex_1001 0 "Error Register" ;
VAL_ 1416 SubIndex_1000 0 "Device Type" ;
VAL_ 1416 Index 24579 "data_16_ints" 24578 "receive_data_buffer" 24577 "LVSS signals" 6659 "Transmit PDO Mapping Parameter 0" 6147 "Transmit PDO Communication Parameter 3" 6146 "Transmit PDO Communication Parameter 2" 6145 "Transmit PDO Communication Parameter 1" 6144 "Transmit PDO Communication Parameter 0" 4120 "Identity Object" 4097 "Error Register" 4096 "Device Type" ;
VAL_ 1416 TransferType 1 "Expedited transfer" 0 "Normal transfer" ;
VAL_ 1416 SizeIndicator 1 "Size is indicated" 0 "Size is not indicated" ;
VAL_ 1416 SCS 2 "Upload" 1 "Download" ;
VAL_ 1544 SubIndex_6003 4 "Joe" 3 "Currly" 2 "Moe" 1 "Bob" 0 "UC STATE" ;
VAL_ 1544 SubIndex_6002 3 "Harp Bit 3" 2 "Harp Bit 2" 1 "Harp Bit 1" 0 "Harp Bit 0" ;
VAL_ 1544 SubIndex_6001 3 "Throttle" 2 "Start" 1 "Brake" 0 "Forward_Enable" ;
VAL_ 1544 SubIndex_1A03 1 "PDOMapEntry" 0 "NrOfEntries_1" ;
VAL_ 1544 SubIndex_1A02 4 "Transmit PDO Mapping Parameter 0_sub4" 3 "PDOMapEntry" 0 "NrOfEntries_1" ;
VAL_ 1544 SubIndex_1A01 4 "Transmit PDO Mapping Parameter 0_sub4" 3 "PDOMapEntry" 0 "NrOfEntries_1" ;
VAL_ 1544 SubIndex_1A00 4 "Transmit PDO Mapping Parameter 0_sub4" 3 "Transmit PDO Mapping Parameter 0_sub3" 2 "PDOMapEntry_2" 1 "PDOMapEntry_1" 0 "NrOfEntries_1" ;
VAL_ 1544 SubIndex_1803 6 "SYNC start value" 5 "Event Timer" 4 "Compatibility Entry" 3 "Inhibit Time" 2 "TransmissionType" 1 "COB-ID" 0 "Highest sub-index supported" ;
VAL_ 1544 SubIndex_1802 6 "SYNC start value" 5 "Event Timer" 4 "Compatibility Entry" 3 "Inhibit Time" 2 "TransmissionType" 1 "COB-ID" 0 "Highest sub-index supported" ;
VAL_ 1544 SubIndex_1801 6 "SYNC start value" 5 "Event Timer" 4 "Compatibility Entry" 3 "Inhibit Time" 2 "TransmissionType" 1 "COB-ID" 0 "Highest sub-index supported" ;
VAL_ 1544 SubIndex_1800 6 "SYNC start value" 5 "Event Timer" 4 "Compatibility Entry" 3 "Inhibit Time" 2 "TransmissionType" 1 "COB-ID" 0 "Highest sub-index supported" ;
VAL_ 1544 SubIndex_1018 4 "Serial number" 3 "Revision number" 2 "Product Code" 1 "Vendor Id" 0 "Highest sub-index supported" ;
VAL_ 1544 SubIndex_1001 0 "Error Register" ;
VAL_ 1544 SubIndex_1000 0 "Device Type" ;
VAL_ 1544 Index 24579 "data_16_ints" 24578 "receive_data_buffer" 24577 "LVSS signals" 6659 "Transmit PDO Mapping Parameter 0" 6147 "Transmit PDO Communication Parameter 3" 6146 "Transmit PDO Communication Parameter 2" 6145 "Transmit PDO Communication Parameter 1" 6144 "Transmit PDO Communication Parameter 0" 4120 "Identity Object" 4097 "Error Register" 4096 "Device Type" ;
VAL_ 1544 TransferType 1 "Expedited transfer" 0 "Normal transfer" ;
VAL_ 1544 SizeIndicator 1 "Size is indicated" 0 "Size is not indicated" ;
VAL_ 1544 CCS 2 "Upload" 1 "Download" ;
VAL_ 136 ErrorCode 33360 "RPDO timeout" 33344 "Unexpected SYNC data length" 33328 "DAM MPDO not processed, destination object not available" 33312 "PDO length exceeded" 33296 "PDO not processed due to length error" 33104 "Transmit COB-ID collision" 33088 "Recovered from bus off state" 33072 "Life guard error or heartbeat error" 33056 "CAN in error passive mode" 33040 "CAN overrun (objects lost)" ;
VAL_ 1919 State 127 "PreOperational" 5 "Operational" 4 "Stopped" 0 "Bootup" ;
VAL_ 1918 State 127 "PreOperational" 5 "Operational" 4 "Stopped" 0 "Bootup" ;
VAL_ 1917 State 127 "PreOperational" 5 "Operational" 4 "Stopped" 0 "Bootup" ;
VAL_ 1916 State 127 "PreOperational" 5 "Operational" 4 "Stopped" 0 "Bootup" ;
VAL_ 1915 State 127 "PreOperational" 5 "Operational" 4 "Stopped" 0 "Bootup" ;
VAL_ 1914 State 127 "PreOperational" 5 "Operational" 4 "Stopped" 0 "Bootup" ;
VAL_ 1913 State 127 "PreOperational" 5 "Operational" 4 "Stopped" 0 "Bootup" ;
VAL_ 1912 State 127 "PreOperational" 5 "Operational" 4 "Stopped" 0 "Bootup" ;
VAL_ 1911 State 127 "PreOperational" 5 "Operational" 4 "Stopped" 0 "Bootup" ;
VAL_ 1910 State 127 "PreOperational" 5 "Operational" 4 "Stopped" 0 "Bootup" ;
VAL_ 1909 State 127 "PreOperational" 5 "Operational" 4 "Stopped" 0 "Bootup" ;
VAL_ 1908 State 127 "PreOperational" 5 "Operational" 4 "Stopped" 0 "Bootup" ;
VAL_ 1907 State 127 "PreOperational" 5 "Operational" 4 "Stopped" 0 "Bootup" ;
VAL_ 1906 State 127 "PreOperational" 5 "Operational" 4 "Stopped" 0 "Bootup" ;
VAL_ 1905 State 127 "PreOperational" 5 "Operational" 4 "Stopped" 0 "Bootup" ;
VAL_ 1904 State 127 "PreOperational" 5 "Operational" 4 "Stopped" 0 "Bootup" ;
VAL_ 1903 State 127 "PreOperational" 5 "Operational" 4 "Stopped" 0 "Bootup" ;
VAL_ 1902 State 127 "PreOperational" 5 "Operational" 4 "Stopped" 0 "Bootup" ;
VAL_ 1901 State 127 "PreOperational" 5 "Operational" 4 "Stopped" 0 "Bootup" ;
VAL_ 1900 State 127 "PreOperational" 5 "Operational" 4 "Stopped" 0 "Bootup" ;
VAL_ 1899 State 127 "PreOperational" 5 "Operational" 4 "Stopped" 0 "Bootup" ;
VAL_ 1898 State 127 "PreOperational" 5 "Operational" 4 "Stopped" 0 "Bootup" ;
VAL_ 1897 State 127 "PreOperational" 5 "Operational" 4 "Stopped" 0 "Bootup" ;
VAL_ 1896 State 127 "PreOperational" 5 "Operational" 4 "Stopped" 0 "Bootup" ;
VAL_ 1895 State 127 "PreOperational" 5 "Operational" 4 "Stopped" 0 "Bootup" ;
VAL_ 1894 State 127 "PreOperational" 5 "Operational" 4 "Stopped" 0 "Bootup" ;
VAL_ 1893 State 127 "PreOperational" 5 "Operational" 4 "Stopped" 0 "Bootup" ;
VAL_ 1892 State 127 "PreOperational" 5 "Operational" 4 "Stopped" 0 "Bootup" ;
VAL_ 1891 State 127 "PreOperational" 5 "Operational" 4 "Stopped" 0 "Bootup" ;
VAL_ 1890 State 127 "PreOperational" 5 "Operational" 4 "Stopped" 0 "Bootup" ;
VAL_ 1889 State 127 "PreOperational" 5 "Operational" 4 "Stopped" 0 "Bootup" ;
VAL_ 1888 State 127 "PreOperational" 5 "Operational" 4 "Stopped" 0 "Bootup" ;
VAL_ 1887 State 127 "PreOperational" 5 "Operational" 4 "Stopped" 0 "Bootup" ;
VAL_ 1886 State 127 "PreOperational" 5 "Operational" 4 "Stopped" 0 "Bootup" ;
VAL_ 1885 State 127 "PreOperational" 5 "Operational" 4 "Stopped" 0 "Bootup" ;
VAL_ 1884 State 127 "PreOperational" 5 "Operational" 4 "Stopped" 0 "Bootup" ;
VAL_ 1883 State 127 "PreOperational" 5 "Operational" 4 "Stopped" 0 "Bootup" ;
VAL_ 1882 State 127 "PreOperational" 5 "Operational" 4 "Stopped" 0 "Bootup" ;
VAL_ 1881 State 127 "PreOperational" 5 "Operational" 4 "Stopped" 0 "Bootup" ;
VAL_ 1880 State 127 "PreOperational" 5 "Operational" 4 "Stopped" 0 "Bootup" ;
VAL_ 1879 State 127 "PreOperational" 5 "Operational" 4 "Stopped" 0 "Bootup" ;
VAL_ 1878 State 127 "PreOperational" 5 "Operational" 4 "Stopped" 0 "Bootup" ;
VAL_ 1877 State 127 "PreOperational" 5 "Operational" 4 "Stopped" 0 "Bootup" ;
VAL_ 1876 State 127 "PreOperational" 5 "Operational" 4 "Stopped" 0 "Bootup" ;
VAL_ 1875 State 127 "PreOperational" 5 "Operational" 4 "Stopped" 0 "Bootup" ;
VAL_ 1874 State 127 "PreOperational" 5 "Operational" 4 "Stopped" 0 "Bootup" ;
VAL_ 1873 State 127 "PreOperational" 5 "Operational" 4 "Stopped" 0 "Bootup" ;
VAL_ 1872 State 127 "PreOperational" 5 "Operational" 4 "Stopped" 0 "Bootup" ;
VAL_ 1871 State 127 "PreOperational" 5 "Operational" 4 "Stopped" 0 "Bootup" ;
VAL_ 1870 State 127 "PreOperational" 5 "Operational" 4 "Stopped" 0 "Bootup" ;
VAL_ 1869 State 127 "PreOperational" 5 "Operational" 4 "Stopped" 0 "Bootup" ;
VAL_ 1868 State 127 "PreOperational" 5 "Operational" 4 "Stopped" 0 "Bootup" ;
VAL_ 1867 State 127 "PreOperational" 5 "Operational" 4 "Stopped" 0 "Bootup" ;

SG_MUL_VAL_ 1416 Joe_6003_04 SubIndex_6003 4-4;
SG_MUL_VAL_ 1416 Currly_6003_03 SubIndex_6003 3-3;
SG_MUL_VAL_ 1416 Moe_6003_02 SubIndex_6003 2-2;
SG_MUL_VAL_ 1416 Bob_6003_01 SubIndex_6003 1-1;
SG_MUL_VAL_ 1416 UC_STATE_6003_00 SubIndex_6003 0-0;
SG_MUL_VAL_ 1416 SubIndex_6003 Index 24579-24579;
SG_MUL_VAL_ 1416 Harp_Bit_3_6002_03 SubIndex_6002 3-3;
SG_MUL_VAL_ 1416 Harp_Bit_2_6002_02 SubIndex_6002 2-2;
SG_MUL_VAL_ 1416 Harp_Bit_1_6002_01 SubIndex_6002 1-1;
SG_MUL_VAL_ 1416 Harp_Bit_0_6002_00 SubIndex_6002 0-0;
SG_MUL_VAL_ 1416 SubIndex_6002 Index 24578-24578;
SG_MUL_VAL_ 1416 Throttle_6001_03 SubIndex_6001 3-3;
SG_MUL_VAL_ 1416 Start_6001_02 SubIndex_6001 2-2;
SG_MUL_VAL_ 1416 Brake_6001_01 SubIndex_6001 1-1;
SG_MUL_VAL_ 1416 Forward_Enable_6001_00 SubIndex_6001 0-0;
SG_MUL_VAL_ 1416 SubIndex_6001 Index 24577-24577;
SG_MUL_VAL_ 1416 PDOMapEntry_1A03_01 SubIndex_1A03 1-1;
SG_MUL_VAL_ 1416 NrOfEntries_1_1A03_00 SubIndex_1A03 0-0;
SG_MUL_VAL_ 1416 SubIndex_1A03 Index 6659-6659;
SG_MUL_VAL_ 1416 Transmit_PDO_Mapping_Parameter_0 SubIndex_1A02 4-4;
SG_MUL_VAL_ 1416 PDOMapEntry_1A02_03 SubIndex_1A02 3-3;
SG_MUL_VAL_ 1416 PDOMapEntry_1A02_02 SubIndex_1A02 2-2;
SG_MUL_VAL_ 1416 PDOMapEntry_1A02_01 SubIndex_1A02 1-1;
SG_MUL_VAL_ 1416 NrOfEntries_1_1A02_00 SubIndex_1A02 0-0;
SG_MUL_VAL_ 1416 SubIndex_1A02 Index 6658-6658;
SG_MUL_VAL_ 1416 Transmit_PDO_Mapping_Parame_0000 SubIndex_1A01 4-4;
SG_MUL_VAL_ 1416 PDOMapEntry_1A01_03 SubIndex_1A01 3-3;
SG_MUL_VAL_ 1416 PDOMapEntry_1A01_02 SubIndex_1A01 2-2;
SG_MUL_VAL_ 1416 PDOMapEntry_1A01_01 SubIndex_1A01 1-1;
SG_MUL_VAL_ 1416 NrOfEntries_1_1A01_00 SubIndex_1A01 0-0;
SG_MUL_VAL_ 1416 SubIndex_1A01 Index 6657-6657;
SG_MUL_VAL_ 1416 Transmit_PDO_Mapping_Parame_0001 SubIndex_1A00 4-4;
SG_MUL_VAL_ 1416 Transmit_PDO_Mapping_Parame_0002 SubIndex_1A00 3-3;
SG_MUL_VAL_ 1416 PDOMapEntry_2_1A00_02 SubIndex_1A00 2-2;
SG_MUL_VAL_ 1416 PDOMapEntry_1_1A00_01 SubIndex_1A00 1-1;
SG_MUL_VAL_ 1416 NrOfEntries_1_1A00_00 SubIndex_1A00 0-0;
SG_MUL_VAL_ 1416 SubIndex_1A00 Index 6656-6656;
SG_MUL_VAL_ 1416 SYNC_start_value_1803_06 SubIndex_1803 6-6;
SG_MUL_VAL_ 1416 Event_Timer_1803_05 SubIndex_1803 5-5;
SG_MUL_VAL_ 1416 Compatibility_Entry_1803_04 SubIndex_1803 4-4;
SG_MUL_VAL_ 1416 Inhibit_Time_1803_03 SubIndex_1803 3-3;
SG_MUL_VAL_ 1416 TransmissionType_1803_02 SubIndex_1803 2-2;
SG_MUL_VAL_ 1416 COB_ID_1803_01 SubIndex_1803 1-1;
SG_MUL_VAL_ 1416 Highest_sub_index_supported_1803 SubIndex_1803 0-0;
SG_MUL_VAL_ 1416 SubIndex_1803 Index 6147-6147;
SG_MUL_VAL_ 1416 SYNC_start_value_1802_06 SubIndex_1802 6-6;
SG_MUL_VAL_ 1416 Event_Timer_1802_05 SubIndex_1802 5-5;
SG_MUL_VAL_ 1416 Compatibility_Entry_1802_04 SubIndex_1802 4-4;
SG_MUL_VAL_ 1416 Inhibit_Time_1802_03 SubIndex_1802 3-3;
SG_MUL_VAL_ 1416 TransmissionType_1802_02 SubIndex_1802 2-2;
SG_MUL_VAL_ 1416 COB_ID_1802_01 SubIndex_1802 1-1;
SG_MUL_VAL_ 1416 Highest_sub_index_supported_1802 SubIndex_1802 0-0;
SG_MUL_VAL_ 1416 SubIndex_1802 Index 6146-6146;
SG_MUL_VAL_ 1416 SYNC_start_value_1801_06 SubIndex_1801 6-6;
SG_MUL_VAL_ 1416 Event_Timer_1801_05 SubIndex_1801 5-5;
SG_MUL_VAL_ 1416 Compatibility_Entry_1801_04 SubIndex_1801 4-4;
SG_MUL_VAL_ 1416 Inhibit_Time_1801_03 SubIndex_1801 3-3;
SG_MUL_VAL_ 1416 TransmissionType_1801_02 SubIndex_1801 2-2;
SG_MUL_VAL_ 1416 COB_ID_1801_01 SubIndex_1801 1-1;
SG_MUL_VAL_ 1416 Highest_sub_index_supported_1801 SubIndex_1801 0-0;
SG_MUL_VAL_ 1416 SubIndex_1801 Index 6145-6145;
SG_MUL_VAL_ 1416 SYNC_start_value_1800_06 SubIndex_1800 6-6;
SG_MUL_VAL_ 1416 Event_Timer_1800_05 SubIndex_1800 5-5;
SG_MUL_VAL_ 1416 Compatibility_Entry_1800_04 SubIndex_1800 4-4;
SG_MUL_VAL_ 1416 Inhibit_Time_1800_03 SubIndex_1800 3-3;
SG_MUL_VAL_ 1416 TransmissionType_1800_02 SubIndex_1800 2-2;
SG_MUL_VAL_ 1416 COB_ID_1800_01 SubIndex_1800 1-1;
SG_MUL_VAL_ 1416 Highest_sub_index_supported_1800 SubIndex_1800 0-0;
SG_MUL_VAL_ 1416 SubIndex_1800 Index 6144-6144;
SG_MUL_VAL_ 1416 Serial_number_1018_04 SubIndex_1018 4-4;
SG_MUL_VAL_ 1416 Revision_number_1018_03 SubIndex_1018 3-3;
SG_MUL_VAL_ 1416 Product_Code_1018_02 SubIndex_1018 2-2;
SG_MUL_VAL_ 1416 Vendor_Id_1018_01 SubIndex_1018 1-1;
SG_MUL_VAL_ 1416 Highest_sub_index_supported_1018 SubIndex_1018 0-0;
SG_MUL_VAL_ 1416 SubIndex_1018 Index 4120-4120;
SG_MUL_VAL_ 1416 Error_Register_1001 SubIndex_1001 0-0;
SG_MUL_VAL_ 1416 SubIndex_1001 Index 4097-4097;
SG_MUL_VAL_ 1416 Device_Type_1000 SubIndex_1000 0-0;
SG_MUL_VAL_ 1416 SubIndex_1000 Index 4096-4096;
SG_MUL_VAL_ 1416 Index TransferType 1-1;
SG_MUL_VAL_ 1416 TransferType SCS 1-2;
SG_MUL_VAL_ 1416 NotUsedBytes SCS 1-2;
SG_MUL_VAL_ 1416 SizeIndicator SCS 1-2;
SG_MUL_VAL_ 1544 Joe_6003_04 SubIndex_6003 4-4;
SG_MUL_VAL_ 1544 Currly_6003_03 SubIndex_6003 3-3;
SG_MUL_VAL_ 1544 Moe_6003_02 SubIndex_6003 2-2;
SG_MUL_VAL_ 1544 Bob_6003_01 SubIndex_6003 1-1;
SG_MUL_VAL_ 1544 UC_STATE_6003_00 SubIndex_6003 0-0;
SG_MUL_VAL_ 1544 SubIndex_6003 Index 24579-24579;
SG_MUL_VAL_ 1544 Harp_Bit_3_6002_03 SubIndex_6002 3-3;
SG_MUL_VAL_ 1544 Harp_Bit_2_6002_02 SubIndex_6002 2-2;
SG_MUL_VAL_ 1544 Harp_Bit_1_6002_01 SubIndex_6002 1-1;
SG_MUL_VAL_ 1544 Harp_Bit_0_6002_00 SubIndex_6002 0-0;
SG_MUL_VAL_ 1544 SubIndex_6002 Index 24578-24578;
SG_MUL_VAL_ 1544 Throttle_6001_03 SubIndex_6001 3-3;
SG_MUL_VAL_ 1544 Start_6001_02 SubIndex_6001 2-2;
SG_MUL_VAL_ 1544 Brake_6001_01 SubIndex_6001 1-1;
SG_MUL_VAL_ 1544 Forward_Enable_6001_00 SubIndex_6001 0-0;
SG_MUL_VAL_ 1544 SubIndex_6001 Index 24577-24577;
SG_MUL_VAL_ 1544 PDOMapEntry_1A03_01 SubIndex_1A03 1-1;
SG_MUL_VAL_ 1544 NrOfEntries_1_1A03_00 SubIndex_1A03 0-0;
SG_MUL_VAL_ 1544 SubIndex_1A03 Index 6659-6659;
SG_MUL_VAL_ 1544 Transmit_PDO_Mapping_Parame_0003 SubIndex_1A02 4-4;
SG_MUL_VAL_ 1544 PDOMapEntry_1A02_03 SubIndex_1A02 3-3;
SG_MUL_VAL_ 1544 PDOMapEntry_1A02_02 SubIndex_1A02 2-2;
SG_MUL_VAL_ 1544 PDOMapEntry_1A02_01 SubIndex_1A02 1-1;
SG_MUL_VAL_ 1544 NrOfEntries_1_1A02_00 SubIndex_1A02 0-0;
SG_MUL_VAL_ 1544 SubIndex_1A02 Index 6658-6658;
SG_MUL_VAL_ 1544 Transmit_PDO_Mapping_Parame_0004 SubIndex_1A01 4-4;
SG_MUL_VAL_ 1544 PDOMapEntry_1A01_03 SubIndex_1A01 3-3;
SG_MUL_VAL_ 1544 PDOMapEntry_1A01_02 SubIndex_1A01 2-2;
SG_MUL_VAL_ 1544 PDOMapEntry_1A01_01 SubIndex_1A01 1-1;
SG_MUL_VAL_ 1544 NrOfEntries_1_1A01_00 SubIndex_1A01 0-0;
SG_MUL_VAL_ 1544 SubIndex_1A01 Index 6657-6657;
SG_MUL_VAL_ 1544 Transmit_PDO_Mapping_Parame_0005 SubIndex_1A00 4-4;
SG_MUL_VAL_ 1544 Transmit_PDO_Mapping_Parame_0006 SubIndex_1A00 3-3;
SG_MUL_VAL_ 1544 PDOMapEntry_2_1A00_02 SubIndex_1A00 2-2;
SG_MUL_VAL_ 1544 PDOMapEntry_1_1A00_01 SubIndex_1A00 1-1;
SG_MUL_VAL_ 1544 NrOfEntries_1_1A00_00 SubIndex_1A00 0-0;
SG_MUL_VAL_ 1544 SubIndex_1A00 Index 6656-6656;
SG_MUL_VAL_ 1544 SYNC_start_value_1803_06 SubIndex_1803 6-6;
SG_MUL_VAL_ 1544 Event_Timer_1803_05 SubIndex_1803 5-5;
SG_MUL_VAL_ 1544 Compatibility_Entry_1803_04 SubIndex_1803 4-4;
SG_MUL_VAL_ 1544 Inhibit_Time_1803_03 SubIndex_1803 3-3;
SG_MUL_VAL_ 1544 TransmissionType_1803_02 SubIndex_1803 2-2;
SG_MUL_VAL_ 1544 COB_ID_1803_01 SubIndex_1803 1-1;
SG_MUL_VAL_ 1544 Highest_sub_index_supported_0000 SubIndex_1803 0-0;
SG_MUL_VAL_ 1544 SubIndex_1803 Index 6147-6147;
SG_MUL_VAL_ 1544 SYNC_start_value_1802_06 SubIndex_1802 6-6;
SG_MUL_VAL_ 1544 Event_Timer_1802_05 SubIndex_1802 5-5;
SG_MUL_VAL_ 1544 Compatibility_Entry_1802_04 SubIndex_1802 4-4;
SG_MUL_VAL_ 1544 Inhibit_Time_1802_03 SubIndex_1802 3-3;
SG_MUL_VAL_ 1544 TransmissionType_1802_02 SubIndex_1802 2-2;
SG_MUL_VAL_ 1544 COB_ID_1802_01 SubIndex_1802 1-1;
SG_MUL_VAL_ 1544 Highest_sub_index_supported_0001 SubIndex_1802 0-0;
SG_MUL_VAL_ 1544 SubIndex_1802 Index 6146-6146;
SG_MUL_VAL_ 1544 SYNC_start_value_1801_06 SubIndex_1801 6-6;
SG_MUL_VAL_ 1544 Event_Timer_1801_05 SubIndex_1801 5-5;
SG_MUL_VAL_ 1544 Compatibility_Entry_1801_04 SubIndex_1801 4-4;
SG_MUL_VAL_ 1544 Inhibit_Time_1801_03 SubIndex_1801 3-3;
SG_MUL_VAL_ 1544 TransmissionType_1801_02 SubIndex_1801 2-2;
SG_MUL_VAL_ 1544 COB_ID_1801_01 SubIndex_1801 1-1;
SG_MUL_VAL_ 1544 Highest_sub_index_supported_0002 SubIndex_1801 0-0;
SG_MUL_VAL_ 1544 SubIndex_1801 Index 6145-6145;
SG_MUL_VAL_ 1544 SYNC_start_value_1800_06 SubIndex_1800 6-6;
SG_MUL_VAL_ 1544 Event_Timer_1800_05 SubIndex_1800 5-5;
SG_MUL_VAL_ 1544 Compatibility_Entry_1800_04 SubIndex_1800 4-4;
SG_MUL_VAL_ 1544 Inhibit_Time_1800_03 SubIndex_1800 3-3;
SG_MUL_VAL_ 1544 TransmissionType_1800_02 SubIndex_1800 2-2;
SG_MUL_VAL_ 1544 COB_ID_1800_01 SubIndex_1800 1-1;
SG_MUL_VAL_ 1544 Highest_sub_index_supported_0003 SubIndex_1800 0-0;
SG_MUL_VAL_ 1544 SubIndex_1800 Index 6144-6144;
SG_MUL_VAL_ 1544 Serial_number_1018_04 SubIndex_1018 4-4;
SG_MUL_VAL_ 1544 Revision_number_1018_03 SubIndex_1018 3-3;
SG_MUL_VAL_ 1544 Product_Code_1018_02 SubIndex_1018 2-2;
SG_MUL_VAL_ 1544 Vendor_Id_1018_01 SubIndex_1018 1-1;
SG_MUL_VAL_ 1544 Highest_sub_index_supported_0004 SubIndex_1018 0-0;
SG_MUL_VAL_ 1544 SubIndex_1018 Index 4120-4120;
SG_MUL_VAL_ 1544 Error_Register_1001 SubIndex_1001 0-0;
SG_MUL_VAL_ 1544 SubIndex_1001 Index 4097-4097;
SG_MUL_VAL_ 1544 Device_Type_1000 SubIndex_1000 0-0;
SG_MUL_VAL_ 1544 SubIndex_1000 Index 4096-4096;
SG_MUL_VAL_ 1544 Index TransferType 1-1;
SG_MUL_VAL_ 1544 TransferType CCS 1-2;
SG_MUL_VAL_ 1544 NotUsedBytes CCS 1-2;
SG_MUL_VAL_ 1544 SizeIndicator CCS 1-2;
